VERSION ""

NS_ :

BS_:

BU_: NBICU SBICU NBCMU SBCMU DAPP Vector_XXX

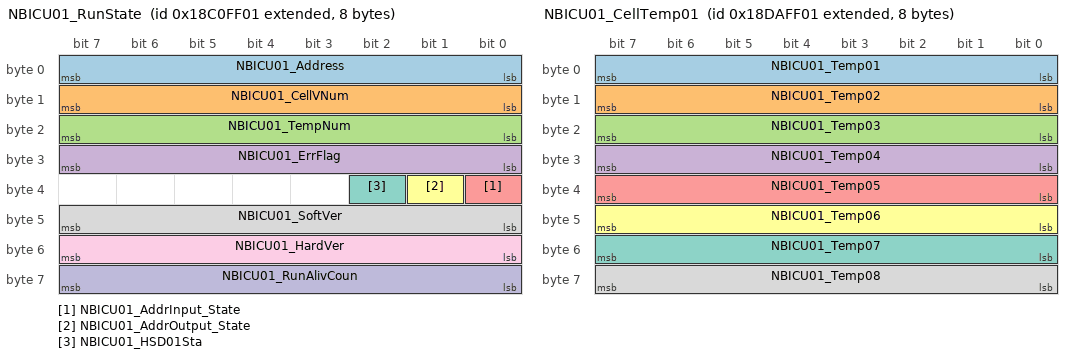
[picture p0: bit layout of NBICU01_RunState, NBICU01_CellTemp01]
BO_ 2562785025 NBICU01_RunState: 8 NBICU
 SG_ NBICU01_Address : 7|8@0+ (1,0) [0|255] ""  NBCMU
 SG_ NBICU01_CellVNum : 15|8@0+ (1,0) [0|255] ""  NBCMU
 SG_ NBICU01_TempNum : 23|8@0+ (1,0) [0|255] ""  NBCMU
 SG_ NBICU01_ErrFlag : 31|8@0+ (1,0) [0|255] ""  NBCMU
 SG_ NBICU01_AddrInput_State : 32|1@0+ (1,0) [0|1] ""  NBCMU
 SG_ NBICU01_AddrOutput_State : 33|1@0+ (1,0) [0|1] ""  NBCMU
 SG_ NBICU01_HSD01Sta : 34|1@0+ (1,0) [0|1] ""  NBCMU
 SG_ NBICU01_SoftVer : 47|8@0+ (1,0) [0|255] ""  NBCMU
 SG_ NBICU01_HardVer : 55|8@0+ (1,0) [0|255] ""  NBCMU
 SG_ NBICU01_RunAlivCoun : 63|8@0+ (1,0) [0|255] ""  NBCMU

BO_ 2562850561 NBICU01_VoltExtremeInfo: 8 NBICU
 SG_ NBICU01_CellVoltMax : 7|16@0+ (1,0) [0|65535] "mV"  NBCMU,SBCMU
 SG_ NBICU01_CellVoltMin : 23|16@0+ (1,0) [0|65535] "mV"  NBCMU,SBCMU
 SG_ NBICU01_CellVoltMaxCode : 39|8@0+ (1,0) [0|255] ""  NBCMU,SBCMU
 SG_ NBICU01_CellVoltMinCode : 47|8@0+ (1,0) [0|255] ""  NBCMU,SBCMU
 SG_ NBICU01_CellSumVolt : 55|16@0+ (0.1,0) [0|6553.5] "V"  NBCMU,SBCMU

BO_ 2562916097 NBICU01_TempExtremeInfo: 8 NBICU
 SG_ NBICU01_CellTempMax : 7|8@0+ (1,-40) [-40|215] "℃"  NBCMU,SBCMU
 SG_ NBICU01_CellTempMin : 15|8@0+ (1,-40) [-40|215] "℃"  NBCMU,SBCMU
 SG_ NBICU01_CellTempAvg : 23|8@0+ (1,-40) [-40|215] "℃"  NBCMU,SBCMU
 SG_ NBICU01_CellTempMaxCode : 31|8@0+ (1,0) [0|255] ""  NBCMU,SBCMU
 SG_ NBICU01_CellTempMinCode : 39|8@0+ (1,0) [0|255] ""  NBCMU,SBCMU
 SG_ NBICU01_SupplyVolt : 40|9@0+ (0.1,0) [0|51.1] "V"  NBCMU,SBCMU
 SG_ NBICU01_PCB_Temp : 63|8@0+ (1,-40) [-40|215] "℃"  NBCMU,SBCMU

BO_ 2562981633 NBICU01_BalState: 8 NBICU
 SG_ NBICU01_Cell0108BalaSta : 7|8@0+ (1,0) [0|255] ""  NBCMU
 SG_ NBICU01_Cell0916BalaSta : 15|8@0+ (1,0) [0|255] ""  NBCMU
 SG_ NBICU01_Cell1724BalaSta : 23|8@0+ (1,0) [0|255] ""  NBCMU
 SG_ NBICU01_Cell2532BalaSta : 31|8@0+ (1,0) [0|255] ""  NBCMU
 SG_ NBICU01_Cell3336BalaSta : 35|4@0+ (1,0) [0|15] ""  NBCMU
 SG_ NBICU01_SysSOH : 47|8@0+ (1,0) [0|100] "%"  NBCMU
 SG_ NBICU01_CycleTime : 55|16@0+ (1,0) [0|65535] ""  NBCMU

BO_ 2563899137 NBICU01_CellVotlage01: 8 NBICU
 SG_ NBICU01_Cell01Volt : 7|16@0+ (1,0) [0|65535] "mV"  NBCMU
 SG_ NBICU01_Cell02Volt : 23|16@0+ (1,0) [0|65535] "mV"  NBCMU
 SG_ NBICU01_Cell03Volt : 39|16@0+ (1,0) [0|65535] "mV"  NBCMU
 SG_ NBICU01_Cell04Volt : 55|16@0+ (1,0) [0|65535] "mV"  NBCMU

BO_ 2563964673 NBICU01_CellVotlage02: 8 NBICU
 SG_ NBICU01_Cell05Volt : 7|16@0+ (1,0) [0|65535] "mV"  NBCMU
 SG_ NBICU01_Cell06Volt : 23|16@0+ (1,0) [0|65535] "mV"  NBCMU
 SG_ NBICU01_Cell07Volt : 39|16@0+ (1,0) [0|65535] "mV"  NBCMU
 SG_ NBICU01_Cell08Volt : 55|16@0+ (1,0) [0|65535] "mV"  NBCMU

BO_ 2564030209 NBICU01_CellVotlage03: 8 NBICU
 SG_ NBICU01_Cell09Volt : 7|16@0+ (1,0) [0|65535] "mV"  NBCMU
 SG_ NBICU01_Cell10Volt : 23|16@0+ (1,0) [0|65535] "mV"  NBCMU
 SG_ NBICU01_Cell11Volt : 39|16@0+ (1,0) [0|65535] "mV"  NBCMU
 SG_ NBICU01_Cell12Volt : 55|16@0+ (1,0) [0|65535] "mV"  NBCMU

BO_ 2564095745 NBICU01_CellVotlage04: 8 NBICU
 SG_ NBICU01_Cell13Volt : 7|16@0+ (1,0) [0|65535] "mV"  NBCMU
 SG_ NBICU01_Cell14Volt : 23|16@0+ (1,0) [0|65535] "mV"  NBCMU
 SG_ NBICU01_Cell15Volt : 39|16@0+ (1,0) [0|65535] "mV"  NBCMU
 SG_ NBICU01_Cell16Volt : 55|16@0+ (1,0) [0|65535] "mV"  NBCMU

BO_ 2564161281 NBICU01_CellVotlage05: 8 NBICU
 SG_ NBICU01_Cell17Volt : 7|16@0+ (1,0) [0|65535] "mV"  NBCMU
 SG_ NBICU01_Cell18Volt : 23|16@0+ (1,0) [0|65535] "mV"  NBCMU
 SG_ NBICU01_Cell19Volt : 39|16@0+ (1,0) [0|65535] "mV"  NBCMU
 SG_ NBICU01_Cell20Volt : 55|16@0+ (1,0) [0|65535] "mV"  NBCMU

BO_ 2564226817 NBICU01_CellVotlage06: 8 NBICU
 SG_ NBICU01_Cell21Volt : 7|16@0+ (1,0) [0|65535] "mV"  NBCMU
 SG_ NBICU01_Cell22Volt : 23|16@0+ (1,0) [0|65535] "mV"  NBCMU
 SG_ NBICU01_Cell23Volt : 39|16@0+ (1,0) [0|65535] "mV"  NBCMU
 SG_ NBICU01_Cell24Volt : 55|16@0+ (1,0) [0|65535] "mV"  NBCMU

BO_ 2564292353 NBICU01_CellVotlage07: 8 NBICU
 SG_ NBICU01_Cell25Volt : 7|16@0+ (1,0) [0|65535] "mV"  NBCMU
 SG_ NBICU01_Cell26Volt : 23|16@0+ (1,0) [0|65535] "mV"  NBCMU
 SG_ NBICU01_Cell27Volt : 39|16@0+ (1,0) [0|65535] "mV"  NBCMU
 SG_ NBICU01_Cell28Volt : 55|16@0+ (1,0) [0|65535] "mV"  NBCMU

BO_ 2564357889 NBICU01_CellVotlage08: 8 NBICU
 SG_ NBICU01_Cell29Volt : 7|16@0+ (1,0) [0|65535] "mV"  NBCMU
 SG_ NBICU01_Cell30Volt : 23|16@0+ (1,0) [0|65535] "mV"  NBCMU
 SG_ NBICU01_Cell31Volt : 39|16@0+ (1,0) [0|65535] "mV"  NBCMU
 SG_ NBICU01_Cell32Volt : 55|16@0+ (1,0) [0|65535] "mV"  NBCMU

BO_ 2564423425 NBICU01_CellVotlage09: 8 NBICU
 SG_ NBICU01_Cell33Volt : 7|16@0+ (1,0) [0|65535] "mV"  NBCMU
 SG_ NBICU01_Cell34Volt : 23|16@0+ (1,0) [0|65535] "mV"  NBCMU
 SG_ NBICU01_Cell35Volt : 39|16@0+ (1,0) [0|65535] "mV"  NBCMU
 SG_ NBICU01_Cell36Volt : 55|16@0+ (1,0) [0|65535] "mV"  NBCMU

BO_ 2564488961 NBICU01_CellTemp01: 8 NBICU
 SG_ NBICU01_Temp01 : 7|8@0+ (1,-40) [-40|215] "℃"  NBCMU
 SG_ NBICU01_Temp02 : 15|8@0+ (1,-40) [-40|215] "℃"  NBCMU
 SG_ NBICU01_Temp03 : 23|8@0+ (1,-40) [-40|215] "℃"  NBCMU
 SG_ NBICU01_Temp04 : 31|8@0+ (1,-40) [-40|215] "℃"  NBCMU
 SG_ NBICU01_Temp05 : 39|8@0+ (1,-40) [-40|215] "℃"  NBCMU
 SG_ NBICU01_Temp06 : 47|8@0+ (1,-40) [-40|215] "℃"  NBCMU
 SG_ NBICU01_Temp07 : 55|8@0+ (1,-40) [-40|215] "℃"  NBCMU
 SG_ NBICU01_Temp08 : 63|8@0+ (1,-40) [-40|215] "℃"  NBCMU

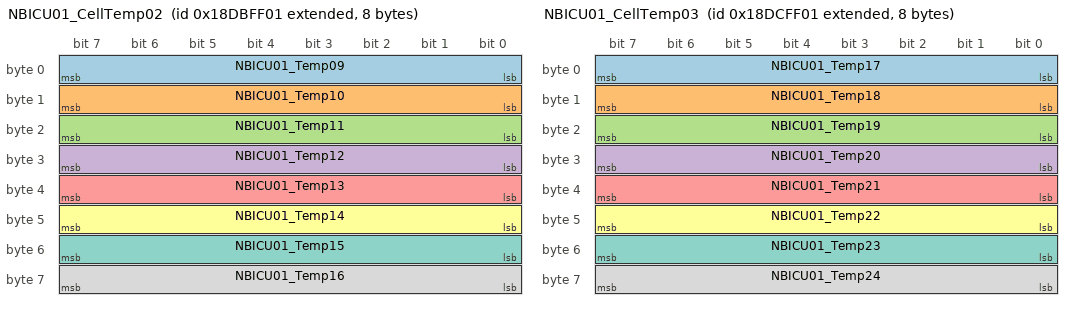
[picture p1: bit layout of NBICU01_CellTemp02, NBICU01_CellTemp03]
BO_ 2564554497 NBICU01_CellTemp02: 8 NBICU
 SG_ NBICU01_Temp09 : 7|8@0+ (1,-40) [-40|215] "℃"  NBCMU
 SG_ NBICU01_Temp10 : 15|8@0+ (1,-40) [-40|215] "℃"  NBCMU
 SG_ NBICU01_Temp11 : 23|8@0+ (1,-40) [-40|215] "℃"  NBCMU
 SG_ NBICU01_Temp12 : 31|8@0+ (1,-40) [-40|215] "℃"  NBCMU
 SG_ NBICU01_Temp13 : 39|8@0+ (1,-40) [-40|215] "℃"  NBCMU
 SG_ NBICU01_Temp14 : 47|8@0+ (1,-40) [-40|215] "℃"  NBCMU
 SG_ NBICU01_Temp15 : 55|8@0+ (1,-40) [-40|215] "℃"  NBCMU
 SG_ NBICU01_Temp16 : 63|8@0+ (1,-40) [-40|215] "℃"  NBCMU

BO_ 2564620033 NBICU01_CellTemp03: 8 NBICU
 SG_ NBICU01_Temp17 : 7|8@0+ (1,-40) [-40|215] "℃"  NBCMU
 SG_ NBICU01_Temp18 : 15|8@0+ (1,-40) [-40|215] "℃"  NBCMU
 SG_ NBICU01_Temp19 : 23|8@0+ (1,-40) [-40|215] "℃"  NBCMU
 SG_ NBICU01_Temp20 : 31|8@0+ (1,-40) [-40|215] "℃"  NBCMU
 SG_ NBICU01_Temp21 : 39|8@0+ (1,-40) [-40|215] "℃"  NBCMU
 SG_ NBICU01_Temp22 : 47|8@0+ (1,-40) [-40|215] "℃"  NBCMU
 SG_ NBICU01_Temp23 : 55|8@0+ (1,-40) [-40|215] "℃"  NBCMU
 SG_ NBICU01_Temp24 : 63|8@0+ (1,-40) [-40|215] "℃"  NBCMU

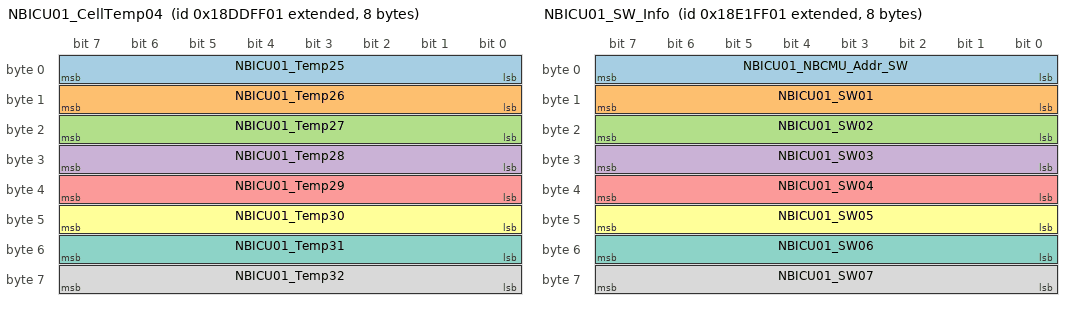
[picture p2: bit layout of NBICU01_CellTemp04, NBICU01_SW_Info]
BO_ 2564685569 NBICU01_CellTemp04: 8 NBICU
 SG_ NBICU01_Temp25 : 7|8@0+ (1,-40) [-40|215] "℃"  NBCMU
 SG_ NBICU01_Temp26 : 15|8@0+ (1,-40) [-40|215] "℃"  NBCMU
 SG_ NBICU01_Temp27 : 23|8@0+ (1,-40) [-40|215] "℃"  NBCMU
 SG_ NBICU01_Temp28 : 31|8@0+ (1,-40) [-40|215] "℃"  NBCMU
 SG_ NBICU01_Temp29 : 39|8@0+ (1,-40) [-40|215] "℃"  NBCMU
 SG_ NBICU01_Temp30 : 47|8@0+ (1,-40) [-40|215] "℃"  NBCMU
 SG_ NBICU01_Temp31 : 55|8@0+ (1,-40) [-40|215] "℃"  NBCMU
 SG_ NBICU01_Temp32 : 63|8@0+ (1,-40) [-40|215] "℃"  NBCMU

BO_ 2564751105 NBICU01_CellTemp05: 8 NBICU
 SG_ NBICU01_Temp33 : 7|8@0+ (1,-40) [-40|215] "℃"  NBCMU
 SG_ NBICU01_Temp34 : 15|8@0+ (1,-40) [-40|215] "℃"  NBCMU
 SG_ NBICU01_Temp35 : 23|8@0+ (1,-40) [-40|215] "℃"  NBCMU
 SG_ NBICU01_Temp36 : 31|8@0+ (1,-40) [-40|215] "℃"  NBCMU

BO_ 2564947713 NBICU01_SW_Info: 8 NBICU
 SG_ NBICU01_NBCMU_Addr_SW : 7|8@0+ (1,0) [0|255] ""  NBCMU
 SG_ NBICU01_SW01 : 15|8@0+ (1,0) [0|255] ""  NBCMU
 SG_ NBICU01_SW02 : 23|8@0+ (1,0) [0|255] ""  NBCMU
 SG_ NBICU01_SW03 : 31|8@0+ (1,0) [0|255] ""  NBCMU
 SG_ NBICU01_SW04 : 39|8@0+ (1,0) [0|255] ""  NBCMU
 SG_ NBICU01_SW05 : 47|8@0+ (1,0) [0|255] ""  NBCMU
 SG_ NBICU01_SW06 : 55|8@0+ (1,0) [0|255] ""  NBCMU
 SG_ NBICU01_SW07 : 63|8@0+ (1,0) [0|255] ""  NBCMU

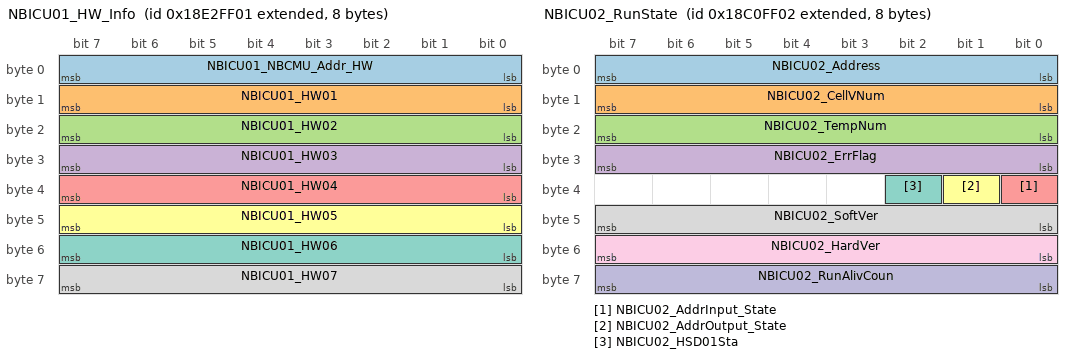
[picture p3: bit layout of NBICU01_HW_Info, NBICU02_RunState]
BO_ 2565013249 NBICU01_HW_Info: 8 NBICU
 SG_ NBICU01_NBCMU_Addr_HW : 7|8@0+ (1,0) [0|255] ""  NBCMU
 SG_ NBICU01_HW01 : 15|8@0+ (1,0) [0|255] ""  NBCMU
 SG_ NBICU01_HW02 : 23|8@0+ (1,0) [0|255] ""  NBCMU
 SG_ NBICU01_HW03 : 31|8@0+ (1,0) [0|255] ""  NBCMU
 SG_ NBICU01_HW04 : 39|8@0+ (1,0) [0|255] ""  NBCMU
 SG_ NBICU01_HW05 : 47|8@0+ (1,0) [0|255] ""  NBCMU
 SG_ NBICU01_HW06 : 55|8@0+ (1,0) [0|255] ""  NBCMU
 SG_ NBICU01_HW07 : 63|8@0+ (1,0) [0|255] ""  NBCMU

BO_ 2564677377 NBICU01_DiaResponse: 8 NBICU
 SG_ NBICU01_RespData : 7|64@0+ (1,0) [0|1.84467440737096E+019] ""  DAPP

BO_ 2562785026 NBICU02_RunState: 8 NBICU
 SG_ NBICU02_Address : 7|8@0+ (1,0) [0|255] ""  NBCMU
 SG_ NBICU02_CellVNum : 15|8@0+ (1,0) [0|255] ""  NBCMU
 SG_ NBICU02_TempNum : 23|8@0+ (1,0) [0|255] ""  NBCMU
 SG_ NBICU02_ErrFlag : 31|8@0+ (1,0) [0|255] ""  NBCMU
 SG_ NBICU02_AddrInput_State : 32|1@0+ (1,0) [0|1] ""  NBCMU
 SG_ NBICU02_AddrOutput_State : 33|1@0+ (1,0) [0|1] ""  NBCMU
 SG_ NBICU02_HSD01Sta : 34|1@0+ (1,0) [0|1] ""  NBCMU
 SG_ NBICU02_SoftVer : 47|8@0+ (1,0) [0|255] ""  NBCMU
 SG_ NBICU02_HardVer : 55|8@0+ (1,0) [0|255] ""  NBCMU
 SG_ NBICU02_RunAlivCoun : 63|8@0+ (1,0) [0|255] ""  NBCMU

BO_ 2562850562 NBICU02_VoltExtremeInfo: 8 NBICU
 SG_ NBICU02_CellVoltMax : 7|16@0+ (1,0) [0|65535] "mV"  NBCMU,SBCMU
 SG_ NBICU02_CellVoltMin : 23|16@0+ (1,0) [0|65535] "mV"  NBCMU,SBCMU
 SG_ NBICU02_CellVoltMaxCode : 39|8@0+ (1,0) [0|255] ""  NBCMU,SBCMU
 SG_ NBICU02_CellVoltMinCode : 47|8@0+ (1,0) [0|255] ""  NBCMU,SBCMU
 SG_ NBICU02_CellSumVolt : 55|16@0+ (0.1,0) [0|6553.5] "V"  NBCMU,SBCMU

BO_ 2562916098 NBICU02_TempExtremeInfo: 8 NBICU
 SG_ NBICU02_CellTempMax : 7|8@0+ (1,-40) [-40|215] "℃"  NBCMU,SBCMU
 SG_ NBICU02_CellTempMin : 15|8@0+ (1,-40) [-40|215] "℃"  NBCMU,SBCMU
 SG_ NBICU02_CellTempAvg : 23|8@0+ (1,-40) [-40|215] "℃"  NBCMU,SBCMU
 SG_ NBICU02_CellTempMaxCode : 31|8@0+ (1,0) [0|255] ""  NBCMU,SBCMU
 SG_ NBICU02_CellTempMinCode : 39|8@0+ (1,0) [0|255] ""  NBCMU,SBCMU
 SG_ NBICU02_SupplyVolt : 40|9@0+ (0.1,0) [0|51.1] "V"  NBCMU,SBCMU
 SG_ NBICU02_PCB_Temp : 63|8@0+ (1,-40) [-40|215] "℃"  NBCMU,SBCMU

BO_ 2562981634 NBICU02_BalState: 8 NBICU
 SG_ NBICU02_Cell0108BalaSta : 7|8@0+ (1,0) [0|255] ""  NBCMU
 SG_ NBICU02_Cell0916BalaSta : 15|8@0+ (1,0) [0|255] ""  NBCMU
 SG_ NBICU02_Cell1724BalaSta : 23|8@0+ (1,0) [0|255] ""  NBCMU
 SG_ NBICU02_Cell2532BalaSta : 31|8@0+ (1,0) [0|255] ""  NBCMU
 SG_ NBICU02_Cell3336BalaSta : 35|4@0+ (1,0) [0|15] ""  NBCMU
 SG_ NBICU02_SysSOH : 47|8@0+ (1,0) [0|100] "%"  NBCMU
 SG_ NBICU02_CycleTime : 55|16@0+ (1,0) [0|65535] ""  NBCMU

BO_ 2563899138 NBICU02_CellVotlage01: 8 NBICU
 SG_ NBICU02_Cell01Volt : 7|16@0+ (1,0) [0|65535] "mV"  NBCMU
 SG_ NBICU02_Cell02Volt : 23|16@0+ (1,0) [0|65535] "mV"  NBCMU
 SG_ NBICU02_Cell03Volt : 39|16@0+ (1,0) [0|65535] "mV"  NBCMU
 SG_ NBICU02_Cell04Volt : 55|16@0+ (1,0) [0|65535] "mV"  NBCMU

BO_ 2563964674 NBICU02_CellVotlage02: 8 NBICU
 SG_ NBICU02_Cell05Volt : 7|16@0+ (1,0) [0|65535] "mV"  NBCMU
 SG_ NBICU02_Cell06Volt : 23|16@0+ (1,0) [0|65535] "mV"  NBCMU
 SG_ NBICU02_Cell07Volt : 39|16@0+ (1,0) [0|65535] "mV"  NBCMU
 SG_ NBICU02_Cell08Volt : 55|16@0+ (1,0) [0|65535] "mV"  NBCMU

BO_ 2564030210 NBICU02_CellVotlage03: 8 NBICU
 SG_ NBICU02_Cell09Volt : 7|16@0+ (1,0) [0|65535] "mV"  NBCMU
 SG_ NBICU02_Cell10Volt : 23|16@0+ (1,0) [0|65535] "mV"  NBCMU
 SG_ NBICU02_Cell11Volt : 39|16@0+ (1,0) [0|65535] "mV"  NBCMU
 SG_ NBICU02_Cell12Volt : 55|16@0+ (1,0) [0|65535] "mV"  NBCMU

BO_ 2564095746 NBICU02_CellVotlage04: 8 NBICU
 SG_ NBICU02_Cell13Volt : 7|16@0+ (1,0) [0|65535] "mV"  NBCMU
 SG_ NBICU02_Cell14Volt : 23|16@0+ (1,0) [0|65535] "mV"  NBCMU
 SG_ NBICU02_Cell15Volt : 39|16@0+ (1,0) [0|65535] "mV"  NBCMU
 SG_ NBICU02_Cell16Volt : 55|16@0+ (1,0) [0|65535] "mV"  NBCMU

BO_ 2564161282 NBICU02_CellVotlage05: 8 NBICU
 SG_ NBICU02_Cell17Volt : 7|16@0+ (1,0) [0|65535] "mV"  NBCMU
 SG_ NBICU02_Cell18Volt : 23|16@0+ (1,0) [0|65535] "mV"  NBCMU
 SG_ NBICU02_Cell19Volt : 39|16@0+ (1,0) [0|65535] "mV"  NBCMU
 SG_ NBICU02_Cell20Volt : 55|16@0+ (1,0) [0|65535] "mV"  NBCMU

BO_ 2564226818 NBICU02_CellVotlage06: 8 NBICU
 SG_ NBICU02_Cell21Volt : 7|16@0+ (1,0) [0|65535] "mV"  NBCMU
 SG_ NBICU02_Cell22Volt : 23|16@0+ (1,0) [0|65535] "mV"  NBCMU
 SG_ NBICU02_Cell23Volt : 39|16@0+ (1,0) [0|65535] "mV"  NBCMU
 SG_ NBICU02_Cell24Volt : 55|16@0+ (1,0) [0|65535] "mV"  NBCMU

BO_ 2564292354 NBICU02_CellVotlage07: 8 NBICU
 SG_ NBICU02_Cell25Volt : 7|16@0+ (1,0) [0|65535] "mV"  NBCMU
 SG_ NBICU02_Cell26Volt : 23|16@0+ (1,0) [0|65535] "mV"  NBCMU
 SG_ NBICU02_Cell27Volt : 39|16@0+ (1,0) [0|65535] "mV"  NBCMU
 SG_ NBICU02_Cell28Volt : 55|16@0+ (1,0) [0|65535] "mV"  NBCMU

BO_ 2564357890 NBICU02_CellVotlage08: 8 NBICU
 SG_ NBICU02_Cell29Volt : 7|16@0+ (1,0) [0|65535] "mV"  NBCMU
 SG_ NBICU02_Cell30Volt : 23|16@0+ (1,0) [0|65535] "mV"  NBCMU
 SG_ NBICU02_Cell31Volt : 39|16@0+ (1,0) [0|65535] "mV"  NBCMU
 SG_ NBICU02_Cell32Volt : 55|16@0+ (1,0) [0|65535] "mV"  NBCMU

BO_ 2564423426 NBICU02_CellVotlage09: 8 NBICU
 SG_ NBICU02_Cell33Volt : 7|16@0+ (1,0) [0|65535] "mV"  NBCMU
 SG_ NBICU02_Cell34Volt : 23|16@0+ (1,0) [0|65535] "mV"  NBCMU
 SG_ NBICU02_Cell35Volt : 39|16@0+ (1,0) [0|65535] "mV"  NBCMU
 SG_ NBICU02_Cell36Volt : 55|16@0+ (1,0) [0|65535] "mV"  NBCMU

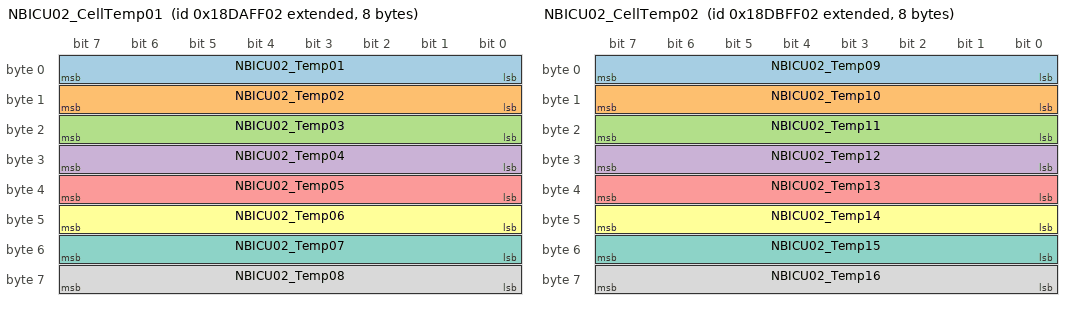
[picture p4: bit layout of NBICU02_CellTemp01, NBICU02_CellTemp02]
BO_ 2564488962 NBICU02_CellTemp01: 8 NBICU
 SG_ NBICU02_Temp01 : 7|8@0+ (1,-40) [-40|215] "℃"  NBCMU
 SG_ NBICU02_Temp02 : 15|8@0+ (1,-40) [-40|215] "℃"  NBCMU
 SG_ NBICU02_Temp03 : 23|8@0+ (1,-40) [-40|215] "℃"  NBCMU
 SG_ NBICU02_Temp04 : 31|8@0+ (1,-40) [-40|215] "℃"  NBCMU
 SG_ NBICU02_Temp05 : 39|8@0+ (1,-40) [-40|215] "℃"  NBCMU
 SG_ NBICU02_Temp06 : 47|8@0+ (1,-40) [-40|215] "℃"  NBCMU
 SG_ NBICU02_Temp07 : 55|8@0+ (1,-40) [-40|215] "℃"  NBCMU
 SG_ NBICU02_Temp08 : 63|8@0+ (1,-40) [-40|215] "℃"  NBCMU

BO_ 2564554498 NBICU02_CellTemp02: 8 NBICU
 SG_ NBICU02_Temp09 : 7|8@0+ (1,-40) [-40|215] "℃"  NBCMU
 SG_ NBICU02_Temp10 : 15|8@0+ (1,-40) [-40|215] "℃"  NBCMU
 SG_ NBICU02_Temp11 : 23|8@0+ (1,-40) [-40|215] "℃"  NBCMU
 SG_ NBICU02_Temp12 : 31|8@0+ (1,-40) [-40|215] "℃"  NBCMU
 SG_ NBICU02_Temp13 : 39|8@0+ (1,-40) [-40|215] "℃"  NBCMU
 SG_ NBICU02_Temp14 : 47|8@0+ (1,-40) [-40|215] "℃"  NBCMU
 SG_ NBICU02_Temp15 : 55|8@0+ (1,-40) [-40|215] "℃"  NBCMU
 SG_ NBICU02_Temp16 : 63|8@0+ (1,-40) [-40|215] "℃"  NBCMU

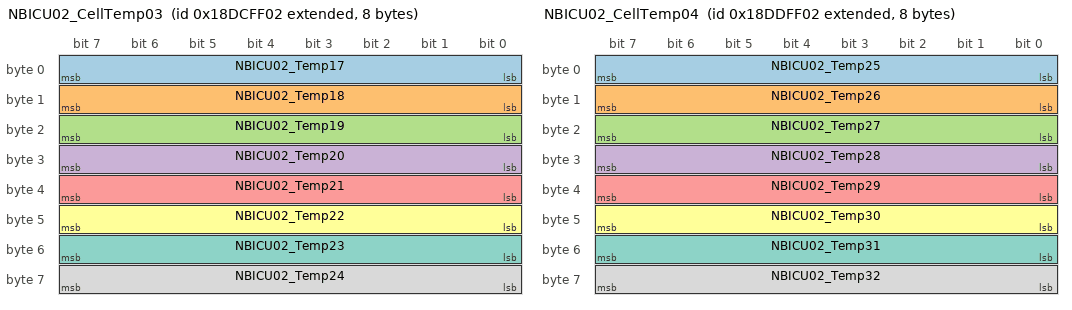
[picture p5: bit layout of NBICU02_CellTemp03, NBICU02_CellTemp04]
BO_ 2564620034 NBICU02_CellTemp03: 8 NBICU
 SG_ NBICU02_Temp17 : 7|8@0+ (1,-40) [-40|215] "℃"  NBCMU
 SG_ NBICU02_Temp18 : 15|8@0+ (1,-40) [-40|215] "℃"  NBCMU
 SG_ NBICU02_Temp19 : 23|8@0+ (1,-40) [-40|215] "℃"  NBCMU
 SG_ NBICU02_Temp20 : 31|8@0+ (1,-40) [-40|215] "℃"  NBCMU
 SG_ NBICU02_Temp21 : 39|8@0+ (1,-40) [-40|215] "℃"  NBCMU
 SG_ NBICU02_Temp22 : 47|8@0+ (1,-40) [-40|215] "℃"  NBCMU
 SG_ NBICU02_Temp23 : 55|8@0+ (1,-40) [-40|215] "℃"  NBCMU
 SG_ NBICU02_Temp24 : 63|8@0+ (1,-40) [-40|215] "℃"  NBCMU

BO_ 2564685570 NBICU02_CellTemp04: 8 NBICU
 SG_ NBICU02_Temp25 : 7|8@0+ (1,-40) [-40|215] "℃"  NBCMU
 SG_ NBICU02_Temp26 : 15|8@0+ (1,-40) [-40|215] "℃"  NBCMU
 SG_ NBICU02_Temp27 : 23|8@0+ (1,-40) [-40|215] "℃"  NBCMU
 SG_ NBICU02_Temp28 : 31|8@0+ (1,-40) [-40|215] "℃"  NBCMU
 SG_ NBICU02_Temp29 : 39|8@0+ (1,-40) [-40|215] "℃"  NBCMU
 SG_ NBICU02_Temp30 : 47|8@0+ (1,-40) [-40|215] "℃"  NBCMU
 SG_ NBICU02_Temp31 : 55|8@0+ (1,-40) [-40|215] "℃"  NBCMU
 SG_ NBICU02_Temp32 : 63|8@0+ (1,-40) [-40|215] "℃"  NBCMU

BO_ 2564751106 NBICU02_CellTemp05: 8 NBICU
 SG_ NBICU02_Temp33 : 7|8@0+ (1,-40) [-40|215] "℃"  NBCMU
 SG_ NBICU02_Temp34 : 15|8@0+ (1,-40) [-40|215] "℃"  NBCMU
 SG_ NBICU02_Temp35 : 23|8@0+ (1,-40) [-40|215] "℃"  NBCMU
 SG_ NBICU02_Temp36 : 31|8@0+ (1,-40) [-40|215] "℃"  NBCMU

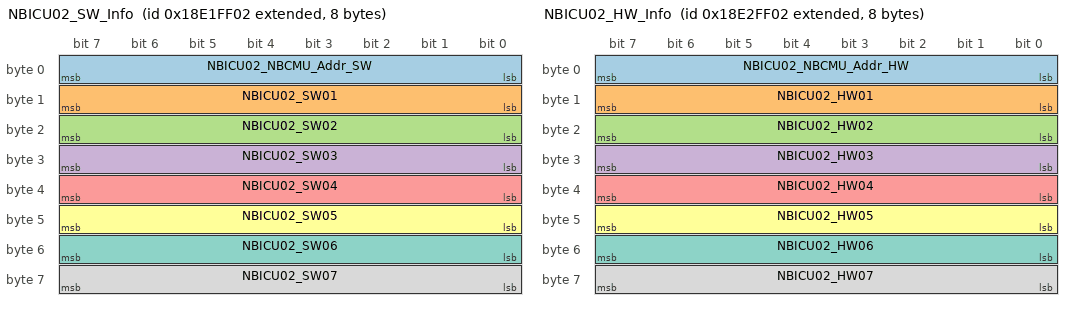
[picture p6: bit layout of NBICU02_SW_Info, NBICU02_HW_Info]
BO_ 2564947714 NBICU02_SW_Info: 8 NBICU
 SG_ NBICU02_NBCMU_Addr_SW : 7|8@0+ (1,0) [0|255] ""  NBCMU
 SG_ NBICU02_SW01 : 15|8@0+ (1,0) [0|255] ""  NBCMU
 SG_ NBICU02_SW02 : 23|8@0+ (1,0) [0|255] ""  NBCMU
 SG_ NBICU02_SW03 : 31|8@0+ (1,0) [0|255] ""  NBCMU
 SG_ NBICU02_SW04 : 39|8@0+ (1,0) [0|255] ""  NBCMU
 SG_ NBICU02_SW05 : 47|8@0+ (1,0) [0|255] ""  NBCMU
 SG_ NBICU02_SW06 : 55|8@0+ (1,0) [0|255] ""  NBCMU
 SG_ NBICU02_SW07 : 63|8@0+ (1,0) [0|255] ""  NBCMU

BO_ 2565013250 NBICU02_HW_Info: 8 NBICU
 SG_ NBICU02_NBCMU_Addr_HW : 7|8@0+ (1,0) [0|255] ""  NBCMU
 SG_ NBICU02_HW01 : 15|8@0+ (1,0) [0|255] ""  NBCMU
 SG_ NBICU02_HW02 : 23|8@0+ (1,0) [0|255] ""  NBCMU
 SG_ NBICU02_HW03 : 31|8@0+ (1,0) [0|255] ""  NBCMU
 SG_ NBICU02_HW04 : 39|8@0+ (1,0) [0|255] ""  NBCMU
 SG_ NBICU02_HW05 : 47|8@0+ (1,0) [0|255] ""  NBCMU
 SG_ NBICU02_HW06 : 55|8@0+ (1,0) [0|255] ""  NBCMU
 SG_ NBICU02_HW07 : 63|8@0+ (1,0) [0|255] ""  NBCMU

BO_ 2564677378 NBICU02_DiaResponse: 8 NBICU
 SG_ NBICU02_RespData : 7|64@0+ (1,0) [0|1.84467440737096E+019] ""  DAPP

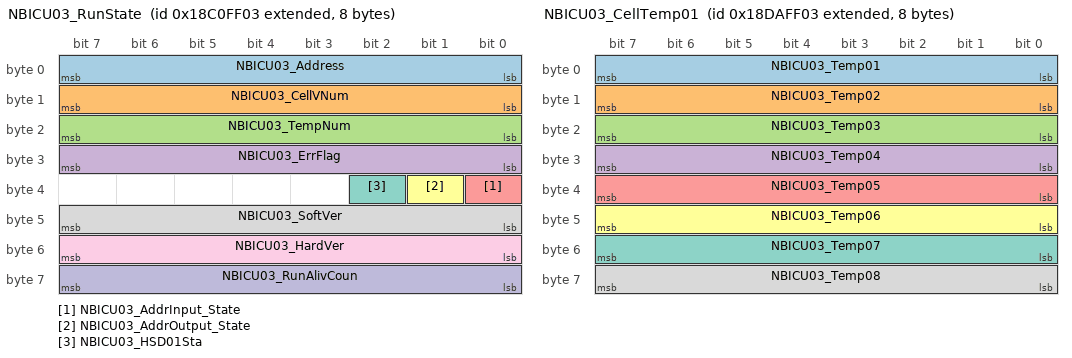
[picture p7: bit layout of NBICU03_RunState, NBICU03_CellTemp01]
BO_ 2562785027 NBICU03_RunState: 8 NBICU
 SG_ NBICU03_Address : 7|8@0+ (1,0) [0|255] ""  NBCMU
 SG_ NBICU03_CellVNum : 15|8@0+ (1,0) [0|255] ""  NBCMU
 SG_ NBICU03_TempNum : 23|8@0+ (1,0) [0|255] ""  NBCMU
 SG_ NBICU03_ErrFlag : 31|8@0+ (1,0) [0|255] ""  NBCMU
 SG_ NBICU03_AddrInput_State : 32|1@0+ (1,0) [0|1] ""  NBCMU
 SG_ NBICU03_AddrOutput_State : 33|1@0+ (1,0) [0|1] ""  NBCMU
 SG_ NBICU03_HSD01Sta : 34|1@0+ (1,0) [0|1] ""  NBCMU
 SG_ NBICU03_SoftVer : 47|8@0+ (1,0) [0|255] ""  NBCMU
 SG_ NBICU03_HardVer : 55|8@0+ (1,0) [0|255] ""  NBCMU
 SG_ NBICU03_RunAlivCoun : 63|8@0+ (1,0) [0|255] ""  NBCMU

BO_ 2562850563 NBICU03_VoltExtremeInfo: 8 NBICU
 SG_ NBICU03_CellVoltMax : 7|16@0+ (1,0) [0|65535] "mV"  NBCMU,SBCMU
 SG_ NBICU03_CellVoltMin : 23|16@0+ (1,0) [0|65535] "mV"  NBCMU,SBCMU
 SG_ NBICU03_CellVoltMaxCode : 39|8@0+ (1,0) [0|255] ""  NBCMU,SBCMU
 SG_ NBICU03_CellVoltMinCode : 47|8@0+ (1,0) [0|255] ""  NBCMU,SBCMU
 SG_ NBICU03_CellSumVolt : 55|16@0+ (0.1,0) [0|6553.5] "V"  NBCMU,SBCMU

BO_ 2562916099 NBICU03_TempExtremeInfo: 8 NBICU
 SG_ NBICU03_CellTempMax : 7|8@0+ (1,-40) [-40|215] "℃"  NBCMU,SBCMU
 SG_ NBICU03_CellTempMin : 15|8@0+ (1,-40) [-40|215] "℃"  NBCMU,SBCMU
 SG_ NBICU03_CellTempAvg : 23|8@0+ (1,-40) [-40|215] "℃"  NBCMU,SBCMU
 SG_ NBICU03_CellTempMaxCode : 31|8@0+ (1,0) [0|255] ""  NBCMU,SBCMU
 SG_ NBICU03_CellTempMinCode : 39|8@0+ (1,0) [0|255] ""  NBCMU,SBCMU
 SG_ NBICU03_SupplyVolt : 40|9@0+ (0.1,0) [0|51.1] "V"  NBCMU,SBCMU
 SG_ NBICU03_PCB_Temp : 63|8@0+ (1,-40) [-40|215] "℃"  NBCMU,SBCMU

BO_ 2562981635 NBICU03_BalState: 8 NBICU
 SG_ NBICU03_Cell0108BalaSta : 7|8@0+ (1,0) [0|255] ""  NBCMU
 SG_ NBICU03_Cell0916BalaSta : 15|8@0+ (1,0) [0|255] ""  NBCMU
 SG_ NBICU03_Cell1724BalaSta : 23|8@0+ (1,0) [0|255] ""  NBCMU
 SG_ NBICU03_Cell2532BalaSta : 31|8@0+ (1,0) [0|255] ""  NBCMU
 SG_ NBICU03_Cell3336BalaSta : 35|4@0+ (1,0) [0|15] ""  NBCMU
 SG_ NBICU03_SysSOH : 47|8@0+ (1,0) [0|100] "%"  NBCMU
 SG_ NBICU03_CycleTime : 55|16@0+ (1,0) [0|65535] ""  NBCMU

BO_ 2563899139 NBICU03_CellVotlage01: 8 NBICU
 SG_ NBICU03_Cell01Volt : 7|16@0+ (1,0) [0|65535] "mV"  NBCMU
 SG_ NBICU03_Cell02Volt : 23|16@0+ (1,0) [0|65535] "mV"  NBCMU
 SG_ NBICU03_Cell03Volt : 39|16@0+ (1,0) [0|65535] "mV"  NBCMU
 SG_ NBICU03_Cell04Volt : 55|16@0+ (1,0) [0|65535] "mV"  NBCMU

BO_ 2563964675 NBICU03_CellVotlage02: 8 NBICU
 SG_ NBICU03_Cell05Volt : 7|16@0+ (1,0) [0|65535] "mV"  NBCMU
 SG_ NBICU03_Cell06Volt : 23|16@0+ (1,0) [0|65535] "mV"  NBCMU
 SG_ NBICU03_Cell07Volt : 39|16@0+ (1,0) [0|65535] "mV"  NBCMU
 SG_ NBICU03_Cell08Volt : 55|16@0+ (1,0) [0|65535] "mV"  NBCMU

BO_ 2564030211 NBICU03_CellVotlage03: 8 NBICU
 SG_ NBICU03_Cell09Volt : 7|16@0+ (1,0) [0|65535] "mV"  NBCMU
 SG_ NBICU03_Cell10Volt : 23|16@0+ (1,0) [0|65535] "mV"  NBCMU
 SG_ NBICU03_Cell11Volt : 39|16@0+ (1,0) [0|65535] "mV"  NBCMU
 SG_ NBICU03_Cell12Volt : 55|16@0+ (1,0) [0|65535] "mV"  NBCMU

BO_ 2564095747 NBICU03_CellVotlage04: 8 NBICU
 SG_ NBICU03_Cell13Volt : 7|16@0+ (1,0) [0|65535] "mV"  NBCMU
 SG_ NBICU03_Cell14Volt : 23|16@0+ (1,0) [0|65535] "mV"  NBCMU
 SG_ NBICU03_Cell15Volt : 39|16@0+ (1,0) [0|65535] "mV"  NBCMU
 SG_ NBICU03_Cell16Volt : 55|16@0+ (1,0) [0|65535] "mV"  NBCMU

BO_ 2564161283 NBICU03_CellVotlage05: 8 NBICU
 SG_ NBICU03_Cell17Volt : 7|16@0+ (1,0) [0|65535] "mV"  NBCMU
 SG_ NBICU03_Cell18Volt : 23|16@0+ (1,0) [0|65535] "mV"  NBCMU
 SG_ NBICU03_Cell19Volt : 39|16@0+ (1,0) [0|65535] "mV"  NBCMU
 SG_ NBICU03_Cell20Volt : 55|16@0+ (1,0) [0|65535] "mV"  NBCMU

BO_ 2564226819 NBICU03_CellVotlage06: 8 NBICU
 SG_ NBICU03_Cell21Volt : 7|16@0+ (1,0) [0|65535] "mV"  NBCMU
 SG_ NBICU03_Cell22Volt : 23|16@0+ (1,0) [0|65535] "mV"  NBCMU
 SG_ NBICU03_Cell23Volt : 39|16@0+ (1,0) [0|65535] "mV"  NBCMU
 SG_ NBICU03_Cell24Volt : 55|16@0+ (1,0) [0|65535] "mV"  NBCMU

BO_ 2564292355 NBICU03_CellVotlage07: 8 NBICU
 SG_ NBICU03_Cell25Volt : 7|16@0+ (1,0) [0|65535] "mV"  NBCMU
 SG_ NBICU03_Cell26Volt : 23|16@0+ (1,0) [0|65535] "mV"  NBCMU
 SG_ NBICU03_Cell27Volt : 39|16@0+ (1,0) [0|65535] "mV"  NBCMU
 SG_ NBICU03_Cell28Volt : 55|16@0+ (1,0) [0|65535] "mV"  NBCMU

BO_ 2564357891 NBICU03_CellVotlage08: 8 NBICU
 SG_ NBICU03_Cell29Volt : 7|16@0+ (1,0) [0|65535] "mV"  NBCMU
 SG_ NBICU03_Cell30Volt : 23|16@0+ (1,0) [0|65535] "mV"  NBCMU
 SG_ NBICU03_Cell31Volt : 39|16@0+ (1,0) [0|65535] "mV"  NBCMU
 SG_ NBICU03_Cell32Volt : 55|16@0+ (1,0) [0|65535] "mV"  NBCMU

BO_ 2564423427 NBICU03_CellVotlage09: 8 NBICU
 SG_ NBICU03_Cell33Volt : 7|16@0+ (1,0) [0|65535] "mV"  NBCMU
 SG_ NBICU03_Cell34Volt : 23|16@0+ (1,0) [0|65535] "mV"  NBCMU
 SG_ NBICU03_Cell35Volt : 39|16@0+ (1,0) [0|65535] "mV"  NBCMU
 SG_ NBICU03_Cell36Volt : 55|16@0+ (1,0) [0|65535] "mV"  NBCMU

BO_ 2564488963 NBICU03_CellTemp01: 8 NBICU
 SG_ NBICU03_Temp01 : 7|8@0+ (1,-40) [-40|215] "℃"  NBCMU
 SG_ NBICU03_Temp02 : 15|8@0+ (1,-40) [-40|215] "℃"  NBCMU
 SG_ NBICU03_Temp03 : 23|8@0+ (1,-40) [-40|215] "℃"  NBCMU
 SG_ NBICU03_Temp04 : 31|8@0+ (1,-40) [-40|215] "℃"  NBCMU
 SG_ NBICU03_Temp05 : 39|8@0+ (1,-40) [-40|215] "℃"  NBCMU
 SG_ NBICU03_Temp06 : 47|8@0+ (1,-40) [-40|215] "℃"  NBCMU
 SG_ NBICU03_Temp07 : 55|8@0+ (1,-40) [-40|215] "℃"  NBCMU
 SG_ NBICU03_Temp08 : 63|8@0+ (1,-40) [-40|215] "℃"  NBCMU

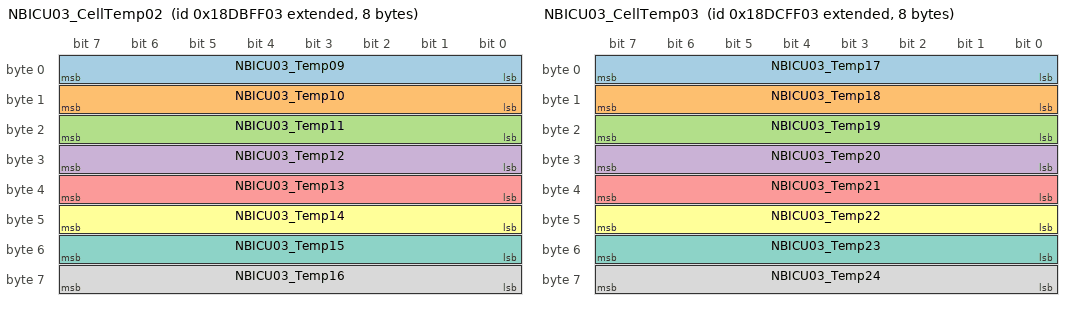
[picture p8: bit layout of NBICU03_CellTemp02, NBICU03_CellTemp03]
BO_ 2564554499 NBICU03_CellTemp02: 8 NBICU
 SG_ NBICU03_Temp09 : 7|8@0+ (1,-40) [-40|215] "℃"  NBCMU
 SG_ NBICU03_Temp10 : 15|8@0+ (1,-40) [-40|215] "℃"  NBCMU
 SG_ NBICU03_Temp11 : 23|8@0+ (1,-40) [-40|215] "℃"  NBCMU
 SG_ NBICU03_Temp12 : 31|8@0+ (1,-40) [-40|215] "℃"  NBCMU
 SG_ NBICU03_Temp13 : 39|8@0+ (1,-40) [-40|215] "℃"  NBCMU
 SG_ NBICU03_Temp14 : 47|8@0+ (1,-40) [-40|215] "℃"  NBCMU
 SG_ NBICU03_Temp15 : 55|8@0+ (1,-40) [-40|215] "℃"  NBCMU
 SG_ NBICU03_Temp16 : 63|8@0+ (1,-40) [-40|215] "℃"  NBCMU

BO_ 2564620035 NBICU03_CellTemp03: 8 NBICU
 SG_ NBICU03_Temp17 : 7|8@0+ (1,-40) [-40|215] "℃"  NBCMU
 SG_ NBICU03_Temp18 : 15|8@0+ (1,-40) [-40|215] "℃"  NBCMU
 SG_ NBICU03_Temp19 : 23|8@0+ (1,-40) [-40|215] "℃"  NBCMU
 SG_ NBICU03_Temp20 : 31|8@0+ (1,-40) [-40|215] "℃"  NBCMU
 SG_ NBICU03_Temp21 : 39|8@0+ (1,-40) [-40|215] "℃"  NBCMU
 SG_ NBICU03_Temp22 : 47|8@0+ (1,-40) [-40|215] "℃"  NBCMU
 SG_ NBICU03_Temp23 : 55|8@0+ (1,-40) [-40|215] "℃"  NBCMU
 SG_ NBICU03_Temp24 : 63|8@0+ (1,-40) [-40|215] "℃"  NBCMU

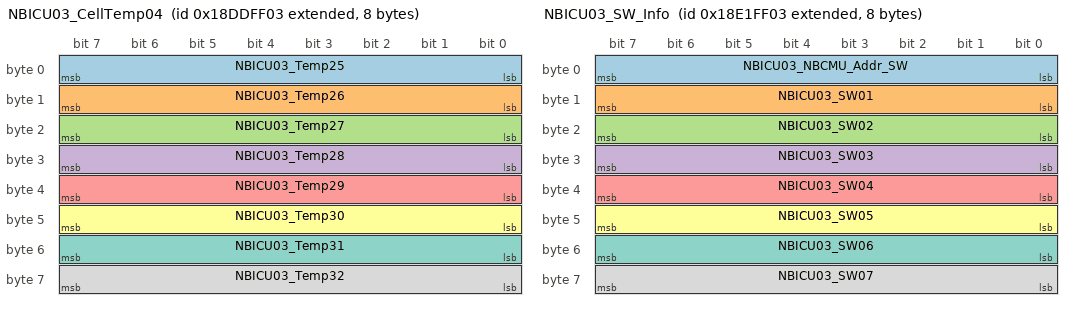
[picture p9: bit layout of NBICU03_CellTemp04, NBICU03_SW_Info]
BO_ 2564685571 NBICU03_CellTemp04: 8 NBICU
 SG_ NBICU03_Temp25 : 7|8@0+ (1,-40) [-40|215] "℃"  NBCMU
 SG_ NBICU03_Temp26 : 15|8@0+ (1,-40) [-40|215] "℃"  NBCMU
 SG_ NBICU03_Temp27 : 23|8@0+ (1,-40) [-40|215] "℃"  NBCMU
 SG_ NBICU03_Temp28 : 31|8@0+ (1,-40) [-40|215] "℃"  NBCMU
 SG_ NBICU03_Temp29 : 39|8@0+ (1,-40) [-40|215] "℃"  NBCMU
 SG_ NBICU03_Temp30 : 47|8@0+ (1,-40) [-40|215] "℃"  NBCMU
 SG_ NBICU03_Temp31 : 55|8@0+ (1,-40) [-40|215] "℃"  NBCMU
 SG_ NBICU03_Temp32 : 63|8@0+ (1,-40) [-40|215] "℃"  NBCMU

BO_ 2564751107 NBICU03_CellTemp05: 8 NBICU
 SG_ NBICU03_Temp33 : 7|8@0+ (1,-40) [-40|215] "℃"  NBCMU
 SG_ NBICU03_Temp34 : 15|8@0+ (1,-40) [-40|215] "℃"  NBCMU
 SG_ NBICU03_Temp35 : 23|8@0+ (1,-40) [-40|215] "℃"  NBCMU
 SG_ NBICU03_Temp36 : 31|8@0+ (1,-40) [-40|215] "℃"  NBCMU

BO_ 2564947715 NBICU03_SW_Info: 8 NBICU
 SG_ NBICU03_NBCMU_Addr_SW : 7|8@0+ (1,0) [0|255] ""  NBCMU
 SG_ NBICU03_SW01 : 15|8@0+ (1,0) [0|255] ""  NBCMU
 SG_ NBICU03_SW02 : 23|8@0+ (1,0) [0|255] ""  NBCMU
 SG_ NBICU03_SW03 : 31|8@0+ (1,0) [0|255] ""  NBCMU
 SG_ NBICU03_SW04 : 39|8@0+ (1,0) [0|255] ""  NBCMU
 SG_ NBICU03_SW05 : 47|8@0+ (1,0) [0|255] ""  NBCMU
 SG_ NBICU03_SW06 : 55|8@0+ (1,0) [0|255] ""  NBCMU
 SG_ NBICU03_SW07 : 63|8@0+ (1,0) [0|255] ""  NBCMU

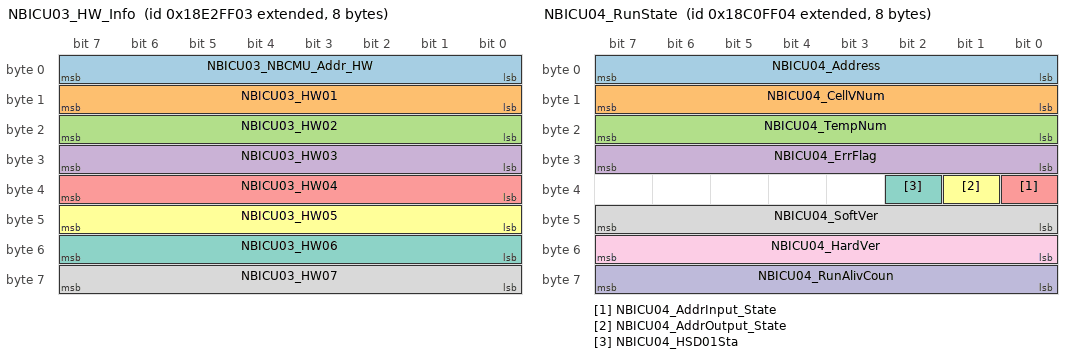
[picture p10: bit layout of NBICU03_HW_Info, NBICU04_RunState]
BO_ 2565013251 NBICU03_HW_Info: 8 NBICU
 SG_ NBICU03_NBCMU_Addr_HW : 7|8@0+ (1,0) [0|255] ""  NBCMU
 SG_ NBICU03_HW01 : 15|8@0+ (1,0) [0|255] ""  NBCMU
 SG_ NBICU03_HW02 : 23|8@0+ (1,0) [0|255] ""  NBCMU
 SG_ NBICU03_HW03 : 31|8@0+ (1,0) [0|255] ""  NBCMU
 SG_ NBICU03_HW04 : 39|8@0+ (1,0) [0|255] ""  NBCMU
 SG_ NBICU03_HW05 : 47|8@0+ (1,0) [0|255] ""  NBCMU
 SG_ NBICU03_HW06 : 55|8@0+ (1,0) [0|255] ""  NBCMU
 SG_ NBICU03_HW07 : 63|8@0+ (1,0) [0|255] ""  NBCMU

BO_ 2564677379 NBICU03_DiaResponse: 8 NBICU
 SG_ NBICU03_RespData : 7|64@0+ (1,0) [0|1.84467440737096E+019] ""  DAPP

BO_ 2562785028 NBICU04_RunState: 8 NBICU
 SG_ NBICU04_Address : 7|8@0+ (1,0) [0|255] ""  NBCMU
 SG_ NBICU04_CellVNum : 15|8@0+ (1,0) [0|255] ""  NBCMU
 SG_ NBICU04_TempNum : 23|8@0+ (1,0) [0|255] ""  NBCMU
 SG_ NBICU04_ErrFlag : 31|8@0+ (1,0) [0|255] ""  NBCMU
 SG_ NBICU04_AddrInput_State : 32|1@0+ (1,0) [0|1] ""  NBCMU
 SG_ NBICU04_AddrOutput_State : 33|1@0+ (1,0) [0|1] ""  NBCMU
 SG_ NBICU04_HSD01Sta : 34|1@0+ (1,0) [0|1] ""  NBCMU
 SG_ NBICU04_SoftVer : 47|8@0+ (1,0) [0|255] ""  NBCMU
 SG_ NBICU04_HardVer : 55|8@0+ (1,0) [0|255] ""  NBCMU
 SG_ NBICU04_RunAlivCoun : 63|8@0+ (1,0) [0|255] ""  NBCMU

BO_ 2562850564 NBICU04_VoltExtremeInfo: 8 NBICU
 SG_ NBICU04_CellVoltMax : 7|16@0+ (1,0) [0|65535] "mV"  NBCMU,SBCMU
 SG_ NBICU04_CellVoltMin : 23|16@0+ (1,0) [0|65535] "mV"  NBCMU,SBCMU
 SG_ NBICU04_CellVoltMaxCode : 39|8@0+ (1,0) [0|255] ""  NBCMU,SBCMU
 SG_ NBICU04_CellVoltMinCode : 47|8@0+ (1,0) [0|255] ""  NBCMU,SBCMU
 SG_ NBICU04_CellSumVolt : 55|16@0+ (0.1,0) [0|6553.5] "V"  NBCMU,SBCMU

BO_ 2562916100 NBICU04_TempExtremeInfo: 8 NBICU
 SG_ NBICU04_CellTempMax : 7|8@0+ (1,-40) [-40|215] "℃"  NBCMU,SBCMU
 SG_ NBICU04_CellTempMin : 15|8@0+ (1,-40) [-40|215] "℃"  NBCMU,SBCMU
 SG_ NBICU04_CellTempAvg : 23|8@0+ (1,-40) [-40|215] "℃"  NBCMU,SBCMU
 SG_ NBICU04_CellTempMaxCode : 31|8@0+ (1,0) [0|255] ""  NBCMU,SBCMU
 SG_ NBICU04_CellTempMinCode : 39|8@0+ (1,0) [0|255] ""  NBCMU,SBCMU
 SG_ NBICU04_SupplyVolt : 40|9@0+ (0.1,0) [0|51.1] "V"  NBCMU,SBCMU
 SG_ NBICU04_PCB_Temp : 63|8@0+ (1,-40) [-40|215] "℃"  NBCMU,SBCMU

BO_ 2562981636 NBICU04_BalState: 8 NBICU
 SG_ NBICU04_Cell0108BalaSta : 7|8@0+ (1,0) [0|255] ""  NBCMU
 SG_ NBICU04_Cell0916BalaSta : 15|8@0+ (1,0) [0|255] ""  NBCMU
 SG_ NBICU04_Cell1724BalaSta : 23|8@0+ (1,0) [0|255] ""  NBCMU
 SG_ NBICU04_Cell2532BalaSta : 31|8@0+ (1,0) [0|255] ""  NBCMU
 SG_ NBICU04_Cell3336BalaSta : 35|4@0+ (1,0) [0|15] ""  NBCMU
 SG_ NBICU04_SysSOH : 47|8@0+ (1,0) [0|100] "%"  NBCMU
 SG_ NBICU04_CycleTime : 55|16@0+ (1,0) [0|65535] ""  NBCMU

BO_ 2563899140 NBICU04_CellVotlage01: 8 NBICU
 SG_ NBICU04_Cell01Volt : 7|16@0+ (1,0) [0|65535] "mV"  NBCMU
 SG_ NBICU04_Cell02Volt : 23|16@0+ (1,0) [0|65535] "mV"  NBCMU
 SG_ NBICU04_Cell03Volt : 39|16@0+ (1,0) [0|65535] "mV"  NBCMU
 SG_ NBICU04_Cell04Volt : 55|16@0+ (1,0) [0|65535] "mV"  NBCMU

BO_ 2563964676 NBICU04_CellVotlage02: 8 NBICU
 SG_ NBICU04_Cell05Volt : 7|16@0+ (1,0) [0|65535] "mV"  NBCMU
 SG_ NBICU04_Cell06Volt : 23|16@0+ (1,0) [0|65535] "mV"  NBCMU
 SG_ NBICU04_Cell07Volt : 39|16@0+ (1,0) [0|65535] "mV"  NBCMU
 SG_ NBICU04_Cell08Volt : 55|16@0+ (1,0) [0|65535] "mV"  NBCMU

BO_ 2564030212 NBICU04_CellVotlage03: 8 NBICU
 SG_ NBICU04_Cell09Volt : 7|16@0+ (1,0) [0|65535] "mV"  NBCMU
 SG_ NBICU04_Cell10Volt : 23|16@0+ (1,0) [0|65535] "mV"  NBCMU
 SG_ NBICU04_Cell11Volt : 39|16@0+ (1,0) [0|65535] "mV"  NBCMU
 SG_ NBICU04_Cell12Volt : 55|16@0+ (1,0) [0|65535] "mV"  NBCMU

BO_ 2564095748 NBICU04_CellVotlage04: 8 NBICU
 SG_ NBICU04_Cell13Volt : 7|16@0+ (1,0) [0|65535] "mV"  NBCMU
 SG_ NBICU04_Cell14Volt : 23|16@0+ (1,0) [0|65535] "mV"  NBCMU
 SG_ NBICU04_Cell15Volt : 39|16@0+ (1,0) [0|65535] "mV"  NBCMU
 SG_ NBICU04_Cell16Volt : 55|16@0+ (1,0) [0|65535] "mV"  NBCMU

BO_ 2564161284 NBICU04_CellVotlage05: 8 NBICU
 SG_ NBICU04_Cell17Volt : 7|16@0+ (1,0) [0|65535] "mV"  NBCMU
 SG_ NBICU04_Cell18Volt : 23|16@0+ (1,0) [0|65535] "mV"  NBCMU
 SG_ NBICU04_Cell19Volt : 39|16@0+ (1,0) [0|65535] "mV"  NBCMU
 SG_ NBICU04_Cell20Volt : 55|16@0+ (1,0) [0|65535] "mV"  NBCMU

BO_ 2564226820 NBICU04_CellVotlage06: 8 NBICU
 SG_ NBICU04_Cell21Volt : 7|16@0+ (1,0) [0|65535] "mV"  NBCMU
 SG_ NBICU04_Cell22Volt : 23|16@0+ (1,0) [0|65535] "mV"  NBCMU
 SG_ NBICU04_Cell23Volt : 39|16@0+ (1,0) [0|65535] "mV"  NBCMU
 SG_ NBICU04_Cell24Volt : 55|16@0+ (1,0) [0|65535] "mV"  NBCMU

BO_ 2564292356 NBICU04_CellVotlage07: 8 NBICU
 SG_ NBICU04_Cell25Volt : 7|16@0+ (1,0) [0|65535] "mV"  NBCMU
 SG_ NBICU04_Cell26Volt : 23|16@0+ (1,0) [0|65535] "mV"  NBCMU
 SG_ NBICU04_Cell27Volt : 39|16@0+ (1,0) [0|65535] "mV"  NBCMU
 SG_ NBICU04_Cell28Volt : 55|16@0+ (1,0) [0|65535] "mV"  NBCMU

BO_ 2564357892 NBICU04_CellVotlage08: 8 NBICU
 SG_ NBICU04_Cell29Volt : 7|16@0+ (1,0) [0|65535] "mV"  NBCMU
 SG_ NBICU04_Cell30Volt : 23|16@0+ (1,0) [0|65535] "mV"  NBCMU
 SG_ NBICU04_Cell31Volt : 39|16@0+ (1,0) [0|65535] "mV"  NBCMU
 SG_ NBICU04_Cell32Volt : 55|16@0+ (1,0) [0|65535] "mV"  NBCMU

BO_ 2564423428 NBICU04_CellVotlage09: 8 NBICU
 SG_ NBICU04_Cell33Volt : 7|16@0+ (1,0) [0|65535] "mV"  NBCMU
 SG_ NBICU04_Cell34Volt : 23|16@0+ (1,0) [0|65535] "mV"  NBCMU
 SG_ NBICU04_Cell35Volt : 39|16@0+ (1,0) [0|65535] "mV"  NBCMU
 SG_ NBICU04_Cell36Volt : 55|16@0+ (1,0) [0|65535] "mV"  NBCMU

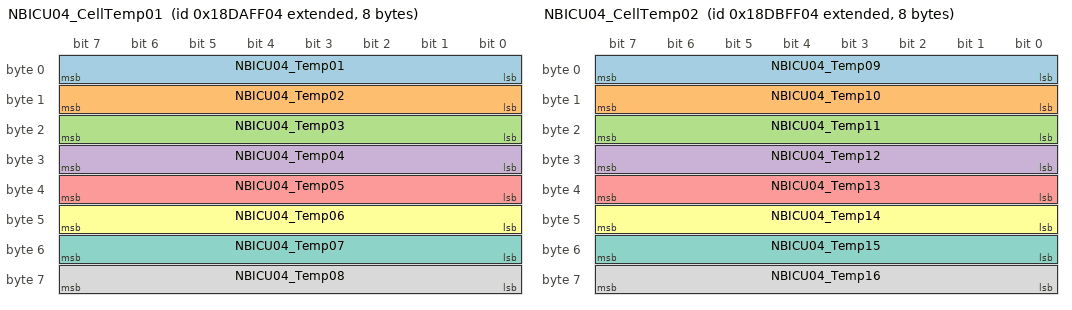
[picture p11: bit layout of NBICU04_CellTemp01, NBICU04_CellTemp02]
BO_ 2564488964 NBICU04_CellTemp01: 8 NBICU
 SG_ NBICU04_Temp01 : 7|8@0+ (1,-40) [-40|215] "℃"  NBCMU
 SG_ NBICU04_Temp02 : 15|8@0+ (1,-40) [-40|215] "℃"  NBCMU
 SG_ NBICU04_Temp03 : 23|8@0+ (1,-40) [-40|215] "℃"  NBCMU
 SG_ NBICU04_Temp04 : 31|8@0+ (1,-40) [-40|215] "℃"  NBCMU
 SG_ NBICU04_Temp05 : 39|8@0+ (1,-40) [-40|215] "℃"  NBCMU
 SG_ NBICU04_Temp06 : 47|8@0+ (1,-40) [-40|215] "℃"  NBCMU
 SG_ NBICU04_Temp07 : 55|8@0+ (1,-40) [-40|215] "℃"  NBCMU
 SG_ NBICU04_Temp08 : 63|8@0+ (1,-40) [-40|215] "℃"  NBCMU

BO_ 2564554500 NBICU04_CellTemp02: 8 NBICU
 SG_ NBICU04_Temp09 : 7|8@0+ (1,-40) [-40|215] "℃"  NBCMU
 SG_ NBICU04_Temp10 : 15|8@0+ (1,-40) [-40|215] "℃"  NBCMU
 SG_ NBICU04_Temp11 : 23|8@0+ (1,-40) [-40|215] "℃"  NBCMU
 SG_ NBICU04_Temp12 : 31|8@0+ (1,-40) [-40|215] "℃"  NBCMU
 SG_ NBICU04_Temp13 : 39|8@0+ (1,-40) [-40|215] "℃"  NBCMU
 SG_ NBICU04_Temp14 : 47|8@0+ (1,-40) [-40|215] "℃"  NBCMU
 SG_ NBICU04_Temp15 : 55|8@0+ (1,-40) [-40|215] "℃"  NBCMU
 SG_ NBICU04_Temp16 : 63|8@0+ (1,-40) [-40|215] "℃"  NBCMU

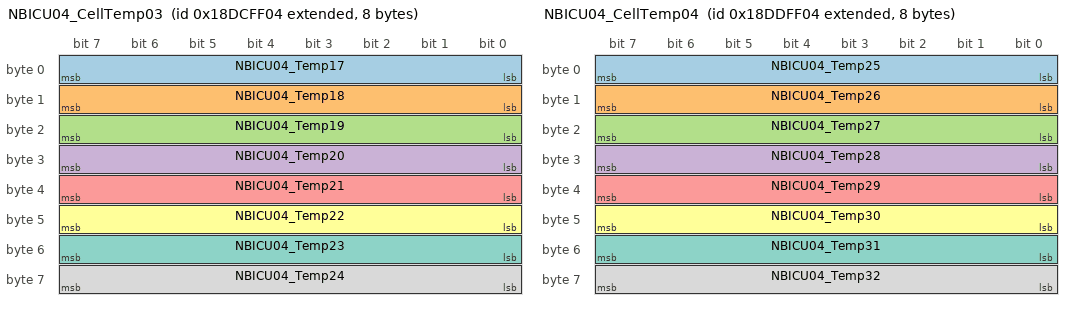
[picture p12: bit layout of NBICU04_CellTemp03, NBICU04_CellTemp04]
BO_ 2564620036 NBICU04_CellTemp03: 8 NBICU
 SG_ NBICU04_Temp17 : 7|8@0+ (1,-40) [-40|215] "℃"  NBCMU
 SG_ NBICU04_Temp18 : 15|8@0+ (1,-40) [-40|215] "℃"  NBCMU
 SG_ NBICU04_Temp19 : 23|8@0+ (1,-40) [-40|215] "℃"  NBCMU
 SG_ NBICU04_Temp20 : 31|8@0+ (1,-40) [-40|215] "℃"  NBCMU
 SG_ NBICU04_Temp21 : 39|8@0+ (1,-40) [-40|215] "℃"  NBCMU
 SG_ NBICU04_Temp22 : 47|8@0+ (1,-40) [-40|215] "℃"  NBCMU
 SG_ NBICU04_Temp23 : 55|8@0+ (1,-40) [-40|215] "℃"  NBCMU
 SG_ NBICU04_Temp24 : 63|8@0+ (1,-40) [-40|215] "℃"  NBCMU

BO_ 2564685572 NBICU04_CellTemp04: 8 NBICU
 SG_ NBICU04_Temp25 : 7|8@0+ (1,-40) [-40|215] "℃"  NBCMU
 SG_ NBICU04_Temp26 : 15|8@0+ (1,-40) [-40|215] "℃"  NBCMU
 SG_ NBICU04_Temp27 : 23|8@0+ (1,-40) [-40|215] "℃"  NBCMU
 SG_ NBICU04_Temp28 : 31|8@0+ (1,-40) [-40|215] "℃"  NBCMU
 SG_ NBICU04_Temp29 : 39|8@0+ (1,-40) [-40|215] "℃"  NBCMU
 SG_ NBICU04_Temp30 : 47|8@0+ (1,-40) [-40|215] "℃"  NBCMU
 SG_ NBICU04_Temp31 : 55|8@0+ (1,-40) [-40|215] "℃"  NBCMU
 SG_ NBICU04_Temp32 : 63|8@0+ (1,-40) [-40|215] "℃"  NBCMU

BO_ 2564751108 NBICU04_CellTemp05: 8 NBICU
 SG_ NBICU04_Temp33 : 7|8@0+ (1,-40) [-40|215] "℃"  NBCMU
 SG_ NBICU04_Temp34 : 15|8@0+ (1,-40) [-40|215] "℃"  NBCMU
 SG_ NBICU04_Temp35 : 23|8@0+ (1,-40) [-40|215] "℃"  NBCMU
 SG_ NBICU04_Temp36 : 31|8@0+ (1,-40) [-40|215] "℃"  NBCMU

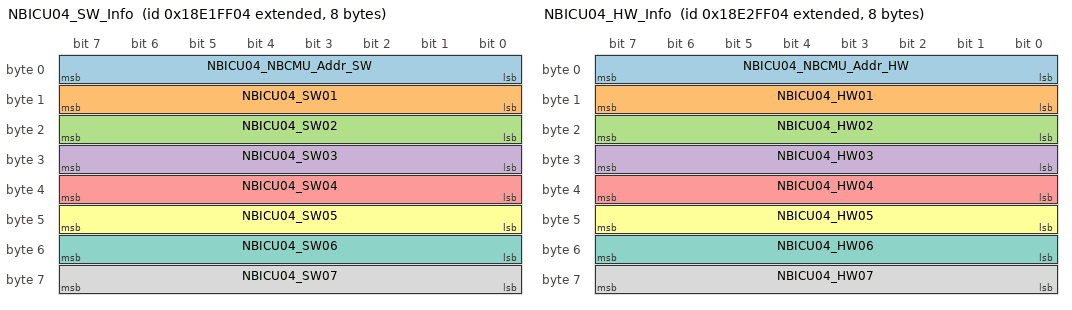
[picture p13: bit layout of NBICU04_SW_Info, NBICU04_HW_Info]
BO_ 2564947716 NBICU04_SW_Info: 8 NBICU
 SG_ NBICU04_NBCMU_Addr_SW : 7|8@0+ (1,0) [0|255] ""  NBCMU
 SG_ NBICU04_SW01 : 15|8@0+ (1,0) [0|255] ""  NBCMU
 SG_ NBICU04_SW02 : 23|8@0+ (1,0) [0|255] ""  NBCMU
 SG_ NBICU04_SW03 : 31|8@0+ (1,0) [0|255] ""  NBCMU
 SG_ NBICU04_SW04 : 39|8@0+ (1,0) [0|255] ""  NBCMU
 SG_ NBICU04_SW05 : 47|8@0+ (1,0) [0|255] ""  NBCMU
 SG_ NBICU04_SW06 : 55|8@0+ (1,0) [0|255] ""  NBCMU
 SG_ NBICU04_SW07 : 63|8@0+ (1,0) [0|255] ""  NBCMU

BO_ 2565013252 NBICU04_HW_Info: 8 NBICU
 SG_ NBICU04_NBCMU_Addr_HW : 7|8@0+ (1,0) [0|255] ""  NBCMU
 SG_ NBICU04_HW01 : 15|8@0+ (1,0) [0|255] ""  NBCMU
 SG_ NBICU04_HW02 : 23|8@0+ (1,0) [0|255] ""  NBCMU
 SG_ NBICU04_HW03 : 31|8@0+ (1,0) [0|255] ""  NBCMU
 SG_ NBICU04_HW04 : 39|8@0+ (1,0) [0|255] ""  NBCMU
 SG_ NBICU04_HW05 : 47|8@0+ (1,0) [0|255] ""  NBCMU
 SG_ NBICU04_HW06 : 55|8@0+ (1,0) [0|255] ""  NBCMU
 SG_ NBICU04_HW07 : 63|8@0+ (1,0) [0|255] ""  NBCMU

BO_ 2564677380 NBICU04_DiaResponse: 8 NBICU
 SG_ NBICU04_RespData : 7|64@0+ (1,0) [0|1.84467440737096E+019] ""  DAPP

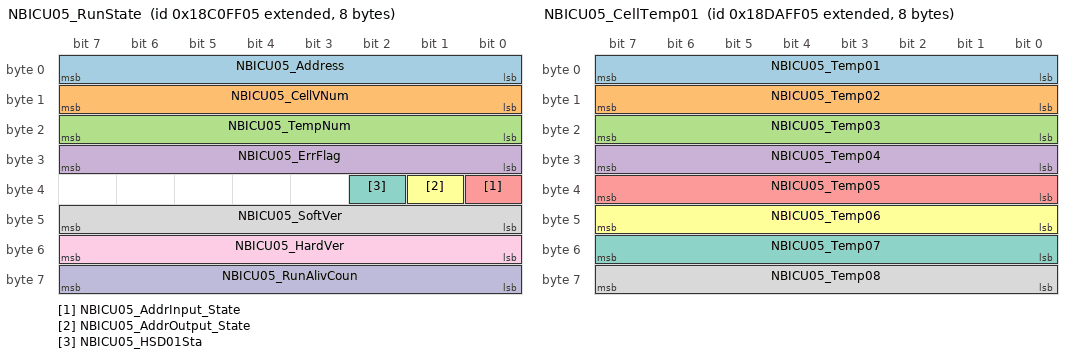
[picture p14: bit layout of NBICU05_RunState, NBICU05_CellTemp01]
BO_ 2562785029 NBICU05_RunState: 8 NBICU
 SG_ NBICU05_Address : 7|8@0+ (1,0) [0|255] ""  NBCMU
 SG_ NBICU05_CellVNum : 15|8@0+ (1,0) [0|255] ""  NBCMU
 SG_ NBICU05_TempNum : 23|8@0+ (1,0) [0|255] ""  NBCMU
 SG_ NBICU05_ErrFlag : 31|8@0+ (1,0) [0|255] ""  NBCMU
 SG_ NBICU05_AddrInput_State : 32|1@0+ (1,0) [0|1] ""  NBCMU
 SG_ NBICU05_AddrOutput_State : 33|1@0+ (1,0) [0|1] ""  NBCMU
 SG_ NBICU05_HSD01Sta : 34|1@0+ (1,0) [0|1] ""  NBCMU
 SG_ NBICU05_SoftVer : 47|8@0+ (1,0) [0|255] ""  NBCMU
 SG_ NBICU05_HardVer : 55|8@0+ (1,0) [0|255] ""  NBCMU
 SG_ NBICU05_RunAlivCoun : 63|8@0+ (1,0) [0|255] ""  NBCMU

BO_ 2562850565 NBICU05_VoltExtremeInfo: 8 NBICU
 SG_ NBICU05_CellVoltMax : 7|16@0+ (1,0) [0|65535] "mV"  NBCMU,SBCMU
 SG_ NBICU05_CellVoltMin : 23|16@0+ (1,0) [0|65535] "mV"  NBCMU,SBCMU
 SG_ NBICU05_CellVoltMaxCode : 39|8@0+ (1,0) [0|255] ""  NBCMU,SBCMU
 SG_ NBICU05_CellVoltMinCode : 47|8@0+ (1,0) [0|255] ""  NBCMU,SBCMU
 SG_ NBICU05_CellSumVolt : 55|16@0+ (0.1,0) [0|6553.5] "V"  NBCMU,SBCMU

BO_ 2562916101 NBICU05_TempExtremeInfo: 8 NBICU
 SG_ NBICU05_CellTempMax : 7|8@0+ (1,-40) [-40|215] "℃"  NBCMU,SBCMU
 SG_ NBICU05_CellTempMin : 15|8@0+ (1,-40) [-40|215] "℃"  NBCMU,SBCMU
 SG_ NBICU05_CellTempAvg : 23|8@0+ (1,-40) [-40|215] "℃"  NBCMU,SBCMU
 SG_ NBICU05_CellTempMaxCode : 31|8@0+ (1,0) [0|255] ""  NBCMU,SBCMU
 SG_ NBICU05_CellTempMinCode : 39|8@0+ (1,0) [0|255] ""  NBCMU,SBCMU
 SG_ NBICU05_SupplyVolt : 40|9@0+ (0.1,0) [0|51.1] "V"  NBCMU,SBCMU
 SG_ NBICU05_PCB_Temp : 63|8@0+ (1,-40) [-40|215] "℃"  NBCMU,SBCMU

BO_ 2562981637 NBICU05_BalState: 8 NBICU
 SG_ NBICU05_Cell0108BalaSta : 7|8@0+ (1,0) [0|255] ""  NBCMU
 SG_ NBICU05_Cell0916BalaSta : 15|8@0+ (1,0) [0|255] ""  NBCMU
 SG_ NBICU05_Cell1724BalaSta : 23|8@0+ (1,0) [0|255] ""  NBCMU
 SG_ NBICU05_Cell2532BalaSta : 31|8@0+ (1,0) [0|255] ""  NBCMU
 SG_ NBICU05_Cell3336BalaSta : 35|4@0+ (1,0) [0|15] ""  NBCMU
 SG_ NBICU05_SysSOH : 47|8@0+ (1,0) [0|100] "%"  NBCMU
 SG_ NBICU05_CycleTime : 55|16@0+ (1,0) [0|65535] ""  NBCMU

BO_ 2563899141 NBICU05_CellVotlage01: 8 NBICU
 SG_ NBICU05_Cell01Volt : 7|16@0+ (1,0) [0|65535] "mV"  NBCMU
 SG_ NBICU05_Cell02Volt : 23|16@0+ (1,0) [0|65535] "mV"  NBCMU
 SG_ NBICU05_Cell03Volt : 39|16@0+ (1,0) [0|65535] "mV"  NBCMU
 SG_ NBICU05_Cell04Volt : 55|16@0+ (1,0) [0|65535] "mV"  NBCMU

BO_ 2563964677 NBICU05_CellVotlage02: 8 NBICU
 SG_ NBICU05_Cell05Volt : 7|16@0+ (1,0) [0|65535] "mV"  NBCMU
 SG_ NBICU05_Cell06Volt : 23|16@0+ (1,0) [0|65535] "mV"  NBCMU
 SG_ NBICU05_Cell07Volt : 39|16@0+ (1,0) [0|65535] "mV"  NBCMU
 SG_ NBICU05_Cell08Volt : 55|16@0+ (1,0) [0|65535] "mV"  NBCMU

BO_ 2564030213 NBICU05_CellVotlage03: 8 NBICU
 SG_ NBICU05_Cell09Volt : 7|16@0+ (1,0) [0|65535] "mV"  NBCMU
 SG_ NBICU05_Cell10Volt : 23|16@0+ (1,0) [0|65535] "mV"  NBCMU
 SG_ NBICU05_Cell11Volt : 39|16@0+ (1,0) [0|65535] "mV"  NBCMU
 SG_ NBICU05_Cell12Volt : 55|16@0+ (1,0) [0|65535] "mV"  NBCMU

BO_ 2564095749 NBICU05_CellVotlage04: 8 NBICU
 SG_ NBICU05_Cell13Volt : 7|16@0+ (1,0) [0|65535] "mV"  NBCMU
 SG_ NBICU05_Cell14Volt : 23|16@0+ (1,0) [0|65535] "mV"  NBCMU
 SG_ NBICU05_Cell15Volt : 39|16@0+ (1,0) [0|65535] "mV"  NBCMU
 SG_ NBICU05_Cell16Volt : 55|16@0+ (1,0) [0|65535] "mV"  NBCMU

BO_ 2564161285 NBICU05_CellVotlage05: 8 NBICU
 SG_ NBICU05_Cell17Volt : 7|16@0+ (1,0) [0|65535] "mV"  NBCMU
 SG_ NBICU05_Cell18Volt : 23|16@0+ (1,0) [0|65535] "mV"  NBCMU
 SG_ NBICU05_Cell19Volt : 39|16@0+ (1,0) [0|65535] "mV"  NBCMU
 SG_ NBICU05_Cell20Volt : 55|16@0+ (1,0) [0|65535] "mV"  NBCMU

BO_ 2564226821 NBICU05_CellVotlage06: 8 NBICU
 SG_ NBICU05_Cell21Volt : 7|16@0+ (1,0) [0|65535] "mV"  NBCMU
 SG_ NBICU05_Cell22Volt : 23|16@0+ (1,0) [0|65535] "mV"  NBCMU
 SG_ NBICU05_Cell23Volt : 39|16@0+ (1,0) [0|65535] "mV"  NBCMU
 SG_ NBICU05_Cell24Volt : 55|16@0+ (1,0) [0|65535] "mV"  NBCMU

BO_ 2564292357 NBICU05_CellVotlage07: 8 NBICU
 SG_ NBICU05_Cell25Volt : 7|16@0+ (1,0) [0|65535] "mV"  NBCMU
 SG_ NBICU05_Cell26Volt : 23|16@0+ (1,0) [0|65535] "mV"  NBCMU
 SG_ NBICU05_Cell27Volt : 39|16@0+ (1,0) [0|65535] "mV"  NBCMU
 SG_ NBICU05_Cell28Volt : 55|16@0+ (1,0) [0|65535] "mV"  NBCMU

BO_ 2564357893 NBICU05_CellVotlage08: 8 NBICU
 SG_ NBICU05_Cell29Volt : 7|16@0+ (1,0) [0|65535] "mV"  NBCMU
 SG_ NBICU05_Cell30Volt : 23|16@0+ (1,0) [0|65535] "mV"  NBCMU
 SG_ NBICU05_Cell31Volt : 39|16@0+ (1,0) [0|65535] "mV"  NBCMU
 SG_ NBICU05_Cell32Volt : 55|16@0+ (1,0) [0|65535] "mV"  NBCMU

BO_ 2564423429 NBICU05_CellVotlage09: 8 NBICU
 SG_ NBICU05_Cell33Volt : 7|16@0+ (1,0) [0|65535] "mV"  NBCMU
 SG_ NBICU05_Cell34Volt : 23|16@0+ (1,0) [0|65535] "mV"  NBCMU
 SG_ NBICU05_Cell35Volt : 39|16@0+ (1,0) [0|65535] "mV"  NBCMU
 SG_ NBICU05_Cell36Volt : 55|16@0+ (1,0) [0|65535] "mV"  NBCMU

BO_ 2564488965 NBICU05_CellTemp01: 8 NBICU
 SG_ NBICU05_Temp01 : 7|8@0+ (1,-40) [-40|215] "℃"  NBCMU
 SG_ NBICU05_Temp02 : 15|8@0+ (1,-40) [-40|215] "℃"  NBCMU
 SG_ NBICU05_Temp03 : 23|8@0+ (1,-40) [-40|215] "℃"  NBCMU
 SG_ NBICU05_Temp04 : 31|8@0+ (1,-40) [-40|215] "℃"  NBCMU
 SG_ NBICU05_Temp05 : 39|8@0+ (1,-40) [-40|215] "℃"  NBCMU
 SG_ NBICU05_Temp06 : 47|8@0+ (1,-40) [-40|215] "℃"  NBCMU
 SG_ NBICU05_Temp07 : 55|8@0+ (1,-40) [-40|215] "℃"  NBCMU
 SG_ NBICU05_Temp08 : 63|8@0+ (1,-40) [-40|215] "℃"  NBCMU

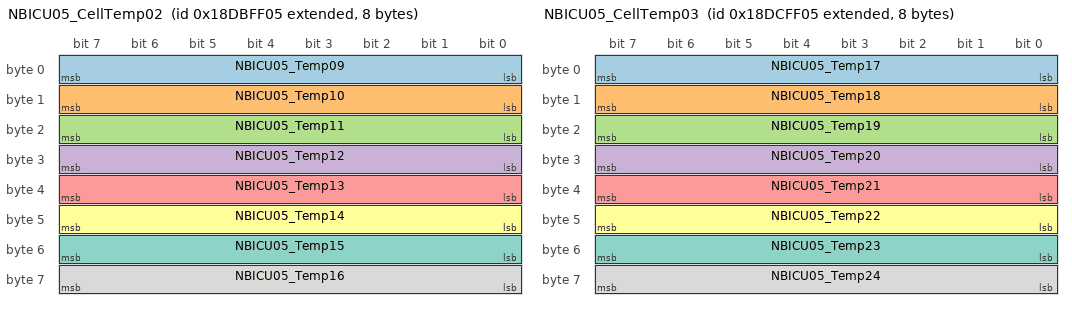
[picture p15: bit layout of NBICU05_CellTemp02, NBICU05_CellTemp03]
BO_ 2564554501 NBICU05_CellTemp02: 8 NBICU
 SG_ NBICU05_Temp09 : 7|8@0+ (1,-40) [-40|215] "℃"  NBCMU
 SG_ NBICU05_Temp10 : 15|8@0+ (1,-40) [-40|215] "℃"  NBCMU
 SG_ NBICU05_Temp11 : 23|8@0+ (1,-40) [-40|215] "℃"  NBCMU
 SG_ NBICU05_Temp12 : 31|8@0+ (1,-40) [-40|215] "℃"  NBCMU
 SG_ NBICU05_Temp13 : 39|8@0+ (1,-40) [-40|215] "℃"  NBCMU
 SG_ NBICU05_Temp14 : 47|8@0+ (1,-40) [-40|215] "℃"  NBCMU
 SG_ NBICU05_Temp15 : 55|8@0+ (1,-40) [-40|215] "℃"  NBCMU
 SG_ NBICU05_Temp16 : 63|8@0+ (1,-40) [-40|215] "℃"  NBCMU

BO_ 2564620037 NBICU05_CellTemp03: 8 NBICU
 SG_ NBICU05_Temp17 : 7|8@0+ (1,-40) [-40|215] "℃"  NBCMU
 SG_ NBICU05_Temp18 : 15|8@0+ (1,-40) [-40|215] "℃"  NBCMU
 SG_ NBICU05_Temp19 : 23|8@0+ (1,-40) [-40|215] "℃"  NBCMU
 SG_ NBICU05_Temp20 : 31|8@0+ (1,-40) [-40|215] "℃"  NBCMU
 SG_ NBICU05_Temp21 : 39|8@0+ (1,-40) [-40|215] "℃"  NBCMU
 SG_ NBICU05_Temp22 : 47|8@0+ (1,-40) [-40|215] "℃"  NBCMU
 SG_ NBICU05_Temp23 : 55|8@0+ (1,-40) [-40|215] "℃"  NBCMU
 SG_ NBICU05_Temp24 : 63|8@0+ (1,-40) [-40|215] "℃"  NBCMU

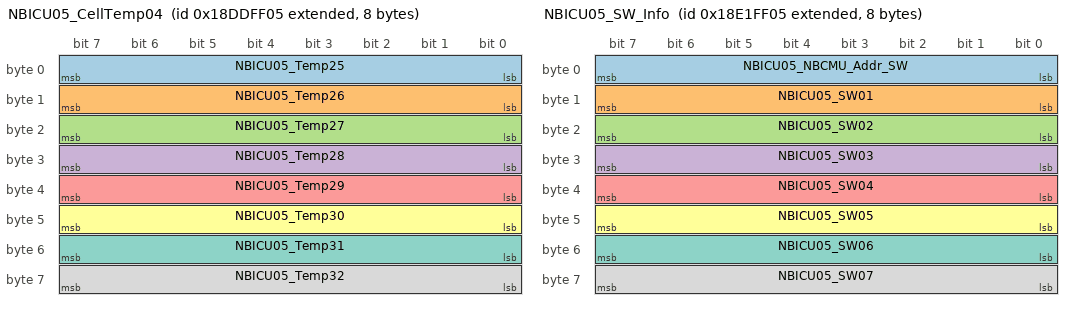
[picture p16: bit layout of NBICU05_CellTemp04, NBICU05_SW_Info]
BO_ 2564685573 NBICU05_CellTemp04: 8 NBICU
 SG_ NBICU05_Temp25 : 7|8@0+ (1,-40) [-40|215] "℃"  NBCMU
 SG_ NBICU05_Temp26 : 15|8@0+ (1,-40) [-40|215] "℃"  NBCMU
 SG_ NBICU05_Temp27 : 23|8@0+ (1,-40) [-40|215] "℃"  NBCMU
 SG_ NBICU05_Temp28 : 31|8@0+ (1,-40) [-40|215] "℃"  NBCMU
 SG_ NBICU05_Temp29 : 39|8@0+ (1,-40) [-40|215] "℃"  NBCMU
 SG_ NBICU05_Temp30 : 47|8@0+ (1,-40) [-40|215] "℃"  NBCMU
 SG_ NBICU05_Temp31 : 55|8@0+ (1,-40) [-40|215] "℃"  NBCMU
 SG_ NBICU05_Temp32 : 63|8@0+ (1,-40) [-40|215] "℃"  NBCMU

BO_ 2564751109 NBICU05_CellTemp05: 8 NBICU
 SG_ NBICU05_Temp33 : 7|8@0+ (1,-40) [-40|215] "℃"  NBCMU
 SG_ NBICU05_Temp34 : 15|8@0+ (1,-40) [-40|215] "℃"  NBCMU
 SG_ NBICU05_Temp35 : 23|8@0+ (1,-40) [-40|215] "℃"  NBCMU
 SG_ NBICU05_Temp36 : 31|8@0+ (1,-40) [-40|215] "℃"  NBCMU

BO_ 2564947717 NBICU05_SW_Info: 8 NBICU
 SG_ NBICU05_NBCMU_Addr_SW : 7|8@0+ (1,0) [0|255] ""  NBCMU
 SG_ NBICU05_SW01 : 15|8@0+ (1,0) [0|255] ""  NBCMU
 SG_ NBICU05_SW02 : 23|8@0+ (1,0) [0|255] ""  NBCMU
 SG_ NBICU05_SW03 : 31|8@0+ (1,0) [0|255] ""  NBCMU
 SG_ NBICU05_SW04 : 39|8@0+ (1,0) [0|255] ""  NBCMU
 SG_ NBICU05_SW05 : 47|8@0+ (1,0) [0|255] ""  NBCMU
 SG_ NBICU05_SW06 : 55|8@0+ (1,0) [0|255] ""  NBCMU
 SG_ NBICU05_SW07 : 63|8@0+ (1,0) [0|255] ""  NBCMU

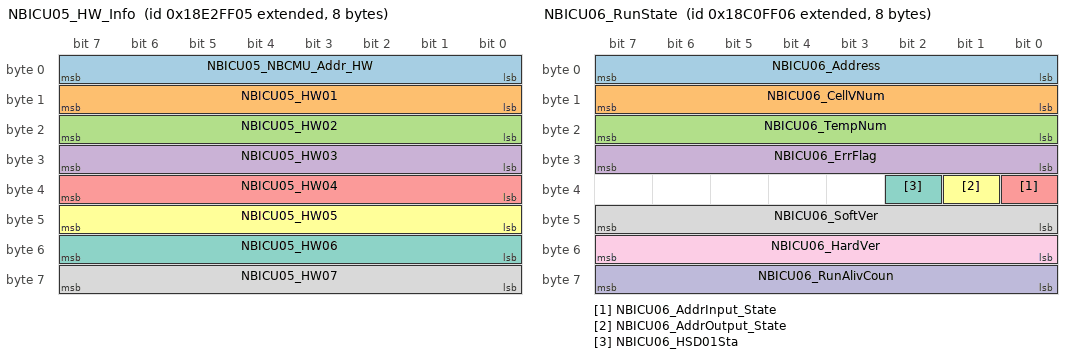
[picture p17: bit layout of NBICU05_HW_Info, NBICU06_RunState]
BO_ 2565013253 NBICU05_HW_Info: 8 NBICU
 SG_ NBICU05_NBCMU_Addr_HW : 7|8@0+ (1,0) [0|255] ""  NBCMU
 SG_ NBICU05_HW01 : 15|8@0+ (1,0) [0|255] ""  NBCMU
 SG_ NBICU05_HW02 : 23|8@0+ (1,0) [0|255] ""  NBCMU
 SG_ NBICU05_HW03 : 31|8@0+ (1,0) [0|255] ""  NBCMU
 SG_ NBICU05_HW04 : 39|8@0+ (1,0) [0|255] ""  NBCMU
 SG_ NBICU05_HW05 : 47|8@0+ (1,0) [0|255] ""  NBCMU
 SG_ NBICU05_HW06 : 55|8@0+ (1,0) [0|255] ""  NBCMU
 SG_ NBICU05_HW07 : 63|8@0+ (1,0) [0|255] ""  NBCMU

BO_ 2564677381 NBICU05_DiaResponse: 8 NBICU
 SG_ NBICU05_RespData : 7|64@0+ (1,0) [0|1.84467440737096E+019] ""  DAPP

BO_ 2562785030 NBICU06_RunState: 8 NBICU
 SG_ NBICU06_Address : 7|8@0+ (1,0) [0|255] ""  NBCMU
 SG_ NBICU06_CellVNum : 15|8@0+ (1,0) [0|255] ""  NBCMU
 SG_ NBICU06_TempNum : 23|8@0+ (1,0) [0|255] ""  NBCMU
 SG_ NBICU06_ErrFlag : 31|8@0+ (1,0) [0|255] ""  NBCMU
 SG_ NBICU06_AddrInput_State : 32|1@0+ (1,0) [0|1] ""  NBCMU
 SG_ NBICU06_AddrOutput_State : 33|1@0+ (1,0) [0|1] ""  NBCMU
 SG_ NBICU06_HSD01Sta : 34|1@0+ (1,0) [0|1] ""  NBCMU
 SG_ NBICU06_SoftVer : 47|8@0+ (1,0) [0|255] ""  NBCMU
 SG_ NBICU06_HardVer : 55|8@0+ (1,0) [0|255] ""  NBCMU
 SG_ NBICU06_RunAlivCoun : 63|8@0+ (1,0) [0|255] ""  NBCMU

BO_ 2562850566 NBICU06_VoltExtremeInfo: 8 NBICU
 SG_ NBICU06_CellVoltMax : 7|16@0+ (1,0) [0|65535] "mV"  NBCMU,SBCMU
 SG_ NBICU06_CellVoltMin : 23|16@0+ (1,0) [0|65535] "mV"  NBCMU,SBCMU
 SG_ NBICU06_CellVoltMaxCode : 39|8@0+ (1,0) [0|255] ""  NBCMU,SBCMU
 SG_ NBICU06_CellVoltMinCode : 47|8@0+ (1,0) [0|255] ""  NBCMU,SBCMU
 SG_ NBICU06_CellSumVolt : 55|16@0+ (0.1,0) [0|6553.5] "V"  NBCMU,SBCMU

BO_ 2562916102 NBICU06_TempExtremeInfo: 8 NBICU
 SG_ NBICU06_CellTempMax : 7|8@0+ (1,-40) [-40|215] "℃"  NBCMU,SBCMU
 SG_ NBICU06_CellTempMin : 15|8@0+ (1,-40) [-40|215] "℃"  NBCMU,SBCMU
 SG_ NBICU06_CellTempAvg : 23|8@0+ (1,-40) [-40|215] "℃"  NBCMU,SBCMU
 SG_ NBICU06_CellTempMaxCode : 31|8@0+ (1,0) [0|255] ""  NBCMU,SBCMU
 SG_ NBICU06_CellTempMinCode : 39|8@0+ (1,0) [0|255] ""  NBCMU,SBCMU
 SG_ NBICU06_SupplyVolt : 40|9@0+ (0.1,0) [0|51.1] "V"  NBCMU,SBCMU
 SG_ NBICU06_PCB_Temp : 63|8@0+ (1,-40) [-40|215] "℃"  NBCMU,SBCMU

BO_ 2562981638 NBICU06_BalState: 8 NBICU
 SG_ NBICU06_Cell0108BalaSta : 7|8@0+ (1,0) [0|255] ""  NBCMU
 SG_ NBICU06_Cell0916BalaSta : 15|8@0+ (1,0) [0|255] ""  NBCMU
 SG_ NBICU06_Cell1724BalaSta : 23|8@0+ (1,0) [0|255] ""  NBCMU
 SG_ NBICU06_Cell2532BalaSta : 31|8@0+ (1,0) [0|255] ""  NBCMU
 SG_ NBICU06_Cell3336BalaSta : 35|4@0+ (1,0) [0|15] ""  NBCMU
 SG_ NBICU06_SysSOH : 47|8@0+ (1,0) [0|100] "%"  NBCMU
 SG_ NBICU06_CycleTime : 55|16@0+ (1,0) [0|65535] ""  NBCMU

BO_ 2563899142 NBICU06_CellVotlage01: 8 NBICU
 SG_ NBICU06_Cell01Volt : 7|16@0+ (1,0) [0|65535] "mV"  NBCMU
 SG_ NBICU06_Cell02Volt : 23|16@0+ (1,0) [0|65535] "mV"  NBCMU
 SG_ NBICU06_Cell03Volt : 39|16@0+ (1,0) [0|65535] "mV"  NBCMU
 SG_ NBICU06_Cell04Volt : 55|16@0+ (1,0) [0|65535] "mV"  NBCMU

BO_ 2563964678 NBICU06_CellVotlage02: 8 NBICU
 SG_ NBICU06_Cell05Volt : 7|16@0+ (1,0) [0|65535] "mV"  NBCMU
 SG_ NBICU06_Cell06Volt : 23|16@0+ (1,0) [0|65535] "mV"  NBCMU
 SG_ NBICU06_Cell07Volt : 39|16@0+ (1,0) [0|65535] "mV"  NBCMU
 SG_ NBICU06_Cell08Volt : 55|16@0+ (1,0) [0|65535] "mV"  NBCMU

BO_ 2564030214 NBICU06_CellVotlage03: 8 NBICU
 SG_ NBICU06_Cell09Volt : 7|16@0+ (1,0) [0|65535] "mV"  NBCMU
 SG_ NBICU06_Cell10Volt : 23|16@0+ (1,0) [0|65535] "mV"  NBCMU
 SG_ NBICU06_Cell11Volt : 39|16@0+ (1,0) [0|65535] "mV"  NBCMU
 SG_ NBICU06_Cell12Volt : 55|16@0+ (1,0) [0|65535] "mV"  NBCMU

BO_ 2564095750 NBICU06_CellVotlage04: 8 NBICU
 SG_ NBICU06_Cell13Volt : 7|16@0+ (1,0) [0|65535] "mV"  NBCMU
 SG_ NBICU06_Cell14Volt : 23|16@0+ (1,0) [0|65535] "mV"  NBCMU
 SG_ NBICU06_Cell15Volt : 39|16@0+ (1,0) [0|65535] "mV"  NBCMU
 SG_ NBICU06_Cell16Volt : 55|16@0+ (1,0) [0|65535] "mV"  NBCMU

BO_ 2564161286 NBICU06_CellVotlage05: 8 NBICU
 SG_ NBICU06_Cell17Volt : 7|16@0+ (1,0) [0|65535] "mV"  NBCMU
 SG_ NBICU06_Cell18Volt : 23|16@0+ (1,0) [0|65535] "mV"  NBCMU
 SG_ NBICU06_Cell19Volt : 39|16@0+ (1,0) [0|65535] "mV"  NBCMU
 SG_ NBICU06_Cell20Volt : 55|16@0+ (1,0) [0|65535] "mV"  NBCMU

BO_ 2564226822 NBICU06_CellVotlage06: 8 NBICU
 SG_ NBICU06_Cell21Volt : 7|16@0+ (1,0) [0|65535] "mV"  NBCMU
 SG_ NBICU06_Cell22Volt : 23|16@0+ (1,0) [0|65535] "mV"  NBCMU
 SG_ NBICU06_Cell23Volt : 39|16@0+ (1,0) [0|65535] "mV"  NBCMU
 SG_ NBICU06_Cell24Volt : 55|16@0+ (1,0) [0|65535] "mV"  NBCMU

BO_ 2564292358 NBICU06_CellVotlage07: 8 NBICU
 SG_ NBICU06_Cell25Volt : 7|16@0+ (1,0) [0|65535] "mV"  NBCMU
 SG_ NBICU06_Cell26Volt : 23|16@0+ (1,0) [0|65535] "mV"  NBCMU
 SG_ NBICU06_Cell27Volt : 39|16@0+ (1,0) [0|65535] "mV"  NBCMU
 SG_ NBICU06_Cell28Volt : 55|16@0+ (1,0) [0|65535] "mV"  NBCMU

BO_ 2564357894 NBICU06_CellVotlage08: 8 NBICU
 SG_ NBICU06_Cell29Volt : 7|16@0+ (1,0) [0|65535] "mV"  NBCMU
 SG_ NBICU06_Cell30Volt : 23|16@0+ (1,0) [0|65535] "mV"  NBCMU
 SG_ NBICU06_Cell31Volt : 39|16@0+ (1,0) [0|65535] "mV"  NBCMU
 SG_ NBICU06_Cell32Volt : 55|16@0+ (1,0) [0|65535] "mV"  NBCMU

BO_ 2564423430 NBICU06_CellVotlage09: 8 NBICU
 SG_ NBICU06_Cell33Volt : 7|16@0+ (1,0) [0|65535] "mV"  NBCMU
 SG_ NBICU06_Cell34Volt : 23|16@0+ (1,0) [0|65535] "mV"  NBCMU
 SG_ NBICU06_Cell35Volt : 39|16@0+ (1,0) [0|65535] "mV"  NBCMU
 SG_ NBICU06_Cell36Volt : 55|16@0+ (1,0) [0|65535] "mV"  NBCMU

BO_ 2564488966 NBICU06_CellTemp01: 8 NBICU
 SG_ NBICU06_Temp01 : 7|8@0+ (1,-40) [-40|215] "℃"  NBCMU
 SG_ NBICU06_Temp02 : 15|8@0+ (1,-40) [-40|215] "℃"  NBCMU
 SG_ NBICU06_Temp03 : 23|8@0+ (1,-40) [-40|215] "℃"  NBCMU
 SG_ NBICU06_Temp04 : 31|8@0+ (1,-40) [-40|215] "℃"  NBCMU
 SG_ NBICU06_Temp05 : 39|8@0+ (1,-40) [-40|215] "℃"  NBCMU
 SG_ NBICU06_Temp06 : 47|8@0+ (1,-40) [-40|215] "℃"  NBCMU
 SG_ NBICU06_Temp07 : 55|8@0+ (1,-40) [-40|215] "℃"  NBCMU
 SG_ NBICU06_Temp08 : 63|8@0+ (1,-40) [-40|215] "℃"  NBCMU

BO_ 2564554502 NBICU06_CellTemp02: 8 NBICU
 SG_ NBICU06_Temp09 : 7|8@0+ (1,-40) [-40|215] "℃"  NBCMU
 SG_ NBICU06_Temp10 : 15|8@0+ (1,-40) [-40|215] "℃"  NBCMU
 SG_ NBICU06_Temp11 : 23|8@0+ (1,-40) [-40|215] "℃"  NBCMU
 SG_ NBICU06_Temp12 : 31|8@0+ (1,-40) [-40|215] "℃"  NBCMU
 SG_ NBICU06_Temp13 : 39|8@0+ (1,-40) [-40|215] "℃"  NBCMU
 SG_ NBICU06_Temp14 : 47|8@0+ (1,-40) [-40|215] "℃"  NBCMU
 SG_ NBICU06_Temp15 : 55|8@0+ (1,-40) [-40|215] "℃"  NBCMU
 SG_ NBICU06_Temp16 : 63|8@0+ (1,-40) [-40|215] "℃"  NBCMU

BO_ 2564620038 NBICU06_CellTemp03: 8 NBICU
 SG_ NBICU06_Temp17 : 7|8@0+ (1,-40) [-40|215] "℃"  NBCMU
 SG_ NBICU06_Temp18 : 15|8@0+ (1,-40) [-40|215] "℃"  NBCMU
 SG_ NBICU06_Temp19 : 23|8@0+ (1,-40) [-40|215] "℃"  NBCMU
 SG_ NBICU06_Temp20 : 31|8@0+ (1,-40) [-40|215] "℃"  NBCMU
 SG_ NBICU06_Temp21 : 39|8@0+ (1,-40) [-40|215] "℃"  NBCMU
 SG_ NBICU06_Temp22 : 47|8@0+ (1,-40) [-40|215] "℃"  NBCMU
 SG_ NBICU06_Temp23 : 55|8@0+ (1,-40) [-40|215] "℃"  NBCMU
 SG_ NBICU06_Temp24 : 63|8@0+ (1,-40) [-40|215] "℃"  NBCMU

BO_ 2564685574 NBICU06_CellTemp04: 8 NBICU
 SG_ NBICU06_Temp25 : 7|8@0+ (1,-40) [-40|215] "℃"  NBCMU
 SG_ NBICU06_Temp26 : 15|8@0+ (1,-40) [-40|215] "℃"  NBCMU
 SG_ NBICU06_Temp27 : 23|8@0+ (1,-40) [-40|215] "℃"  NBCMU
 SG_ NBICU06_Temp28 : 31|8@0+ (1,-40) [-40|215] "℃"  NBCMU
 SG_ NBICU06_Temp29 : 39|8@0+ (1,-40) [-40|215] "℃"  NBCMU
 SG_ NBICU06_Temp30 : 47|8@0+ (1,-40) [-40|215] "℃"  NBCMU
 SG_ NBICU06_Temp31 : 55|8@0+ (1,-40) [-40|215] "℃"  NBCMU
 SG_ NBICU06_Temp32 : 63|8@0+ (1,-40) [-40|215] "℃"  NBCMU

BO_ 2564751110 NBICU06_CellTemp05: 8 NBICU
 SG_ NBICU06_Temp33 : 7|8@0+ (1,-40) [-40|215] "℃"  NBCMU
 SG_ NBICU06_Temp34 : 15|8@0+ (1,-40) [-40|215] "℃"  NBCMU
 SG_ NBICU06_Temp35 : 23|8@0+ (1,-40) [-40|215] "℃"  NBCMU
 SG_ NBICU06_Temp36 : 31|8@0+ (1,-40) [-40|215] "℃"  NBCMU

BO_ 2564947718 NBICU06_SW_Info: 8 NBICU
 SG_ NBICU06_NBCMU_Addr_SW : 7|8@0+ (1,0) [0|255] ""  NBCMU
 SG_ NBICU06_SW01 : 15|8@0+ (1,0) [0|255] ""  NBCMU
 SG_ NBICU06_SW02 : 23|8@0+ (1,0) [0|255] ""  NBCMU
 SG_ NBICU06_SW03 : 31|8@0+ (1,0) [0|255] ""  NBCMU
 SG_ NBICU06_SW04 : 39|8@0+ (1,0) [0|255] ""  NBCMU
 SG_ NBICU06_SW05 : 47|8@0+ (1,0) [0|255] ""  NBCMU
 SG_ NBICU06_SW06 : 55|8@0+ (1,0) [0|255] ""  NBCMU
 SG_ NBICU06_SW07 : 63|8@0+ (1,0) [0|255] ""  NBCMU

BO_ 2565013254 NBICU06_HW_Info: 8 NBICU
 SG_ NBICU06_NBCMU_Addr_HW : 7|8@0+ (1,0) [0|255] ""  NBCMU
 SG_ NBICU06_HW01 : 15|8@0+ (1,0) [0|255] ""  NBCMU
 SG_ NBICU06_HW02 : 23|8@0+ (1,0) [0|255] ""  NBCMU
 SG_ NBICU06_HW03 : 31|8@0+ (1,0) [0|255] ""  NBCMU
 SG_ NBICU06_HW04 : 39|8@0+ (1,0) [0|255] ""  NBCMU
 SG_ NBICU06_HW05 : 47|8@0+ (1,0) [0|255] ""  NBCMU
 SG_ NBICU06_HW06 : 55|8@0+ (1,0) [0|255] ""  NBCMU
 SG_ NBICU06_HW07 : 63|8@0+ (1,0) [0|255] ""  NBCMU

BO_ 2564677382 NBICU06_DiaResponse: 8 NBICU
 SG_ NBICU06_RespData : 7|64@0+ (1,0) [0|1.84467440737096E+019] ""  DAPP

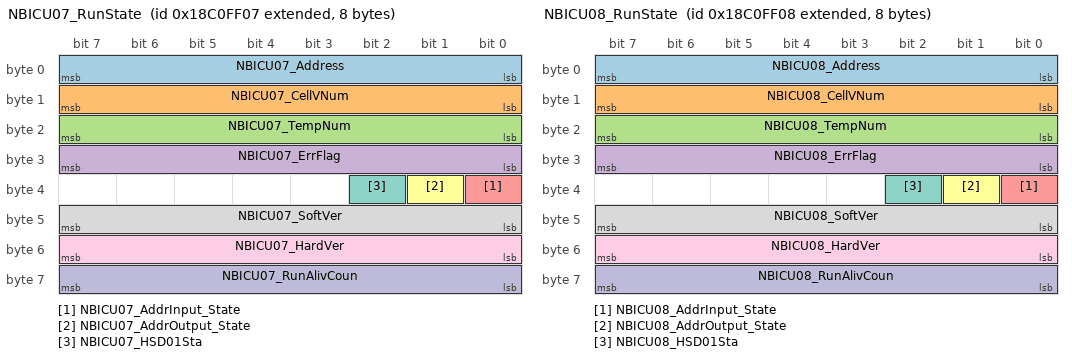
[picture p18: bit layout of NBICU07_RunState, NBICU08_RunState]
BO_ 2562785031 NBICU07_RunState: 8 NBICU
 SG_ NBICU07_Address : 7|8@0+ (1,0) [0|255] ""  NBCMU
 SG_ NBICU07_CellVNum : 15|8@0+ (1,0) [0|255] ""  NBCMU
 SG_ NBICU07_TempNum : 23|8@0+ (1,0) [0|255] ""  NBCMU
 SG_ NBICU07_ErrFlag : 31|8@0+ (1,0) [0|255] ""  NBCMU
 SG_ NBICU07_AddrInput_State : 32|1@0+ (1,0) [0|1] ""  NBCMU
 SG_ NBICU07_AddrOutput_State : 33|1@0+ (1,0) [0|1] ""  NBCMU
 SG_ NBICU07_HSD01Sta : 34|1@0+ (1,0) [0|1] ""  NBCMU
 SG_ NBICU07_SoftVer : 47|8@0+ (1,0) [0|255] ""  NBCMU
 SG_ NBICU07_HardVer : 55|8@0+ (1,0) [0|255] ""  NBCMU
 SG_ NBICU07_RunAlivCoun : 63|8@0+ (1,0) [0|255] ""  NBCMU

BO_ 2562850567 NBICU07_VoltExtremeInfo: 8 NBICU
 SG_ NBICU07_CellVoltMax : 7|16@0+ (1,0) [0|65535] "mV"  NBCMU,SBCMU
 SG_ NBICU07_CellVoltMin : 23|16@0+ (1,0) [0|65535] "mV"  NBCMU,SBCMU
 SG_ NBICU07_CellVoltMaxCode : 39|8@0+ (1,0) [0|255] ""  NBCMU,SBCMU
 SG_ NBICU07_CellVoltMinCode : 47|8@0+ (1,0) [0|255] ""  NBCMU,SBCMU
 SG_ NBICU07_CellSumVolt : 55|16@0+ (0.1,0) [0|6553.5] "V"  NBCMU,SBCMU

BO_ 2562916103 NBICU07_TempExtremeInfo: 8 NBICU
 SG_ NBICU07_CellTempMax : 7|8@0+ (1,-40) [-40|215] "℃"  NBCMU,SBCMU
 SG_ NBICU07_CellTempMin : 15|8@0+ (1,-40) [-40|215] "℃"  NBCMU,SBCMU
 SG_ NBICU07_CellTempAvg : 23|8@0+ (1,-40) [-40|215] "℃"  NBCMU,SBCMU
 SG_ NBICU07_CellTempMaxCode : 31|8@0+ (1,0) [0|255] ""  NBCMU,SBCMU
 SG_ NBICU07_CellTempMinCode : 39|8@0+ (1,0) [0|255] ""  NBCMU,SBCMU
 SG_ NBICU07_SupplyVolt : 40|9@0+ (0.1,0) [0|51.1] "V"  NBCMU,SBCMU
 SG_ NBICU07_PCB_Temp : 63|8@0+ (1,-40) [-40|215] "℃"  NBCMU,SBCMU

BO_ 2562981639 NBICU07_BalState: 8 NBICU
 SG_ NBICU07_Cell0108BalaSta : 7|8@0+ (1,0) [0|255] ""  NBCMU
 SG_ NBICU07_Cell0916BalaSta : 15|8@0+ (1,0) [0|255] ""  NBCMU
 SG_ NBICU07_Cell1724BalaSta : 23|8@0+ (1,0) [0|255] ""  NBCMU
 SG_ NBICU07_Cell2532BalaSta : 31|8@0+ (1,0) [0|255] ""  NBCMU
 SG_ NBICU07_Cell3336BalaSta : 35|4@0+ (1,0) [0|15] ""  NBCMU
 SG_ NBICU07_SysSOH : 47|8@0+ (1,0) [0|100] "%"  NBCMU
 SG_ NBICU07_CycleTime : 55|16@0+ (1,0) [0|65535] ""  NBCMU

BO_ 2563899143 NBICU07_CellVotlage01: 8 NBICU
 SG_ NBICU07_Cell01Volt : 7|16@0+ (1,0) [0|65535] "mV"  NBCMU
 SG_ NBICU07_Cell02Volt : 23|16@0+ (1,0) [0|65535] "mV"  NBCMU
 SG_ NBICU07_Cell03Volt : 39|16@0+ (1,0) [0|65535] "mV"  NBCMU
 SG_ NBICU07_Cell04Volt : 55|16@0+ (1,0) [0|65535] "mV"  NBCMU

BO_ 2563964679 NBICU07_CellVotlage02: 8 NBICU
 SG_ NBICU07_Cell05Volt : 7|16@0+ (1,0) [0|65535] "mV"  NBCMU
 SG_ NBICU07_Cell06Volt : 23|16@0+ (1,0) [0|65535] "mV"  NBCMU
 SG_ NBICU07_Cell07Volt : 39|16@0+ (1,0) [0|65535] "mV"  NBCMU
 SG_ NBICU07_Cell08Volt : 55|16@0+ (1,0) [0|65535] "mV"  NBCMU

BO_ 2564030215 NBICU07_CellVotlage03: 8 NBICU
 SG_ NBICU07_Cell09Volt : 7|16@0+ (1,0) [0|65535] "mV"  NBCMU
 SG_ NBICU07_Cell10Volt : 23|16@0+ (1,0) [0|65535] "mV"  NBCMU
 SG_ NBICU07_Cell11Volt : 39|16@0+ (1,0) [0|65535] "mV"  NBCMU
 SG_ NBICU07_Cell12Volt : 55|16@0+ (1,0) [0|65535] "mV"  NBCMU

BO_ 2564095751 NBICU07_CellVotlage04: 8 NBICU
 SG_ NBICU07_Cell13Volt : 7|16@0+ (1,0) [0|65535] "mV"  NBCMU
 SG_ NBICU07_Cell14Volt : 23|16@0+ (1,0) [0|65535] "mV"  NBCMU
 SG_ NBICU07_Cell15Volt : 39|16@0+ (1,0) [0|65535] "mV"  NBCMU
 SG_ NBICU07_Cell16Volt : 55|16@0+ (1,0) [0|65535] "mV"  NBCMU

BO_ 2564161287 NBICU07_CellVotlage05: 8 NBICU
 SG_ NBICU07_Cell17Volt : 7|16@0+ (1,0) [0|65535] "mV"  NBCMU
 SG_ NBICU07_Cell18Volt : 23|16@0+ (1,0) [0|65535] "mV"  NBCMU
 SG_ NBICU07_Cell19Volt : 39|16@0+ (1,0) [0|65535] "mV"  NBCMU
 SG_ NBICU07_Cell20Volt : 55|16@0+ (1,0) [0|65535] "mV"  NBCMU

BO_ 2564226823 NBICU07_CellVotlage06: 8 NBICU
 SG_ NBICU07_Cell21Volt : 7|16@0+ (1,0) [0|65535] "mV"  NBCMU
 SG_ NBICU07_Cell22Volt : 23|16@0+ (1,0) [0|65535] "mV"  NBCMU
 SG_ NBICU07_Cell23Volt : 39|16@0+ (1,0) [0|65535] "mV"  NBCMU
 SG_ NBICU07_Cell24Volt : 55|16@0+ (1,0) [0|65535] "mV"  NBCMU

BO_ 2564292359 NBICU07_CellVotlage07: 8 NBICU
 SG_ NBICU07_Cell25Volt : 7|16@0+ (1,0) [0|65535] "mV"  NBCMU
 SG_ NBICU07_Cell26Volt : 23|16@0+ (1,0) [0|65535] "mV"  NBCMU
 SG_ NBICU07_Cell27Volt : 39|16@0+ (1,0) [0|65535] "mV"  NBCMU
 SG_ NBICU07_Cell28Volt : 55|16@0+ (1,0) [0|65535] "mV"  NBCMU

BO_ 2564357895 NBICU07_CellVotlage08: 8 NBICU
 SG_ NBICU07_Cell29Volt : 7|16@0+ (1,0) [0|65535] "mV"  NBCMU
 SG_ NBICU07_Cell30Volt : 23|16@0+ (1,0) [0|65535] "mV"  NBCMU
 SG_ NBICU07_Cell31Volt : 39|16@0+ (1,0) [0|65535] "mV"  NBCMU
 SG_ NBICU07_Cell32Volt : 55|16@0+ (1,0) [0|65535] "mV"  NBCMU

BO_ 2564423431 NBICU07_CellVotlage09: 8 NBICU
 SG_ NBICU07_Cell33Volt : 7|16@0+ (1,0) [0|65535] "mV"  NBCMU
 SG_ NBICU07_Cell34Volt : 23|16@0+ (1,0) [0|65535] "mV"  NBCMU
 SG_ NBICU07_Cell35Volt : 39|16@0+ (1,0) [0|65535] "mV"  NBCMU
 SG_ NBICU07_Cell36Volt : 55|16@0+ (1,0) [0|65535] "mV"  NBCMU

BO_ 2564488967 NBICU07_CellTemp01: 8 NBICU
 SG_ NBICU07_Temp01 : 7|8@0+ (1,-40) [-40|215] "℃"  NBCMU
 SG_ NBICU07_Temp02 : 15|8@0+ (1,-40) [-40|215] "℃"  NBCMU
 SG_ NBICU07_Temp03 : 23|8@0+ (1,-40) [-40|215] "℃"  NBCMU
 SG_ NBICU07_Temp04 : 31|8@0+ (1,-40) [-40|215] "℃"  NBCMU
 SG_ NBICU07_Temp05 : 39|8@0+ (1,-40) [-40|215] "℃"  NBCMU
 SG_ NBICU07_Temp06 : 47|8@0+ (1,-40) [-40|215] "℃"  NBCMU
 SG_ NBICU07_Temp07 : 55|8@0+ (1,-40) [-40|215] "℃"  NBCMU
 SG_ NBICU07_Temp08 : 63|8@0+ (1,-40) [-40|215] "℃"  NBCMU

BO_ 2564554503 NBICU07_CellTemp02: 8 NBICU
 SG_ NBICU07_Temp09 : 7|8@0+ (1,-40) [-40|215] "℃"  NBCMU
 SG_ NBICU07_Temp10 : 15|8@0+ (1,-40) [-40|215] "℃"  NBCMU
 SG_ NBICU07_Temp11 : 23|8@0+ (1,-40) [-40|215] "℃"  NBCMU
 SG_ NBICU07_Temp12 : 31|8@0+ (1,-40) [-40|215] "℃"  NBCMU
 SG_ NBICU07_Temp13 : 39|8@0+ (1,-40) [-40|215] "℃"  NBCMU
 SG_ NBICU07_Temp14 : 47|8@0+ (1,-40) [-40|215] "℃"  NBCMU
 SG_ NBICU07_Temp15 : 55|8@0+ (1,-40) [-40|215] "℃"  NBCMU
 SG_ NBICU07_Temp16 : 63|8@0+ (1,-40) [-40|215] "℃"  NBCMU

BO_ 2564620039 NBICU07_CellTemp03: 8 NBICU
 SG_ NBICU07_Temp17 : 7|8@0+ (1,-40) [-40|215] "℃"  NBCMU
 SG_ NBICU07_Temp18 : 15|8@0+ (1,-40) [-40|215] "℃"  NBCMU
 SG_ NBICU07_Temp19 : 23|8@0+ (1,-40) [-40|215] "℃"  NBCMU
 SG_ NBICU07_Temp20 : 31|8@0+ (1,-40) [-40|215] "℃"  NBCMU
 SG_ NBICU07_Temp21 : 39|8@0+ (1,-40) [-40|215] "℃"  NBCMU
 SG_ NBICU07_Temp22 : 47|8@0+ (1,-40) [-40|215] "℃"  NBCMU
 SG_ NBICU07_Temp23 : 55|8@0+ (1,-40) [-40|215] "℃"  NBCMU
 SG_ NBICU07_Temp24 : 63|8@0+ (1,-40) [-40|215] "℃"  NBCMU

BO_ 2564685575 NBICU07_CellTemp04: 8 NBICU
 SG_ NBICU07_Temp25 : 7|8@0+ (1,-40) [-40|215] "℃"  NBCMU
 SG_ NBICU07_Temp26 : 15|8@0+ (1,-40) [-40|215] "℃"  NBCMU
 SG_ NBICU07_Temp27 : 23|8@0+ (1,-40) [-40|215] "℃"  NBCMU
 SG_ NBICU07_Temp28 : 31|8@0+ (1,-40) [-40|215] "℃"  NBCMU
 SG_ NBICU07_Temp29 : 39|8@0+ (1,-40) [-40|215] "℃"  NBCMU
 SG_ NBICU07_Temp30 : 47|8@0+ (1,-40) [-40|215] "℃"  NBCMU
 SG_ NBICU07_Temp31 : 55|8@0+ (1,-40) [-40|215] "℃"  NBCMU
 SG_ NBICU07_Temp32 : 63|8@0+ (1,-40) [-40|215] "℃"  NBCMU

BO_ 2564751111 NBICU07_CellTemp05: 8 NBICU
 SG_ NBICU07_Temp33 : 7|8@0+ (1,-40) [-40|215] "℃"  NBCMU
 SG_ NBICU07_Temp34 : 15|8@0+ (1,-40) [-40|215] "℃"  NBCMU
 SG_ NBICU07_Temp35 : 23|8@0+ (1,-40) [-40|215] "℃"  NBCMU
 SG_ NBICU07_Temp36 : 31|8@0+ (1,-40) [-40|215] "℃"  NBCMU

BO_ 2564947719 NBICU07_SW_Info: 8 NBICU
 SG_ NBICU07_NBCMU_Addr_SW : 7|8@0+ (1,0) [0|255] ""  NBCMU
 SG_ NBICU07_SW01 : 15|8@0+ (1,0) [0|255] ""  NBCMU
 SG_ NBICU07_SW02 : 23|8@0+ (1,0) [0|255] ""  NBCMU
 SG_ NBICU07_SW03 : 31|8@0+ (1,0) [0|255] ""  NBCMU
 SG_ NBICU07_SW04 : 39|8@0+ (1,0) [0|255] ""  NBCMU
 SG_ NBICU07_SW05 : 47|8@0+ (1,0) [0|255] ""  NBCMU
 SG_ NBICU07_SW06 : 55|8@0+ (1,0) [0|255] ""  NBCMU
 SG_ NBICU07_SW07 : 63|8@0+ (1,0) [0|255] ""  NBCMU

BO_ 2565013255 NBICU07_HW_Info: 8 NBICU
 SG_ NBICU07_NBCMU_Addr_HW : 7|8@0+ (1,0) [0|255] ""  NBCMU
 SG_ NBICU07_HW01 : 15|8@0+ (1,0) [0|255] ""  NBCMU
 SG_ NBICU07_HW02 : 23|8@0+ (1,0) [0|255] ""  NBCMU
 SG_ NBICU07_HW03 : 31|8@0+ (1,0) [0|255] ""  NBCMU
 SG_ NBICU07_HW04 : 39|8@0+ (1,0) [0|255] ""  NBCMU
 SG_ NBICU07_HW05 : 47|8@0+ (1,0) [0|255] ""  NBCMU
 SG_ NBICU07_HW06 : 55|8@0+ (1,0) [0|255] ""  NBCMU
 SG_ NBICU07_HW07 : 63|8@0+ (1,0) [0|255] ""  NBCMU

BO_ 2564677383 NBICU07_DiaResponse: 8 NBICU
 SG_ NBICU07_RespData : 7|64@0+ (1,0) [0|1.84467440737096E+019] ""  DAPP

BO_ 2562785032 NBICU08_RunState: 8 NBICU
 SG_ NBICU08_Address : 7|8@0+ (1,0) [0|255] ""  NBCMU
 SG_ NBICU08_CellVNum : 15|8@0+ (1,0) [0|255] ""  NBCMU
 SG_ NBICU08_TempNum : 23|8@0+ (1,0) [0|255] ""  NBCMU
 SG_ NBICU08_ErrFlag : 31|8@0+ (1,0) [0|255] ""  NBCMU
 SG_ NBICU08_AddrInput_State : 32|1@0+ (1,0) [0|1] ""  NBCMU
 SG_ NBICU08_AddrOutput_State : 33|1@0+ (1,0) [0|1] ""  NBCMU
 SG_ NBICU08_HSD01Sta : 34|1@0+ (1,0) [0|1] ""  NBCMU
 SG_ NBICU08_SoftVer : 47|8@0+ (1,0) [0|255] ""  NBCMU
 SG_ NBICU08_HardVer : 55|8@0+ (1,0) [0|255] ""  NBCMU
 SG_ NBICU08_RunAlivCoun : 63|8@0+ (1,0) [0|255] ""  NBCMU

BO_ 2562850568 NBICU08_VoltExtremeInfo: 8 NBICU
 SG_ NBICU08_CellVoltMax : 7|16@0+ (1,0) [0|65535] "mV"  NBCMU,SBCMU
 SG_ NBICU08_CellVoltMin : 23|16@0+ (1,0) [0|65535] "mV"  NBCMU,SBCMU
 SG_ NBICU08_CellVoltMaxCode : 39|8@0+ (1,0) [0|255] ""  NBCMU,SBCMU
 SG_ NBICU08_CellVoltMinCode : 47|8@0+ (1,0) [0|255] ""  NBCMU,SBCMU
 SG_ NBICU08_CellSumVolt : 55|16@0+ (0.1,0) [0|6553.5] "V"  NBCMU,SBCMU

BO_ 2562916104 NBICU08_TempExtremeInfo: 8 NBICU
 SG_ NBICU08_CellTempMax : 7|8@0+ (1,-40) [-40|215] "℃"  NBCMU,SBCMU
 SG_ NBICU08_CellTempMin : 15|8@0+ (1,-40) [-40|215] "℃"  NBCMU,SBCMU
 SG_ NBICU08_CellTempAvg : 23|8@0+ (1,-40) [-40|215] "℃"  NBCMU,SBCMU
 SG_ NBICU08_CellTempMaxCode : 31|8@0+ (1,0) [0|255] ""  NBCMU,SBCMU
 SG_ NBICU08_CellTempMinCode : 39|8@0+ (1,0) [0|255] ""  NBCMU,SBCMU
 SG_ NBICU08_SupplyVolt : 40|9@0+ (0.1,0) [0|51.1] "V"  NBCMU,SBCMU
 SG_ NBICU08_PCB_Temp : 63|8@0+ (1,-40) [-40|215] "℃"  NBCMU,SBCMU

BO_ 2562981640 NBICU08_BalState: 8 NBICU
 SG_ NBICU08_Cell0108BalaSta : 7|8@0+ (1,0) [0|255] ""  NBCMU
 SG_ NBICU08_Cell0916BalaSta : 15|8@0+ (1,0) [0|255] ""  NBCMU
 SG_ NBICU08_Cell1724BalaSta : 23|8@0+ (1,0) [0|255] ""  NBCMU
 SG_ NBICU08_Cell2532BalaSta : 31|8@0+ (1,0) [0|255] ""  NBCMU
 SG_ NBICU08_Cell3336BalaSta : 35|4@0+ (1,0) [0|15] ""  NBCMU
 SG_ NBICU08_SysSOH : 47|8@0+ (1,0) [0|100] "%"  NBCMU
 SG_ NBICU08_CycleTime : 55|16@0+ (1,0) [0|65535] ""  NBCMU

BO_ 2563899144 NBICU08_CellVotlage01: 8 NBICU
 SG_ NBICU08_Cell01Volt : 7|16@0+ (1,0) [0|65535] "mV"  NBCMU
 SG_ NBICU08_Cell02Volt : 23|16@0+ (1,0) [0|65535] "mV"  NBCMU
 SG_ NBICU08_Cell03Volt : 39|16@0+ (1,0) [0|65535] "mV"  NBCMU
 SG_ NBICU08_Cell04Volt : 55|16@0+ (1,0) [0|65535] "mV"  NBCMU

BO_ 2563964680 NBICU08_CellVotlage02: 8 NBICU
 SG_ NBICU08_Cell05Volt : 7|16@0+ (1,0) [0|65535] "mV"  NBCMU
 SG_ NBICU08_Cell06Volt : 23|16@0+ (1,0) [0|65535] "mV"  NBCMU
 SG_ NBICU08_Cell07Volt : 39|16@0+ (1,0) [0|65535] "mV"  NBCMU
 SG_ NBICU08_Cell08Volt : 55|16@0+ (1,0) [0|65535] "mV"  NBCMU

BO_ 2564030216 NBICU08_CellVotlage03: 8 NBICU
 SG_ NBICU08_Cell09Volt : 7|16@0+ (1,0) [0|65535] "mV"  NBCMU
 SG_ NBICU08_Cell10Volt : 23|16@0+ (1,0) [0|65535] "mV"  NBCMU
 SG_ NBICU08_Cell11Volt : 39|16@0+ (1,0) [0|65535] "mV"  NBCMU
 SG_ NBICU08_Cell12Volt : 55|16@0+ (1,0) [0|65535] "mV"  NBCMU

BO_ 2564095752 NBICU08_CellVotlage04: 8 NBICU
 SG_ NBICU08_Cell13Volt : 7|16@0+ (1,0) [0|65535] "mV"  NBCMU
 SG_ NBICU08_Cell14Volt : 23|16@0+ (1,0) [0|65535] "mV"  NBCMU
 SG_ NBICU08_Cell15Volt : 39|16@0+ (1,0) [0|65535] "mV"  NBCMU
 SG_ NBICU08_Cell16Volt : 55|16@0+ (1,0) [0|65535] "mV"  NBCMU

BO_ 2564161288 NBICU08_CellVotlage05: 8 NBICU
 SG_ NBICU08_Cell17Volt : 7|16@0+ (1,0) [0|65535] "mV"  NBCMU
 SG_ NBICU08_Cell18Volt : 23|16@0+ (1,0) [0|65535] "mV"  NBCMU
 SG_ NBICU08_Cell19Volt : 39|16@0+ (1,0) [0|65535] "mV"  NBCMU
 SG_ NBICU08_Cell20Volt : 55|16@0+ (1,0) [0|65535] "mV"  NBCMU

BO_ 2564226824 NBICU08_CellVotlage06: 8 NBICU
 SG_ NBICU08_Cell21Volt : 7|16@0+ (1,0) [0|65535] "mV"  NBCMU
 SG_ NBICU08_Cell22Volt : 23|16@0+ (1,0) [0|65535] "mV"  NBCMU
 SG_ NBICU08_Cell23Volt : 39|16@0+ (1,0) [0|65535] "mV"  NBCMU
 SG_ NBICU08_Cell24Volt : 55|16@0+ (1,0) [0|65535] "mV"  NBCMU

BO_ 2564292360 NBICU08_CellVotlage07: 8 NBICU
 SG_ NBICU08_Cell25Volt : 7|16@0+ (1,0) [0|65535] "mV"  NBCMU
 SG_ NBICU08_Cell26Volt : 23|16@0+ (1,0) [0|65535] "mV"  NBCMU
 SG_ NBICU08_Cell27Volt : 39|16@0+ (1,0) [0|65535] "mV"  NBCMU
 SG_ NBICU08_Cell28Volt : 55|16@0+ (1,0) [0|65535] "mV"  NBCMU

BO_ 2564357896 NBICU08_CellVotlage08: 8 NBICU
 SG_ NBICU08_Cell29Volt : 7|16@0+ (1,0) [0|65535] "mV"  NBCMU
 SG_ NBICU08_Cell30Volt : 23|16@0+ (1,0) [0|65535] "mV"  NBCMU
 SG_ NBICU08_Cell31Volt : 39|16@0+ (1,0) [0|65535] "mV"  NBCMU
 SG_ NBICU08_Cell32Volt : 55|16@0+ (1,0) [0|65535] "mV"  NBCMU

BO_ 2564423432 NBICU08_CellVotlage09: 8 NBICU
 SG_ NBICU08_Cell33Volt : 7|16@0+ (1,0) [0|65535] "mV"  NBCMU
 SG_ NBICU08_Cell34Volt : 23|16@0+ (1,0) [0|65535] "mV"  NBCMU
 SG_ NBICU08_Cell35Volt : 39|16@0+ (1,0) [0|65535] "mV"  NBCMU
 SG_ NBICU08_Cell36Volt : 55|16@0+ (1,0) [0|65535] "mV"  NBCMU

BO_ 2564488968 NBICU08_CellTemp01: 8 NBICU
 SG_ NBICU08_Temp01 : 7|8@0+ (1,-40) [-40|215] "℃"  NBCMU
 SG_ NBICU08_Temp02 : 15|8@0+ (1,-40) [-40|215] "℃"  NBCMU
 SG_ NBICU08_Temp03 : 23|8@0+ (1,-40) [-40|215] "℃"  NBCMU
 SG_ NBICU08_Temp04 : 31|8@0+ (1,-40) [-40|215] "℃"  NBCMU
 SG_ NBICU08_Temp05 : 39|8@0+ (1,-40) [-40|215] "℃"  NBCMU
 SG_ NBICU08_Temp06 : 47|8@0+ (1,-40) [-40|215] "℃"  NBCMU
 SG_ NBICU08_Temp07 : 55|8@0+ (1,-40) [-40|215] "℃"  NBCMU
 SG_ NBICU08_Temp08 : 63|8@0+ (1,-40) [-40|215] "℃"  NBCMU

BO_ 2564554504 NBICU08_CellTemp02: 8 NBICU
 SG_ NBICU08_Temp09 : 7|8@0+ (1,-40) [-40|215] "℃"  NBCMU
 SG_ NBICU08_Temp10 : 15|8@0+ (1,-40) [-40|215] "℃"  NBCMU
 SG_ NBICU08_Temp11 : 23|8@0+ (1,-40) [-40|215] "℃"  NBCMU
 SG_ NBICU08_Temp12 : 31|8@0+ (1,-40) [-40|215] "℃"  NBCMU
 SG_ NBICU08_Temp13 : 39|8@0+ (1,-40) [-40|215] "℃"  NBCMU
 SG_ NBICU08_Temp14 : 47|8@0+ (1,-40) [-40|215] "℃"  NBCMU
 SG_ NBICU08_Temp15 : 55|8@0+ (1,-40) [-40|215] "℃"  NBCMU
 SG_ NBICU08_Temp16 : 63|8@0+ (1,-40) [-40|215] "℃"  NBCMU

BO_ 2564620040 NBICU08_CellTemp03: 8 NBICU
 SG_ NBICU08_Temp17 : 7|8@0+ (1,-40) [-40|215] "℃"  NBCMU
 SG_ NBICU08_Temp18 : 15|8@0+ (1,-40) [-40|215] "℃"  NBCMU
 SG_ NBICU08_Temp19 : 23|8@0+ (1,-40) [-40|215] "℃"  NBCMU
 SG_ NBICU08_Temp20 : 31|8@0+ (1,-40) [-40|215] "℃"  NBCMU
 SG_ NBICU08_Temp21 : 39|8@0+ (1,-40) [-40|215] "℃"  NBCMU
 SG_ NBICU08_Temp22 : 47|8@0+ (1,-40) [-40|215] "℃"  NBCMU
 SG_ NBICU08_Temp23 : 55|8@0+ (1,-40) [-40|215] "℃"  NBCMU
 SG_ NBICU08_Temp24 : 63|8@0+ (1,-40) [-40|215] "℃"  NBCMU

BO_ 2564685576 NBICU08_CellTemp04: 8 NBICU
 SG_ NBICU08_Temp25 : 7|8@0+ (1,-40) [-40|215] "℃"  NBCMU
 SG_ NBICU08_Temp26 : 15|8@0+ (1,-40) [-40|215] "℃"  NBCMU
 SG_ NBICU08_Temp27 : 23|8@0+ (1,-40) [-40|215] "℃"  NBCMU
 SG_ NBICU08_Temp28 : 31|8@0+ (1,-40) [-40|215] "℃"  NBCMU
 SG_ NBICU08_Temp29 : 39|8@0+ (1,-40) [-40|215] "℃"  NBCMU
 SG_ NBICU08_Temp30 : 47|8@0+ (1,-40) [-40|215] "℃"  NBCMU
 SG_ NBICU08_Temp31 : 55|8@0+ (1,-40) [-40|215] "℃"  NBCMU
 SG_ NBICU08_Temp32 : 63|8@0+ (1,-40) [-40|215] "℃"  NBCMU

BO_ 2564751112 NBICU08_CellTemp05: 8 NBICU
 SG_ NBICU08_Temp33 : 7|8@0+ (1,-40) [-40|215] "℃"  NBCMU
 SG_ NBICU08_Temp34 : 15|8@0+ (1,-40) [-40|215] "℃"  NBCMU
 SG_ NBICU08_Temp35 : 23|8@0+ (1,-40) [-40|215] "℃"  NBCMU
 SG_ NBICU08_Temp36 : 31|8@0+ (1,-40) [-40|215] "℃"  NBCMU

BO_ 2564947720 NBICU08_SW_Info: 8 NBICU
 SG_ NBICU08_NBCMU_Addr_SW : 7|8@0+ (1,0) [0|255] ""  NBCMU
 SG_ NBICU08_SW01 : 15|8@0+ (1,0) [0|255] ""  NBCMU
 SG_ NBICU08_SW02 : 23|8@0+ (1,0) [0|255] ""  NBCMU
 SG_ NBICU08_SW03 : 31|8@0+ (1,0) [0|255] ""  NBCMU
 SG_ NBICU08_SW04 : 39|8@0+ (1,0) [0|255] ""  NBCMU
 SG_ NBICU08_SW05 : 47|8@0+ (1,0) [0|255] ""  NBCMU
 SG_ NBICU08_SW06 : 55|8@0+ (1,0) [0|255] ""  NBCMU
 SG_ NBICU08_SW07 : 63|8@0+ (1,0) [0|255] ""  NBCMU

BO_ 2565013256 NBICU08_HW_Info: 8 NBICU
 SG_ NBICU08_NBCMU_Addr_HW : 7|8@0+ (1,0) [0|255] ""  NBCMU
 SG_ NBICU08_HW01 : 15|8@0+ (1,0) [0|255] ""  NBCMU
 SG_ NBICU08_HW02 : 23|8@0+ (1,0) [0|255] ""  NBCMU
 SG_ NBICU08_HW03 : 31|8@0+ (1,0) [0|255] ""  NBCMU
 SG_ NBICU08_HW04 : 39|8@0+ (1,0) [0|255] ""  NBCMU
 SG_ NBICU08_HW05 : 47|8@0+ (1,0) [0|255] ""  NBCMU
 SG_ NBICU08_HW06 : 55|8@0+ (1,0) [0|255] ""  NBCMU
 SG_ NBICU08_HW07 : 63|8@0+ (1,0) [0|255] ""  NBCMU

BO_ 2564677384 NBICU08_DiaResponse: 8 NBICU
 SG_ NBICU08_RespData : 7|64@0+ (1,0) [0|1.84467440737096E+019] ""  DAPP

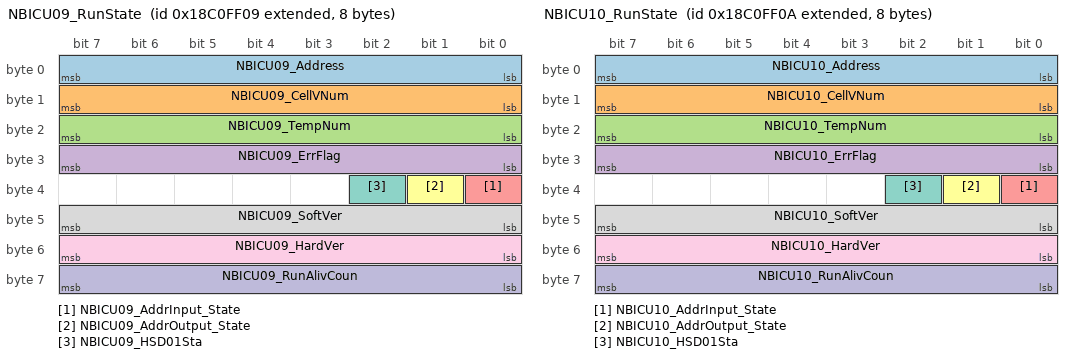
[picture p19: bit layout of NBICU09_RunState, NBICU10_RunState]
BO_ 2562785033 NBICU09_RunState: 8 NBICU
 SG_ NBICU09_Address : 7|8@0+ (1,0) [0|255] ""  NBCMU
 SG_ NBICU09_CellVNum : 15|8@0+ (1,0) [0|255] ""  NBCMU
 SG_ NBICU09_TempNum : 23|8@0+ (1,0) [0|255] ""  NBCMU
 SG_ NBICU09_ErrFlag : 31|8@0+ (1,0) [0|255] ""  NBCMU
 SG_ NBICU09_AddrInput_State : 32|1@0+ (1,0) [0|1] ""  NBCMU
 SG_ NBICU09_AddrOutput_State : 33|1@0+ (1,0) [0|1] ""  NBCMU
 SG_ NBICU09_HSD01Sta : 34|1@0+ (1,0) [0|1] ""  NBCMU
 SG_ NBICU09_SoftVer : 47|8@0+ (1,0) [0|255] ""  NBCMU
 SG_ NBICU09_HardVer : 55|8@0+ (1,0) [0|255] ""  NBCMU
 SG_ NBICU09_RunAlivCoun : 63|8@0+ (1,0) [0|255] ""  NBCMU

BO_ 2562850569 NBICU09_VoltExtremeInfo: 8 NBICU
 SG_ NBICU09_CellVoltMax : 7|16@0+ (1,0) [0|65535] "mV"  NBCMU,SBCMU
 SG_ NBICU09_CellVoltMin : 23|16@0+ (1,0) [0|65535] "mV"  NBCMU,SBCMU
 SG_ NBICU09_CellVoltMaxCode : 39|8@0+ (1,0) [0|255] ""  NBCMU,SBCMU
 SG_ NBICU09_CellVoltMinCode : 47|8@0+ (1,0) [0|255] ""  NBCMU,SBCMU
 SG_ NBICU09_CellSumVolt : 55|16@0+ (0.1,0) [0|6553.5] "V"  NBCMU,SBCMU

BO_ 2562916105 NBICU09_TempExtremeInfo: 8 NBICU
 SG_ NBICU09_CellTempMax : 7|8@0+ (1,-40) [-40|215] "℃"  NBCMU,SBCMU
 SG_ NBICU09_CellTempMin : 15|8@0+ (1,-40) [-40|215] "℃"  NBCMU,SBCMU
 SG_ NBICU09_CellTempAvg : 23|8@0+ (1,-40) [-40|215] "℃"  NBCMU,SBCMU
 SG_ NBICU09_CellTempMaxCode : 31|8@0+ (1,0) [0|255] ""  NBCMU,SBCMU
 SG_ NBICU09_CellTempMinCode : 39|8@0+ (1,0) [0|255] ""  NBCMU,SBCMU
 SG_ NBICU09_SupplyVolt : 40|9@0+ (0.1,0) [0|51.1] "V"  NBCMU,SBCMU
 SG_ NBICU09_PCB_Temp : 63|8@0+ (1,-40) [-40|215] "℃"  NBCMU,SBCMU

BO_ 2562981641 NBICU09_BalState: 8 NBICU
 SG_ NBICU09_Cell0108BalaSta : 7|8@0+ (1,0) [0|255] ""  NBCMU
 SG_ NBICU09_Cell0916BalaSta : 15|8@0+ (1,0) [0|255] ""  NBCMU
 SG_ NBICU09_Cell1724BalaSta : 23|8@0+ (1,0) [0|255] ""  NBCMU
 SG_ NBICU09_Cell2532BalaSta : 31|8@0+ (1,0) [0|255] ""  NBCMU
 SG_ NBICU09_Cell3336BalaSta : 35|4@0+ (1,0) [0|15] ""  NBCMU
 SG_ NBICU09_SysSOH : 47|8@0+ (1,0) [0|100] "%"  NBCMU
 SG_ NBICU09_CycleTime : 55|16@0+ (1,0) [0|65535] ""  NBCMU

BO_ 2563899145 NBICU09_CellVotlage01: 8 NBICU
 SG_ NBICU09_Cell01Volt : 7|16@0+ (1,0) [0|65535] "mV"  NBCMU
 SG_ NBICU09_Cell02Volt : 23|16@0+ (1,0) [0|65535] "mV"  NBCMU
 SG_ NBICU09_Cell03Volt : 39|16@0+ (1,0) [0|65535] "mV"  NBCMU
 SG_ NBICU09_Cell04Volt : 55|16@0+ (1,0) [0|65535] "mV"  NBCMU

BO_ 2563964681 NBICU09_CellVotlage02: 8 NBICU
 SG_ NBICU09_Cell05Volt : 7|16@0+ (1,0) [0|65535] "mV"  NBCMU
 SG_ NBICU09_Cell06Volt : 23|16@0+ (1,0) [0|65535] "mV"  NBCMU
 SG_ NBICU09_Cell07Volt : 39|16@0+ (1,0) [0|65535] "mV"  NBCMU
 SG_ NBICU09_Cell08Volt : 55|16@0+ (1,0) [0|65535] "mV"  NBCMU

BO_ 2564030217 NBICU09_CellVotlage03: 8 NBICU
 SG_ NBICU09_Cell09Volt : 7|16@0+ (1,0) [0|65535] "mV"  NBCMU
 SG_ NBICU09_Cell10Volt : 23|16@0+ (1,0) [0|65535] "mV"  NBCMU
 SG_ NBICU09_Cell11Volt : 39|16@0+ (1,0) [0|65535] "mV"  NBCMU
 SG_ NBICU09_Cell12Volt : 55|16@0+ (1,0) [0|65535] "mV"  NBCMU

BO_ 2564095753 NBICU09_CellVotlage04: 8 NBICU
 SG_ NBICU09_Cell13Volt : 7|16@0+ (1,0) [0|65535] "mV"  NBCMU
 SG_ NBICU09_Cell14Volt : 23|16@0+ (1,0) [0|65535] "mV"  NBCMU
 SG_ NBICU09_Cell15Volt : 39|16@0+ (1,0) [0|65535] "mV"  NBCMU
 SG_ NBICU09_Cell16Volt : 55|16@0+ (1,0) [0|65535] "mV"  NBCMU

BO_ 2564161289 NBICU09_CellVotlage05: 8 NBICU
 SG_ NBICU09_Cell17Volt : 7|16@0+ (1,0) [0|65535] "mV"  NBCMU
 SG_ NBICU09_Cell18Volt : 23|16@0+ (1,0) [0|65535] "mV"  NBCMU
 SG_ NBICU09_Cell19Volt : 39|16@0+ (1,0) [0|65535] "mV"  NBCMU
 SG_ NBICU09_Cell20Volt : 55|16@0+ (1,0) [0|65535] "mV"  NBCMU

BO_ 2564226825 NBICU09_CellVotlage06: 8 NBICU
 SG_ NBICU09_Cell21Volt : 7|16@0+ (1,0) [0|65535] "mV"  NBCMU
 SG_ NBICU09_Cell22Volt : 23|16@0+ (1,0) [0|65535] "mV"  NBCMU
 SG_ NBICU09_Cell23Volt : 39|16@0+ (1,0) [0|65535] "mV"  NBCMU
 SG_ NBICU09_Cell24Volt : 55|16@0+ (1,0) [0|65535] "mV"  NBCMU

BO_ 2564292361 NBICU09_CellVotlage07: 8 NBICU
 SG_ NBICU09_Cell25Volt : 7|16@0+ (1,0) [0|65535] "mV"  NBCMU
 SG_ NBICU09_Cell26Volt : 23|16@0+ (1,0) [0|65535] "mV"  NBCMU
 SG_ NBICU09_Cell27Volt : 39|16@0+ (1,0) [0|65535] "mV"  NBCMU
 SG_ NBICU09_Cell28Volt : 55|16@0+ (1,0) [0|65535] "mV"  NBCMU

BO_ 2564357897 NBICU09_CellVotlage08: 8 NBICU
 SG_ NBICU09_Cell29Volt : 7|16@0+ (1,0) [0|65535] "mV"  NBCMU
 SG_ NBICU09_Cell30Volt : 23|16@0+ (1,0) [0|65535] "mV"  NBCMU
 SG_ NBICU09_Cell31Volt : 39|16@0+ (1,0) [0|65535] "mV"  NBCMU
 SG_ NBICU09_Cell32Volt : 55|16@0+ (1,0) [0|65535] "mV"  NBCMU

BO_ 2564423433 NBICU09_CellVotlage09: 8 NBICU
 SG_ NBICU09_Cell33Volt : 7|16@0+ (1,0) [0|65535] "mV"  NBCMU
 SG_ NBICU09_Cell34Volt : 23|16@0+ (1,0) [0|65535] "mV"  NBCMU
 SG_ NBICU09_Cell35Volt : 39|16@0+ (1,0) [0|65535] "mV"  NBCMU
 SG_ NBICU09_Cell36Volt : 55|16@0+ (1,0) [0|65535] "mV"  NBCMU

BO_ 2564488969 NBICU09_CellTemp01: 8 NBICU
 SG_ NBICU09_Temp01 : 7|8@0+ (1,-40) [-40|215] "℃"  NBCMU
 SG_ NBICU09_Temp02 : 15|8@0+ (1,-40) [-40|215] "℃"  NBCMU
 SG_ NBICU09_Temp03 : 23|8@0+ (1,-40) [-40|215] "℃"  NBCMU
 SG_ NBICU09_Temp04 : 31|8@0+ (1,-40) [-40|215] "℃"  NBCMU
 SG_ NBICU09_Temp05 : 39|8@0+ (1,-40) [-40|215] "℃"  NBCMU
 SG_ NBICU09_Temp06 : 47|8@0+ (1,-40) [-40|215] "℃"  NBCMU
 SG_ NBICU09_Temp07 : 55|8@0+ (1,-40) [-40|215] "℃"  NBCMU
 SG_ NBICU09_Temp08 : 63|8@0+ (1,-40) [-40|215] "℃"  NBCMU

BO_ 2564554505 NBICU09_CellTemp02: 8 NBICU
 SG_ NBICU09_Temp09 : 7|8@0+ (1,-40) [-40|215] "℃"  NBCMU
 SG_ NBICU09_Temp10 : 15|8@0+ (1,-40) [-40|215] "℃"  NBCMU
 SG_ NBICU09_Temp11 : 23|8@0+ (1,-40) [-40|215] "℃"  NBCMU
 SG_ NBICU09_Temp12 : 31|8@0+ (1,-40) [-40|215] "℃"  NBCMU
 SG_ NBICU09_Temp13 : 39|8@0+ (1,-40) [-40|215] "℃"  NBCMU
 SG_ NBICU09_Temp14 : 47|8@0+ (1,-40) [-40|215] "℃"  NBCMU
 SG_ NBICU09_Temp15 : 55|8@0+ (1,-40) [-40|215] "℃"  NBCMU
 SG_ NBICU09_Temp16 : 63|8@0+ (1,-40) [-40|215] "℃"  NBCMU

BO_ 2564620041 NBICU09_CellTemp03: 8 NBICU
 SG_ NBICU09_Temp17 : 7|8@0+ (1,-40) [-40|215] "℃"  NBCMU
 SG_ NBICU09_Temp18 : 15|8@0+ (1,-40) [-40|215] "℃"  NBCMU
 SG_ NBICU09_Temp19 : 23|8@0+ (1,-40) [-40|215] "℃"  NBCMU
 SG_ NBICU09_Temp20 : 31|8@0+ (1,-40) [-40|215] "℃"  NBCMU
 SG_ NBICU09_Temp21 : 39|8@0+ (1,-40) [-40|215] "℃"  NBCMU
 SG_ NBICU09_Temp22 : 47|8@0+ (1,-40) [-40|215] "℃"  NBCMU
 SG_ NBICU09_Temp23 : 55|8@0+ (1,-40) [-40|215] "℃"  NBCMU
 SG_ NBICU09_Temp24 : 63|8@0+ (1,-40) [-40|215] "℃"  NBCMU

BO_ 2564685577 NBICU09_CellTemp04: 8 NBICU
 SG_ NBICU09_Temp25 : 7|8@0+ (1,-40) [-40|215] "℃"  NBCMU
 SG_ NBICU09_Temp26 : 15|8@0+ (1,-40) [-40|215] "℃"  NBCMU
 SG_ NBICU09_Temp27 : 23|8@0+ (1,-40) [-40|215] "℃"  NBCMU
 SG_ NBICU09_Temp28 : 31|8@0+ (1,-40) [-40|215] "℃"  NBCMU
 SG_ NBICU09_Temp29 : 39|8@0+ (1,-40) [-40|215] "℃"  NBCMU
 SG_ NBICU09_Temp30 : 47|8@0+ (1,-40) [-40|215] "℃"  NBCMU
 SG_ NBICU09_Temp31 : 55|8@0+ (1,-40) [-40|215] "℃"  NBCMU
 SG_ NBICU09_Temp32 : 63|8@0+ (1,-40) [-40|215] "℃"  NBCMU

BO_ 2564751113 NBICU09_CellTemp05: 8 NBICU
 SG_ NBICU09_Temp33 : 7|8@0+ (1,-40) [-40|215] "℃"  NBCMU
 SG_ NBICU09_Temp34 : 15|8@0+ (1,-40) [-40|215] "℃"  NBCMU
 SG_ NBICU09_Temp35 : 23|8@0+ (1,-40) [-40|215] "℃"  NBCMU
 SG_ NBICU09_Temp36 : 31|8@0+ (1,-40) [-40|215] "℃"  NBCMU

BO_ 2564947721 NBICU09_SW_Info: 8 NBICU
 SG_ NBICU09_NBCMU_Addr_SW : 7|8@0+ (1,0) [0|255] ""  NBCMU
 SG_ NBICU09_SW01 : 15|8@0+ (1,0) [0|255] ""  NBCMU
 SG_ NBICU09_SW02 : 23|8@0+ (1,0) [0|255] ""  NBCMU
 SG_ NBICU09_SW03 : 31|8@0+ (1,0) [0|255] ""  NBCMU
 SG_ NBICU09_SW04 : 39|8@0+ (1,0) [0|255] ""  NBCMU
 SG_ NBICU09_SW05 : 47|8@0+ (1,0) [0|255] ""  NBCMU
 SG_ NBICU09_SW06 : 55|8@0+ (1,0) [0|255] ""  NBCMU
 SG_ NBICU09_SW07 : 63|8@0+ (1,0) [0|255] ""  NBCMU

BO_ 2565013257 NBICU09_HW_Info: 8 NBICU
 SG_ NBICU09_NBCMU_Addr_HW : 7|8@0+ (1,0) [0|255] ""  NBCMU
 SG_ NBICU09_HW01 : 15|8@0+ (1,0) [0|255] ""  NBCMU
 SG_ NBICU09_HW02 : 23|8@0+ (1,0) [0|255] ""  NBCMU
 SG_ NBICU09_HW03 : 31|8@0+ (1,0) [0|255] ""  NBCMU
 SG_ NBICU09_HW04 : 39|8@0+ (1,0) [0|255] ""  NBCMU
 SG_ NBICU09_HW05 : 47|8@0+ (1,0) [0|255] ""  NBCMU
 SG_ NBICU09_HW06 : 55|8@0+ (1,0) [0|255] ""  NBCMU
 SG_ NBICU09_HW07 : 63|8@0+ (1,0) [0|255] ""  NBCMU

BO_ 2564677385 NBICU09_DiaResponse: 8 NBICU
 SG_ NBICU09_RespData : 7|64@0+ (1,0) [0|1.84467440737096E+019] ""  DAPP

BO_ 2562785034 NBICU10_RunState: 8 NBICU
 SG_ NBICU10_Address : 7|8@0+ (1,0) [0|255] ""  NBCMU
 SG_ NBICU10_CellVNum : 15|8@0+ (1,0) [0|255] ""  NBCMU
 SG_ NBICU10_TempNum : 23|8@0+ (1,0) [0|255] ""  NBCMU
 SG_ NBICU10_ErrFlag : 31|8@0+ (1,0) [0|255] ""  NBCMU
 SG_ NBICU10_AddrInput_State : 32|1@0+ (1,0) [0|1] ""  NBCMU
 SG_ NBICU10_AddrOutput_State : 33|1@0+ (1,0) [0|1] ""  NBCMU
 SG_ NBICU10_HSD01Sta : 34|1@0+ (1,0) [0|1] ""  NBCMU
 SG_ NBICU10_SoftVer : 47|8@0+ (1,0) [0|255] ""  NBCMU
 SG_ NBICU10_HardVer : 55|8@0+ (1,0) [0|255] ""  NBCMU
 SG_ NBICU10_RunAlivCoun : 63|8@0+ (1,0) [0|255] ""  NBCMU

BO_ 2562850570 NBICU10_VoltExtremeInfo: 8 NBICU
 SG_ NBICU10_CellVoltMax : 7|16@0+ (1,0) [0|65535] "mV"  NBCMU
 SG_ NBICU10_CellVoltMin : 23|16@0+ (1,0) [0|65535] "mV"  NBCMU
 SG_ NBICU10_CellVoltMaxCode : 39|8@0+ (1,0) [0|255] ""  NBCMU
 SG_ NBICU10_CellVoltMinCode : 47|8@0+ (1,0) [0|255] ""  NBCMU
 SG_ NBICU10_CellSumVolt : 55|16@0+ (0.1,0) [0|6553.5] "V"  NBCMU

BO_ 2562916106 NBICU10_TempExtremeInfo: 8 NBICU
 SG_ NBICU10_CellTempMax : 7|8@0+ (1,-40) [-40|215] "℃"  NBCMU
 SG_ NBICU10_CellTempMin : 15|8@0+ (1,-40) [-40|215] "℃"  NBCMU
 SG_ NBICU10_CellTempAvg : 23|8@0+ (1,-40) [-40|215] "℃"  NBCMU
 SG_ NBICU10_CellTempMaxCode : 31|8@0+ (1,0) [0|255] ""  NBCMU
 SG_ NBICU10_CellTempMinCode : 39|8@0+ (1,0) [0|255] ""  NBCMU
 SG_ NBICU10_SupplyVolt : 40|9@0+ (0.1,0) [0|51.1] "V"  NBCMU
 SG_ NBICU10_PCB_Temp : 63|8@0+ (1,-40) [-40|215] "℃"  NBCMU

BO_ 2562981642 NBICU10_BalState: 8 NBICU
 SG_ NBICU10_Cell0108BalaSta : 7|8@0+ (1,0) [0|255] ""  NBCMU
 SG_ NBICU10_Cell0916BalaSta : 15|8@0+ (1,0) [0|255] ""  NBCMU
 SG_ NBICU10_Cell1724BalaSta : 23|8@0+ (1,0) [0|255] ""  NBCMU
 SG_ NBICU10_Cell2532BalaSta : 31|8@0+ (1,0) [0|255] ""  NBCMU
 SG_ NBICU10_Cell3336BalaSta : 35|4@0+ (1,0) [0|15] ""  NBCMU
 SG_ NBICU10_SysSOH : 47|8@0+ (1,0) [0|100] "%"  NBCMU
 SG_ NBICU10_CycleTime : 55|16@0+ (1,0) [0|65535] ""  NBCMU

BO_ 2563899146 NBICU10_CellVotlage01: 8 NBICU
 SG_ NBICU10_Cell01Volt : 7|16@0+ (1,0) [0|65535] "mV"  NBCMU
 SG_ NBICU10_Cell02Volt : 23|16@0+ (1,0) [0|65535] "mV"  NBCMU
 SG_ NBICU10_Cell03Volt : 39|16@0+ (1,0) [0|65535] "mV"  NBCMU
 SG_ NBICU10_Cell04Volt : 55|16@0+ (1,0) [0|65535] "mV"  NBCMU

BO_ 2563964682 NBICU10_CellVotlage02: 8 NBICU
 SG_ NBICU10_Cell05Volt : 7|16@0+ (1,0) [0|65535] "mV"  NBCMU
 SG_ NBICU10_Cell06Volt : 23|16@0+ (1,0) [0|65535] "mV"  NBCMU
 SG_ NBICU10_Cell07Volt : 39|16@0+ (1,0) [0|65535] "mV"  NBCMU
 SG_ NBICU10_Cell08Volt : 55|16@0+ (1,0) [0|65535] "mV"  NBCMU

BO_ 2564030218 NBICU10_CellVotlage03: 8 NBICU
 SG_ NBICU10_Cell09Volt : 7|16@0+ (1,0) [0|65535] "mV"  NBCMU
 SG_ NBICU10_Cell10Volt : 23|16@0+ (1,0) [0|65535] "mV"  NBCMU
 SG_ NBICU10_Cell11Volt : 39|16@0+ (1,0) [0|65535] "mV"  NBCMU
 SG_ NBICU10_Cell12Volt : 55|16@0+ (1,0) [0|65535] "mV"  NBCMU

BO_ 2564095754 NBICU10_CellVotlage04: 8 NBICU
 SG_ NBICU10_Cell13Volt : 7|16@0+ (1,0) [0|65535] "mV"  NBCMU
 SG_ NBICU10_Cell14Volt : 23|16@0+ (1,0) [0|65535] "mV"  NBCMU
 SG_ NBICU10_Cell15Volt : 39|16@0+ (1,0) [0|65535] "mV"  NBCMU
 SG_ NBICU10_Cell16Volt : 55|16@0+ (1,0) [0|65535] "mV"  NBCMU

BO_ 2564161290 NBICU10_CellVotlage05: 8 NBICU
 SG_ NBICU10_Cell17Volt : 7|16@0+ (1,0) [0|65535] "mV"  NBCMU
 SG_ NBICU10_Cell18Volt : 23|16@0+ (1,0) [0|65535] "mV"  NBCMU
 SG_ NBICU10_Cell19Volt : 39|16@0+ (1,0) [0|65535] "mV"  NBCMU
 SG_ NBICU10_Cell20Volt : 55|16@0+ (1,0) [0|65535] "mV"  NBCMU

BO_ 2564226826 NBICU10_CellVotlage06: 8 NBICU
 SG_ NBICU10_Cell21Volt : 7|16@0+ (1,0) [0|65535] "mV"  NBCMU
 SG_ NBICU10_Cell22Volt : 23|16@0+ (1,0) [0|65535] "mV"  NBCMU
 SG_ NBICU10_Cell23Volt : 39|16@0+ (1,0) [0|65535] "mV"  NBCMU
 SG_ NBICU10_Cell24Volt : 55|16@0+ (1,0) [0|65535] "mV"  NBCMU

BO_ 2564292362 NBICU10_CellVotlage07: 8 NBICU
 SG_ NBICU10_Cell25Volt : 7|16@0+ (1,0) [0|65535] "mV"  NBCMU
 SG_ NBICU10_Cell26Volt : 23|16@0+ (1,0) [0|65535] "mV"  NBCMU
 SG_ NBICU10_Cell27Volt : 39|16@0+ (1,0) [0|65535] "mV"  NBCMU
 SG_ NBICU10_Cell28Volt : 55|16@0+ (1,0) [0|65535] "mV"  NBCMU

CM_ BO_ 2562785025 "NBICU01 Tx and Run State";
CM_ SG_ 2562785025 NBICU01_Address "Address
从机地址";
CM_ SG_ 2562785025 NBICU01_CellVNum "CellVNum
配置电压采集串数";
CM_ SG_ 2562785025 NBICU01_TempNum "TempNum
配置温度采集个数";
CM_ SG_ 2562785025 NBICU01_ErrFlag "ErrFlag
故障标志(预留)";
CM_ SG_ 2562785025 NBICU01_AddrInput_State "Addr Input_State
检测地址状态";
CM_ SG_ 2562785025 NBICU01_AddrOutput_State "Addr Output_State
输出地址状态";
CM_ SG_ 2562785025 NBICU01_HSD01Sta "HSD01
高边1控制状态(预留)";
CM_ SG_ 2562785025 NBICU01_SoftVer "SoftVer
软件版本";
CM_ SG_ 2562785025 NBICU01_HardVer "HardVer
硬件版本";
CM_ SG_ 2562785025 NBICU01_RunAlivCoun "AliveCounter
心跳指数";
CM_ BO_ 2562850561 "NBICU01 Tx and VoltExtremeInfo";
CM_ SG_ 2562850561 NBICU01_CellVoltMax "最高单体电压";
CM_ SG_ 2562850561 NBICU01_CellVoltMin "最低单体电压";
CM_ SG_ 2562850561 NBICU01_CellVoltMaxCode "最高单体电压序号";
CM_ SG_ 2562850561 NBICU01_CellVoltMinCode "最低单体电压序号";
CM_ SG_ 2562850561 NBICU01_CellSumVolt "电池包累计总压";
CM_ BO_ 2562916097 "NBICU01 Tx and TempExtremeInfo";
CM_ SG_ 2562916097 NBICU01_CellTempMax "最高温度";
CM_ SG_ 2562916097 NBICU01_CellTempMin "最低温度";
CM_ SG_ 2562916097 NBICU01_CellTempAvg "平均温度";
CM_ SG_ 2562916097 NBICU01_CellTempMaxCode "最高温度序号";
CM_ SG_ 2562916097 NBICU01_CellTempMinCode "最低温度序号";
CM_ SG_ 2562916097 NBICU01_SupplyVolt "供电电压";
CM_ SG_ 2562916097 NBICU01_PCB_Temp "板载温度";
CM_ BO_ 2562981633 "NBICU01 Tx and Balance State";
CM_ SG_ 2562981633 NBICU01_Cell0108BalaSta "Cell0108BalaSta
单体1至8通道均衡状态";
CM_ SG_ 2562981633 NBICU01_Cell0916BalaSta "Cell0916BalaSta
单体9至16通道均衡标志";
CM_ SG_ 2562981633 NBICU01_Cell1724BalaSta "Cell1724BalaSta
单体17至24通道均衡状态";
CM_ SG_ 2562981633 NBICU01_Cell2532BalaSta "Cell2532BalaSta
单体25至32通道均衡状态";
CM_ SG_ 2562981633 NBICU01_Cell3336BalaSta "Cell3336BalaSta
单体33至36通道均衡状态";
CM_ SG_ 2562981633 NBICU01_SysSOH "Sys SOH
电池包SOH";
CM_ SG_ 2562981633 NBICU01_CycleTime "CycleTime
循环次数";
CM_ BO_ 2563899137 "NBICU01 Tx and Cell Voltage01";
CM_ SG_ 2563899137 NBICU01_Cell01Volt "Cell01Volt单体01电压值";
CM_ SG_ 2563899137 NBICU01_Cell02Volt "Cell02Volt单体02电压值";
CM_ SG_ 2563899137 NBICU01_Cell03Volt "Cell03Volt单体03电压值";
CM_ SG_ 2563899137 NBICU01_Cell04Volt "Cell04Volt单体04电压值";
CM_ BO_ 2563964673 "NBICU01 Tx and Cell Voltage02";
CM_ SG_ 2563964673 NBICU01_Cell05Volt "Cell05Volt单体05电压值";
CM_ SG_ 2563964673 NBICU01_Cell06Volt "Cell06Volt单体06电压值";
CM_ SG_ 2563964673 NBICU01_Cell07Volt "Cell07Volt单体07电压值";
CM_ SG_ 2563964673 NBICU01_Cell08Volt "Cell08Volt单体08电压值";
CM_ BO_ 2564030209 "NBICU01 Tx and Cell Voltage03";
CM_ SG_ 2564030209 NBICU01_Cell09Volt "Cell09Volt单体09电压值";
CM_ SG_ 2564030209 NBICU01_Cell10Volt "Cell10Volt单体10电压值";
CM_ SG_ 2564030209 NBICU01_Cell11Volt "Cell11Volt单体11电压值";
CM_ SG_ 2564030209 NBICU01_Cell12Volt "Cell12Volt单体12电压值";
CM_ BO_ 2564095745 "NBICU01 Tx and Cell Voltage04";
CM_ SG_ 2564095745 NBICU01_Cell13Volt "Cell13Volt单体13电压值";
CM_ SG_ 2564095745 NBICU01_Cell14Volt "Cell14Volt单体14电压值";
CM_ SG_ 2564095745 NBICU01_Cell15Volt "Cell15Volt单体15电压值";
CM_ SG_ 2564095745 NBICU01_Cell16Volt "Cell16Volt单体16电压值";
CM_ BO_ 2564161281 "NBICU01 Tx and Cell Voltage05";
CM_ SG_ 2564161281 NBICU01_Cell17Volt "Cell17Volt单体17电压值";
CM_ SG_ 2564161281 NBICU01_Cell18Volt "Cell18Volt单体18电压值";
CM_ SG_ 2564161281 NBICU01_Cell19Volt "Cell19Volt单体19电压值";
CM_ SG_ 2564161281 NBICU01_Cell20Volt "Cell20Volt单体20电压值";
CM_ BO_ 2564226817 "NBICU01 Tx and Cell Voltage06";
CM_ SG_ 2564226817 NBICU01_Cell21Volt "Cell21Volt单体21电压值";
CM_ SG_ 2564226817 NBICU01_Cell22Volt "Cell22Volt单体22电压值";
CM_ SG_ 2564226817 NBICU01_Cell23Volt "Cell23Volt单体23电压值";
CM_ SG_ 2564226817 NBICU01_Cell24Volt "Cell24Volt单体24电压值";
CM_ BO_ 2564292353 "NBICU01 Tx and Cell Voltage07";
CM_ SG_ 2564292353 NBICU01_Cell25Volt "Cell25Volt单体25电压值";
CM_ SG_ 2564292353 NBICU01_Cell26Volt "Cell26Volt单体26电压值";
CM_ SG_ 2564292353 NBICU01_Cell27Volt "Cell27Volt单体27电压值";
CM_ SG_ 2564292353 NBICU01_Cell28Volt "Cell28Volt单体28电压值";
CM_ BO_ 2564357889 "NBICU01 Tx and Cell Voltage08";
CM_ SG_ 2564357889 NBICU01_Cell29Volt "Cell29Volt单体29电压值";
CM_ SG_ 2564357889 NBICU01_Cell30Volt "Cell30Volt单体30电压值";
CM_ SG_ 2564357889 NBICU01_Cell31Volt "Cell31Volt单体31电压值";
CM_ SG_ 2564357889 NBICU01_Cell32Volt "Cell32Volt单体32电压值";
CM_ BO_ 2564423425 "NBICU01 Tx and Cell Voltage09";
CM_ SG_ 2564423425 NBICU01_Cell33Volt "Cell33Volt单体33电压值";
CM_ SG_ 2564423425 NBICU01_Cell34Volt "Cell34Volt单体34电压值";
CM_ SG_ 2564423425 NBICU01_Cell35Volt "Cell35Volt单体35电压值";
CM_ SG_ 2564423425 NBICU01_Cell36Volt "Cell36Volt单体36电压值";
CM_ BO_ 2564488961 "NBICU01 Tx and Cell Temp01";
CM_ SG_ 2564488961 NBICU01_Temp01 "NTC01-温度值";
CM_ SG_ 2564488961 NBICU01_Temp02 "NTC02-温度值";
CM_ SG_ 2564488961 NBICU01_Temp03 "NTC03-温度值";
CM_ SG_ 2564488961 NBICU01_Temp04 "NTC04-温度值";
CM_ SG_ 2564488961 NBICU01_Temp05 "NTC05-温度值";
CM_ SG_ 2564488961 NBICU01_Temp06 "NTC06-温度值";
CM_ SG_ 2564488961 NBICU01_Temp07 "NTC07-温度值";
CM_ SG_ 2564488961 NBICU01_Temp08 "NTC08-温度值";
CM_ BO_ 2564554497 "NBICU01 Tx and Cell Temp02";
CM_ SG_ 2564554497 NBICU01_Temp09 "NTC09-温度值";
CM_ SG_ 2564554497 NBICU01_Temp10 "NTC10-温度值";
CM_ SG_ 2564554497 NBICU01_Temp11 "NTC11-温度值";
CM_ SG_ 2564554497 NBICU01_Temp12 "NTC12-温度值";
CM_ SG_ 2564554497 NBICU01_Temp13 "NTC13-温度值";
CM_ SG_ 2564554497 NBICU01_Temp14 "NTC14-温度值";
CM_ SG_ 2564554497 NBICU01_Temp15 "NTC15-温度值";
CM_ SG_ 2564554497 NBICU01_Temp16 "NTC16-温度值";
CM_ BO_ 2564620033 "NBICU01 Tx and Cell Temp03";
CM_ SG_ 2564620033 NBICU01_Temp17 "NTC17-温度值";
CM_ SG_ 2564620033 NBICU01_Temp18 "NTC18-温度值";
CM_ SG_ 2564620033 NBICU01_Temp19 "NTC19-温度值";
CM_ SG_ 2564620033 NBICU01_Temp20 "NTC20-温度值";
CM_ SG_ 2564620033 NBICU01_Temp21 "NTC21-温度值";
CM_ SG_ 2564620033 NBICU01_Temp22 "NTC22-温度值";
CM_ SG_ 2564620033 NBICU01_Temp23 "NTC23-温度值";
CM_ SG_ 2564620033 NBICU01_Temp24 "NTC24-温度值";
CM_ BO_ 2564685569 "NBICU01 Tx and Cell Temp04";
CM_ SG_ 2564685569 NBICU01_Temp25 "NTC25-温度值";
CM_ SG_ 2564685569 NBICU01_Temp26 "NTC26-温度值";
CM_ SG_ 2564685569 NBICU01_Temp27 "NTC27-温度值";
CM_ SG_ 2564685569 NBICU01_Temp28 "NTC28-温度值";
CM_ SG_ 2564685569 NBICU01_Temp29 "NTC29-温度值";
CM_ SG_ 2564685569 NBICU01_Temp30 "NTC30-温度值";
CM_ SG_ 2564685569 NBICU01_Temp31 "NTC31-温度值";
CM_ SG_ 2564685569 NBICU01_Temp32 "NTC32-温度值";
CM_ BO_ 2564751105 "NBICU01 Tx and Cell Temp05";
CM_ SG_ 2564751105 NBICU01_Temp33 "NTC33-温度值";
CM_ SG_ 2564751105 NBICU01_Temp34 "NTC34-温度值";
CM_ SG_ 2564751105 NBICU01_Temp35 "NTC35-温度值";
CM_ SG_ 2564751105 NBICU01_Temp36 "NTC36-温度值";
CM_ BO_ 2564947713 "NBICU01 Tx and Software";
CM_ SG_ 2564947713 NBICU01_NBCMU_Addr_SW "NBICU01 NBCMU Address
NBICU01接收NBCMU地址";
CM_ SG_ 2564947713 NBICU01_SW01 "NBICU01 Software Byte 01
NBICU01软件版本第01字节";
CM_ SG_ 2564947713 NBICU01_SW02 "NBICU01 Software Byte 02
NBICU01软件版本第02字节";
CM_ SG_ 2564947713 NBICU01_SW03 "NBICU01 Software Byte 03
NBICU01软件版本第03字节";
CM_ SG_ 2564947713 NBICU01_SW04 "NBICU01 Software Byte 04
NBICU01软件版本第04字节";
CM_ SG_ 2564947713 NBICU01_SW05 "NBICU01 Software Byte 05
NBICU01软件版本第05字节";
CM_ SG_ 2564947713 NBICU01_SW06 "NBICU01 Software Byte 06
NBICU01软件版本第06字节";
CM_ SG_ 2564947713 NBICU01_SW07 "NBICU01 Software Byte 07
NBICU01软件版本第07字节";
CM_ BO_ 2565013249 "NBICU01 Tx and Hardware";
CM_ SG_ 2565013249 NBICU01_NBCMU_Addr_HW "NBICU01 NBCMU Address
NBICU01接收NBCMU地址";
CM_ SG_ 2565013249 NBICU01_HW01 "NBICU01 Hardware Byte 01
NBICU01硬件版本第01字节";
CM_ SG_ 2565013249 NBICU01_HW02 "NBICU01 Hardware Byte 02
NBICU01硬件版本第02字节";
CM_ SG_ 2565013249 NBICU01_HW03 "NBICU01 Hardware Byte 03
NBICU01硬件版本第03字节";
CM_ SG_ 2565013249 NBICU01_HW04 "NBICU01 Hardware Byte 04
NBICU01硬件版本第04字节";
CM_ SG_ 2565013249 NBICU01_HW05 "NBICU01 Hardware Byte 05
NBICU01硬件版本第05字节";
CM_ SG_ 2565013249 NBICU01_HW06 "NBICU01 Hardware Byte 06
NBICU01硬件版本第06字节";
CM_ SG_ 2565013249 NBICU01_HW07 "NBICU01 Hardware Byte 07
NBICU01硬件版本第07字节";
CM_ BO_ 2564677377 "NBICU01 Tx and DiaResponse";
CM_ BO_ 2562785026 "NBICU02 Tx and Run State";
CM_ SG_ 2562785026 NBICU02_Address "Address
从机地址";
CM_ SG_ 2562785026 NBICU02_CellVNum "CellVNum
配置电压采集串数";
CM_ SG_ 2562785026 NBICU02_TempNum "TempNum
配置温度采集个数";
CM_ SG_ 2562785026 NBICU02_ErrFlag "ErrFlag
故障标志(预留)";
CM_ SG_ 2562785026 NBICU02_AddrInput_State "Addr Input_State
检测地址状态";
CM_ SG_ 2562785026 NBICU02_AddrOutput_State "Addr Output_State
输出地址状态";
CM_ SG_ 2562785026 NBICU02_HSD01Sta "HSD01
高边1控制状态(预留)";
CM_ SG_ 2562785026 NBICU02_SoftVer "SoftVer
软件版本";
CM_ SG_ 2562785026 NBICU02_HardVer "HardVer
硬件版本";
CM_ SG_ 2562785026 NBICU02_RunAlivCoun "AliveCounter
心跳指数";
CM_ BO_ 2562850562 "NBICU02 Tx and VoltExtremeInfo";
CM_ SG_ 2562850562 NBICU02_CellVoltMax "最高单体电压";
CM_ SG_ 2562850562 NBICU02_CellVoltMin "最低单体电压";
CM_ SG_ 2562850562 NBICU02_CellVoltMaxCode "最高单体电压序号";
CM_ SG_ 2562850562 NBICU02_CellVoltMinCode "最低单体电压序号";
CM_ SG_ 2562850562 NBICU02_CellSumVolt "电池包累计总压";
CM_ BO_ 2562916098 "NBICU02 Tx and TempExtremeInfo";
CM_ SG_ 2562916098 NBICU02_CellTempMax "最高温度";
CM_ SG_ 2562916098 NBICU02_CellTempMin "最低温度";
CM_ SG_ 2562916098 NBICU02_CellTempAvg "平均温度";
CM_ SG_ 2562916098 NBICU02_CellTempMaxCode "最高温度序号";
CM_ SG_ 2562916098 NBICU02_CellTempMinCode "最低温度序号";
CM_ SG_ 2562916098 NBICU02_SupplyVolt "供电电压";
CM_ SG_ 2562916098 NBICU02_PCB_Temp "板载温度";
CM_ BO_ 2562981634 "NBICU02 Tx and Balance State";
CM_ SG_ 2562981634 NBICU02_Cell0108BalaSta "Cell0108BalaSta
单体1至8通道均衡状态";
CM_ SG_ 2562981634 NBICU02_Cell0916BalaSta "Cell0916BalaSta
单体9至16通道均衡标志";
CM_ SG_ 2562981634 NBICU02_Cell1724BalaSta "Cell1724BalaSta
单体17至24通道均衡状态";
CM_ SG_ 2562981634 NBICU02_Cell2532BalaSta "Cell2532BalaSta
单体25至32通道均衡状态";
CM_ SG_ 2562981634 NBICU02_Cell3336BalaSta "Cell3336BalaSta
单体33至36通道均衡状态";
CM_ SG_ 2562981634 NBICU02_SysSOH "Sys SOH
电池包SOH";
CM_ SG_ 2562981634 NBICU02_CycleTime "CycleTime
循环次数";
CM_ BO_ 2563899138 "NBICU02 Tx and Cell Voltage01";
CM_ SG_ 2563899138 NBICU02_Cell01Volt "Cell01Volt单体01电压值";
CM_ SG_ 2563899138 NBICU02_Cell02Volt "Cell02Volt单体02电压值";
CM_ SG_ 2563899138 NBICU02_Cell03Volt "Cell03Volt单体03电压值";
CM_ SG_ 2563899138 NBICU02_Cell04Volt "Cell04Volt单体04电压值";
CM_ BO_ 2563964674 "NBICU02 Tx and Cell Voltage02";
CM_ SG_ 2563964674 NBICU02_Cell05Volt "Cell05Volt单体05电压值";
CM_ SG_ 2563964674 NBICU02_Cell06Volt "Cell06Volt单体06电压值";
CM_ SG_ 2563964674 NBICU02_Cell07Volt "Cell07Volt单体07电压值";
CM_ SG_ 2563964674 NBICU02_Cell08Volt "Cell08Volt单体08电压值";
CM_ BO_ 2564030210 "NBICU02 Tx and Cell Voltage03";
CM_ SG_ 2564030210 NBICU02_Cell09Volt "Cell09Volt单体09电压值";
CM_ SG_ 2564030210 NBICU02_Cell10Volt "Cell10Volt单体10电压值";
CM_ SG_ 2564030210 NBICU02_Cell11Volt "Cell11Volt单体11电压值";
CM_ SG_ 2564030210 NBICU02_Cell12Volt "Cell12Volt单体12电压值";
CM_ BO_ 2564095746 "NBICU02 Tx and Cell Voltage04";
CM_ SG_ 2564095746 NBICU02_Cell13Volt "Cell13Volt单体13电压值";
CM_ SG_ 2564095746 NBICU02_Cell14Volt "Cell14Volt单体14电压值";
CM_ SG_ 2564095746 NBICU02_Cell15Volt "Cell15Volt单体15电压值";
CM_ SG_ 2564095746 NBICU02_Cell16Volt "Cell16Volt单体16电压值";
CM_ BO_ 2564161282 "NBICU02 Tx and Cell Voltage05";
CM_ SG_ 2564161282 NBICU02_Cell17Volt "Cell17Volt单体17电压值";
CM_ SG_ 2564161282 NBICU02_Cell18Volt "Cell18Volt单体18电压值";
CM_ SG_ 2564161282 NBICU02_Cell19Volt "Cell19Volt单体19电压值";
CM_ SG_ 2564161282 NBICU02_Cell20Volt "Cell20Volt单体20电压值";
CM_ BO_ 2564226818 "NBICU02 Tx and Cell Voltage06";
CM_ SG_ 2564226818 NBICU02_Cell21Volt "Cell21Volt单体21电压值";
CM_ SG_ 2564226818 NBICU02_Cell22Volt "Cell22Volt单体22电压值";
CM_ SG_ 2564226818 NBICU02_Cell23Volt "Cell23Volt单体23电压值";
CM_ SG_ 2564226818 NBICU02_Cell24Volt "Cell24Volt单体24电压值";
CM_ BO_ 2564292354 "NBICU02 Tx and Cell Voltage07";
CM_ SG_ 2564292354 NBICU02_Cell25Volt "Cell25Volt单体25电压值";
CM_ SG_ 2564292354 NBICU02_Cell26Volt "Cell26Volt单体26电压值";
CM_ SG_ 2564292354 NBICU02_Cell27Volt "Cell27Volt单体27电压值";
CM_ SG_ 2564292354 NBICU02_Cell28Volt "Cell28Volt单体28电压值";
CM_ BO_ 2564357890 "NBICU02 Tx and Cell Voltage08";
CM_ SG_ 2564357890 NBICU02_Cell29Volt "Cell29Volt单体29电压值";
CM_ SG_ 2564357890 NBICU02_Cell30Volt "Cell30Volt单体30电压值";
CM_ SG_ 2564357890 NBICU02_Cell31Volt "Cell31Volt单体31电压值";
CM_ SG_ 2564357890 NBICU02_Cell32Volt "Cell32Volt单体32电压值";
CM_ BO_ 2564423426 "NBICU02 Tx and Cell Voltage09";
CM_ SG_ 2564423426 NBICU02_Cell33Volt "Cell33Volt单体33电压值";
CM_ SG_ 2564423426 NBICU02_Cell34Volt "Cell34Volt单体34电压值";
CM_ SG_ 2564423426 NBICU02_Cell35Volt "Cell35Volt单体35电压值";
CM_ SG_ 2564423426 NBICU02_Cell36Volt "Cell36Volt单体36电压值";
CM_ BO_ 2564488962 "NBICU02 Tx and Cell Temp01";
CM_ SG_ 2564488962 NBICU02_Temp01 "NTC01-温度值";
CM_ SG_ 2564488962 NBICU02_Temp02 "NTC02-温度值";
CM_ SG_ 2564488962 NBICU02_Temp03 "NTC03-温度值";
CM_ SG_ 2564488962 NBICU02_Temp04 "NTC04-温度值";
CM_ SG_ 2564488962 NBICU02_Temp05 "NTC05-温度值";
CM_ SG_ 2564488962 NBICU02_Temp06 "NTC06-温度值";
CM_ SG_ 2564488962 NBICU02_Temp07 "NTC07-温度值";
CM_ SG_ 2564488962 NBICU02_Temp08 "NTC08-温度值";
CM_ BO_ 2564554498 "NBICU02 Tx and Cell Temp02";
CM_ SG_ 2564554498 NBICU02_Temp09 "NTC09-温度值";
CM_ SG_ 2564554498 NBICU02_Temp10 "NTC10-温度值";
CM_ SG_ 2564554498 NBICU02_Temp11 "NTC11-温度值";
CM_ SG_ 2564554498 NBICU02_Temp12 "NTC12-温度值";
CM_ SG_ 2564554498 NBICU02_Temp13 "NTC13-温度值";
CM_ SG_ 2564554498 NBICU02_Temp14 "NTC14-温度值";
CM_ SG_ 2564554498 NBICU02_Temp15 "NTC15-温度值";
CM_ SG_ 2564554498 NBICU02_Temp16 "NTC16-温度值";
CM_ BO_ 2564620034 "NBICU02 Tx and Cell Temp03";
CM_ SG_ 2564620034 NBICU02_Temp17 "NTC17-温度值";
CM_ SG_ 2564620034 NBICU02_Temp18 "NTC18-温度值";
CM_ SG_ 2564620034 NBICU02_Temp19 "NTC19-温度值";
CM_ SG_ 2564620034 NBICU02_Temp20 "NTC20-温度值";
CM_ SG_ 2564620034 NBICU02_Temp21 "NTC21-温度值";
CM_ SG_ 2564620034 NBICU02_Temp22 "NTC22-温度值";
CM_ SG_ 2564620034 NBICU02_Temp23 "NTC23-温度值";
CM_ SG_ 2564620034 NBICU02_Temp24 "NTC24-温度值";
CM_ BO_ 2564685570 "NBICU02 Tx and Cell Temp04";
CM_ SG_ 2564685570 NBICU02_Temp25 "NTC25-温度值";
CM_ SG_ 2564685570 NBICU02_Temp26 "NTC26-温度值";
CM_ SG_ 2564685570 NBICU02_Temp27 "NTC27-温度值";
CM_ SG_ 2564685570 NBICU02_Temp28 "NTC28-温度值";
CM_ SG_ 2564685570 NBICU02_Temp29 "NTC29-温度值";
CM_ SG_ 2564685570 NBICU02_Temp30 "NTC30-温度值";
CM_ SG_ 2564685570 NBICU02_Temp31 "NTC31-温度值";
CM_ SG_ 2564685570 NBICU02_Temp32 "NTC32-温度值";
CM_ BO_ 2564751106 "NBICU02 Tx and Cell Temp05";
CM_ SG_ 2564751106 NBICU02_Temp33 "NTC33-温度值";
CM_ SG_ 2564751106 NBICU02_Temp34 "NTC34-温度值";
CM_ SG_ 2564751106 NBICU02_Temp35 "NTC35-温度值";
CM_ SG_ 2564751106 NBICU02_Temp36 "NTC36-温度值";
CM_ BO_ 2564947714 "NBICU02 Tx and Software";
CM_ SG_ 2564947714 NBICU02_NBCMU_Addr_SW "NBICU02 NBCMU Address
NBICU02接收NBCMU地址";
CM_ SG_ 2564947714 NBICU02_SW01 "NBICU02 Software Byte 01
NBICU02软件版本第01字节";
CM_ SG_ 2564947714 NBICU02_SW02 "NBICU02 Software Byte 02
NBICU02软件版本第02字节";
CM_ SG_ 2564947714 NBICU02_SW03 "NBICU02 Software Byte 03
NBICU02软件版本第03字节";
CM_ SG_ 2564947714 NBICU02_SW04 "NBICU02 Software Byte 04
NBICU02软件版本第04字节";
CM_ SG_ 2564947714 NBICU02_SW05 "NBICU02 Software Byte 05
NBICU02软件版本第05字节";
CM_ SG_ 2564947714 NBICU02_SW06 "NBICU02 Software Byte 06
NBICU02软件版本第06字节";
CM_ SG_ 2564947714 NBICU02_SW07 "NBICU02 Software Byte 07
NBICU02软件版本第07字节";
CM_ BO_ 2565013250 "NBICU02 Tx and Hardware";
CM_ SG_ 2565013250 NBICU02_NBCMU_Addr_HW "NBICU02 NBCMU Address
NBICU02接收NBCMU地址";
CM_ SG_ 2565013250 NBICU02_HW01 "NBICU02 Hardware Byte 01
NBICU02硬件版本第01字节";
CM_ SG_ 2565013250 NBICU02_HW02 "NBICU02 Hardware Byte 02
NBICU02硬件版本第02字节";
CM_ SG_ 2565013250 NBICU02_HW03 "NBICU02 Hardware Byte 03
NBICU02硬件版本第03字节";
CM_ SG_ 2565013250 NBICU02_HW04 "NBICU02 Hardware Byte 04
NBICU02硬件版本第04字节";
CM_ SG_ 2565013250 NBICU02_HW05 "NBICU02 Hardware Byte 05
NBICU02硬件版本第05字节";
CM_ SG_ 2565013250 NBICU02_HW06 "NBICU02 Hardware Byte 06
NBICU02硬件版本第06字节";
CM_ SG_ 2565013250 NBICU02_HW07 "NBICU02 Hardware Byte 07
NBICU02硬件版本第07字节";
CM_ BO_ 2564677378 "NBICU02 Tx and DiaResponse";
CM_ BO_ 2562785027 "NBICU03 Tx and Run State";
CM_ SG_ 2562785027 NBICU03_Address "Address
从机地址";
CM_ SG_ 2562785027 NBICU03_CellVNum "CellVNum
配置电压采集串数";
CM_ SG_ 2562785027 NBICU03_TempNum "TempNum
配置温度采集个数";
CM_ SG_ 2562785027 NBICU03_ErrFlag "ErrFlag
故障标志(预留)";
CM_ SG_ 2562785027 NBICU03_AddrInput_State "Addr Input_State
检测地址状态";
CM_ SG_ 2562785027 NBICU03_AddrOutput_State "Addr Output_State
输出地址状态";
CM_ SG_ 2562785027 NBICU03_HSD01Sta "HSD01
高边1控制状态(预留)";
CM_ SG_ 2562785027 NBICU03_SoftVer "SoftVer
软件版本";
CM_ SG_ 2562785027 NBICU03_HardVer "HardVer
硬件版本";
CM_ SG_ 2562785027 NBICU03_RunAlivCoun "AliveCounter
心跳指数";
CM_ BO_ 2562850563 "NBICU03 Tx and VoltExtremeInfo";
CM_ SG_ 2562850563 NBICU03_CellVoltMax "最高单体电压";
CM_ SG_ 2562850563 NBICU03_CellVoltMin "最低单体电压";
CM_ SG_ 2562850563 NBICU03_CellVoltMaxCode "最高单体电压序号";
CM_ SG_ 2562850563 NBICU03_CellVoltMinCode "最低单体电压序号";
CM_ SG_ 2562850563 NBICU03_CellSumVolt "电池包累计总压";
CM_ BO_ 2562916099 "NBICU03 Tx and TempExtremeInfo";
CM_ SG_ 2562916099 NBICU03_CellTempMax "最高温度";
CM_ SG_ 2562916099 NBICU03_CellTempMin "最低温度";
CM_ SG_ 2562916099 NBICU03_CellTempAvg "平均温度";
CM_ SG_ 2562916099 NBICU03_CellTempMaxCode "最高温度序号";
CM_ SG_ 2562916099 NBICU03_CellTempMinCode "最低温度序号";
CM_ SG_ 2562916099 NBICU03_SupplyVolt "供电电压";
CM_ SG_ 2562916099 NBICU03_PCB_Temp "板载温度";
CM_ BO_ 2562981635 "NBICU03 Tx and Balance State";
CM_ SG_ 2562981635 NBICU03_Cell0108BalaSta "Cell0108BalaSta
单体1至8通道均衡状态";
CM_ SG_ 2562981635 NBICU03_Cell0916BalaSta "Cell0916BalaSta
单体9至16通道均衡标志";
CM_ SG_ 2562981635 NBICU03_Cell1724BalaSta "Cell1724BalaSta
单体17至24通道均衡状态";
CM_ SG_ 2562981635 NBICU03_Cell2532BalaSta "Cell2532BalaSta
单体25至32通道均衡状态";
CM_ SG_ 2562981635 NBICU03_Cell3336BalaSta "Cell3336BalaSta
单体33至36通道均衡状态";
CM_ SG_ 2562981635 NBICU03_SysSOH "Sys SOH
电池包SOH";
CM_ SG_ 2562981635 NBICU03_CycleTime "CycleTime
循环次数";
CM_ BO_ 2563899139 "NBICU03 Tx and Cell Voltage01";
CM_ SG_ 2563899139 NBICU03_Cell01Volt "Cell01Volt单体01电压值";
CM_ SG_ 2563899139 NBICU03_Cell02Volt "Cell02Volt单体02电压值";
CM_ SG_ 2563899139 NBICU03_Cell03Volt "Cell03Volt单体03电压值";
CM_ SG_ 2563899139 NBICU03_Cell04Volt "Cell04Volt单体04电压值";
CM_ BO_ 2563964675 "NBICU03 Tx and Cell Voltage02";
CM_ SG_ 2563964675 NBICU03_Cell05Volt "Cell05Volt单体05电压值";
CM_ SG_ 2563964675 NBICU03_Cell06Volt "Cell06Volt单体06电压值";
CM_ SG_ 2563964675 NBICU03_Cell07Volt "Cell07Volt单体07电压值";
CM_ SG_ 2563964675 NBICU03_Cell08Volt "Cell08Volt单体08电压值";
CM_ BO_ 2564030211 "NBICU03 Tx and Cell Voltage03";
CM_ SG_ 2564030211 NBICU03_Cell09Volt "Cell09Volt单体09电压值";
CM_ SG_ 2564030211 NBICU03_Cell10Volt "Cell10Volt单体10电压值";
CM_ SG_ 2564030211 NBICU03_Cell11Volt "Cell11Volt单体11电压值";
CM_ SG_ 2564030211 NBICU03_Cell12Volt "Cell12Volt单体12电压值";
CM_ BO_ 2564095747 "NBICU03 Tx and Cell Voltage04";
CM_ SG_ 2564095747 NBICU03_Cell13Volt "Cell13Volt单体13电压值";
CM_ SG_ 2564095747 NBICU03_Cell14Volt "Cell14Volt单体14电压值";
CM_ SG_ 2564095747 NBICU03_Cell15Volt "Cell15Volt单体15电压值";
CM_ SG_ 2564095747 NBICU03_Cell16Volt "Cell16Volt单体16电压值";
CM_ BO_ 2564161283 "NBICU03 Tx and Cell Voltage05";
CM_ SG_ 2564161283 NBICU03_Cell17Volt "Cell17Volt单体17电压值";
CM_ SG_ 2564161283 NBICU03_Cell18Volt "Cell18Volt单体18电压值";
CM_ SG_ 2564161283 NBICU03_Cell19Volt "Cell19Volt单体19电压值";
CM_ SG_ 2564161283 NBICU03_Cell20Volt "Cell20Volt单体20电压值";
CM_ BO_ 2564226819 "NBICU03 Tx and Cell Voltage06";
CM_ SG_ 2564226819 NBICU03_Cell21Volt "Cell21Volt单体21电压值";
CM_ SG_ 2564226819 NBICU03_Cell22Volt "Cell22Volt单体22电压值";
CM_ SG_ 2564226819 NBICU03_Cell23Volt "Cell23Volt单体23电压值";
CM_ SG_ 2564226819 NBICU03_Cell24Volt "Cell24Volt单体24电压值";
CM_ BO_ 2564292355 "NBICU03 Tx and Cell Voltage07";
CM_ SG_ 2564292355 NBICU03_Cell25Volt "Cell25Volt单体25电压值";
CM_ SG_ 2564292355 NBICU03_Cell26Volt "Cell26Volt单体26电压值";
CM_ SG_ 2564292355 NBICU03_Cell27Volt "Cell27Volt单体27电压值";
CM_ SG_ 2564292355 NBICU03_Cell28Volt "Cell28Volt单体28电压值";
CM_ BO_ 2564357891 "NBICU03 Tx and Cell Voltage08";
CM_ SG_ 2564357891 NBICU03_Cell29Volt "Cell29Volt单体29电压值";
CM_ SG_ 2564357891 NBICU03_Cell30Volt "Cell30Volt单体30电压值";
CM_ SG_ 2564357891 NBICU03_Cell31Volt "Cell31Volt单体31电压值";
CM_ SG_ 2564357891 NBICU03_Cell32Volt "Cell32Volt单体32电压值";
CM_ BO_ 2564423427 "NBICU03 Tx and Cell Voltage09";
CM_ SG_ 2564423427 NBICU03_Cell33Volt "Cell33Volt单体33电压值";
CM_ SG_ 2564423427 NBICU03_Cell34Volt "Cell34Volt单体34电压值";
CM_ SG_ 2564423427 NBICU03_Cell35Volt "Cell35Volt单体35电压值";
CM_ SG_ 2564423427 NBICU03_Cell36Volt "Cell36Volt单体36电压值";
CM_ BO_ 2564488963 "NBICU03 Tx and Cell Temp01";
CM_ SG_ 2564488963 NBICU03_Temp01 "NTC01-温度值";
CM_ SG_ 2564488963 NBICU03_Temp02 "NTC02-温度值";
CM_ SG_ 2564488963 NBICU03_Temp03 "NTC03-温度值";
CM_ SG_ 2564488963 NBICU03_Temp04 "NTC04-温度值";
CM_ SG_ 2564488963 NBICU03_Temp05 "NTC05-温度值";
CM_ SG_ 2564488963 NBICU03_Temp06 "NTC06-温度值";
CM_ SG_ 2564488963 NBICU03_Temp07 "NTC07-温度值";
CM_ SG_ 2564488963 NBICU03_Temp08 "NTC08-温度值";
CM_ BO_ 2564554499 "NBICU03 Tx and Cell Temp02";
CM_ SG_ 2564554499 NBICU03_Temp09 "NTC09-温度值";
CM_ SG_ 2564554499 NBICU03_Temp10 "NTC10-温度值";
CM_ SG_ 2564554499 NBICU03_Temp11 "NTC11-温度值";
CM_ SG_ 2564554499 NBICU03_Temp12 "NTC12-温度值";
CM_ SG_ 2564554499 NBICU03_Temp13 "NTC13-温度值";
CM_ SG_ 2564554499 NBICU03_Temp14 "NTC14-温度值";
CM_ SG_ 2564554499 NBICU03_Temp15 "NTC15-温度值";
CM_ SG_ 2564554499 NBICU03_Temp16 "NTC16-温度值";
CM_ BO_ 2564620035 "NBICU03 Tx and Cell Temp03";
CM_ SG_ 2564620035 NBICU03_Temp17 "NTC17-温度值";
CM_ SG_ 2564620035 NBICU03_Temp18 "NTC18-温度值";
CM_ SG_ 2564620035 NBICU03_Temp19 "NTC19-温度值";
CM_ SG_ 2564620035 NBICU03_Temp20 "NTC20-温度值";
CM_ SG_ 2564620035 NBICU03_Temp21 "NTC21-温度值";
CM_ SG_ 2564620035 NBICU03_Temp22 "NTC22-温度值";
CM_ SG_ 2564620035 NBICU03_Temp23 "NTC23-温度值";
CM_ SG_ 2564620035 NBICU03_Temp24 "NTC24-温度值";
CM_ BO_ 2564685571 "NBICU03 Tx and Cell Temp04";
CM_ SG_ 2564685571 NBICU03_Temp25 "NTC25-温度值";
CM_ SG_ 2564685571 NBICU03_Temp26 "NTC26-温度值";
CM_ SG_ 2564685571 NBICU03_Temp27 "NTC27-温度值";
CM_ SG_ 2564685571 NBICU03_Temp28 "NTC28-温度值";
CM_ SG_ 2564685571 NBICU03_Temp29 "NTC29-温度值";
CM_ SG_ 2564685571 NBICU03_Temp30 "NTC30-温度值";
CM_ SG_ 2564685571 NBICU03_Temp31 "NTC31-温度值";
CM_ SG_ 2564685571 NBICU03_Temp32 "NTC32-温度值";
CM_ BO_ 2564751107 "NBICU03 Tx and Cell Temp05";
CM_ SG_ 2564751107 NBICU03_Temp33 "NTC33-温度值";
CM_ SG_ 2564751107 NBICU03_Temp34 "NTC34-温度值";
CM_ SG_ 2564751107 NBICU03_Temp35 "NTC35-温度值";
CM_ SG_ 2564751107 NBICU03_Temp36 "NTC36-温度值";
CM_ BO_ 2564947715 "NBICU03 Tx and Software";
CM_ SG_ 2564947715 NBICU03_NBCMU_Addr_SW "NBICU03 NBCMU Address
NBICU03接收NBCMU地址";
CM_ SG_ 2564947715 NBICU03_SW01 "NBICU03 Software Byte 01
NBICU03软件版本第01字节";
CM_ SG_ 2564947715 NBICU03_SW02 "NBICU03 Software Byte 02
NBICU03软件版本第02字节";
CM_ SG_ 2564947715 NBICU03_SW03 "NBICU03 Software Byte 03
NBICU03软件版本第03字节";
CM_ SG_ 2564947715 NBICU03_SW04 "NBICU03 Software Byte 04
NBICU03软件版本第04字节";
CM_ SG_ 2564947715 NBICU03_SW05 "NBICU03 Software Byte 05
NBICU03软件版本第05字节";
CM_ SG_ 2564947715 NBICU03_SW06 "NBICU03 Software Byte 06
NBICU03软件版本第06字节";
CM_ SG_ 2564947715 NBICU03_SW07 "NBICU03 Software Byte 07
NBICU03软件版本第07字节";
CM_ BO_ 2565013251 "NBICU03 Tx and Hardware";
CM_ SG_ 2565013251 NBICU03_NBCMU_Addr_HW "NBICU03 NBCMU Address
NBICU03接收NBCMU地址";
CM_ SG_ 2565013251 NBICU03_HW01 "NBICU03 Hardware Byte 01
NBICU03硬件版本第01字节";
CM_ SG_ 2565013251 NBICU03_HW02 "NBICU03 Hardware Byte 02
NBICU03硬件版本第02字节";
CM_ SG_ 2565013251 NBICU03_HW03 "NBICU03 Hardware Byte 03
NBICU03硬件版本第03字节";
CM_ SG_ 2565013251 NBICU03_HW04 "NBICU03 Hardware Byte 04
NBICU03硬件版本第04字节";
CM_ SG_ 2565013251 NBICU03_HW05 "NBICU03 Hardware Byte 05
NBICU03硬件版本第05字节";
CM_ SG_ 2565013251 NBICU03_HW06 "NBICU03 Hardware Byte 06
NBICU03硬件版本第06字节";
CM_ SG_ 2565013251 NBICU03_HW07 "NBICU03 Hardware Byte 07
NBICU03硬件版本第07字节";
CM_ BO_ 2564677379 "NBICU03 Tx and DiaResponse";
CM_ BO_ 2562785028 "NBICU04 Tx and Run State";
CM_ SG_ 2562785028 NBICU04_Address "Address
从机地址";
CM_ SG_ 2562785028 NBICU04_CellVNum "CellVNum
配置电压采集串数";
CM_ SG_ 2562785028 NBICU04_TempNum "TempNum
配置温度采集个数";
CM_ SG_ 2562785028 NBICU04_ErrFlag "ErrFlag
故障标志(预留)";
CM_ SG_ 2562785028 NBICU04_AddrInput_State "Addr Input_State
检测地址状态";
CM_ SG_ 2562785028 NBICU04_AddrOutput_State "Addr Output_State
输出地址状态";
CM_ SG_ 2562785028 NBICU04_HSD01Sta "HSD01
高边1控制状态(预留)";
CM_ SG_ 2562785028 NBICU04_SoftVer "SoftVer
软件版本";
CM_ SG_ 2562785028 NBICU04_HardVer "HardVer
硬件版本";
CM_ SG_ 2562785028 NBICU04_RunAlivCoun "AliveCounter
心跳指数";
CM_ BO_ 2562850564 "NBICU04 Tx and VoltExtremeInfo";
CM_ SG_ 2562850564 NBICU04_CellVoltMax "最高单体电压";
CM_ SG_ 2562850564 NBICU04_CellVoltMin "最低单体电压";
CM_ SG_ 2562850564 NBICU04_CellVoltMaxCode "最高单体电压序号";
CM_ SG_ 2562850564 NBICU04_CellVoltMinCode "最低单体电压序号";
CM_ SG_ 2562850564 NBICU04_CellSumVolt "电池包累计总压";
CM_ BO_ 2562916100 "NBICU04 Tx and TempExtremeInfo";
CM_ SG_ 2562916100 NBICU04_CellTempMax "最高温度";
CM_ SG_ 2562916100 NBICU04_CellTempMin "最低温度";
CM_ SG_ 2562916100 NBICU04_CellTempAvg "平均温度";
CM_ SG_ 2562916100 NBICU04_CellTempMaxCode "最高温度序号";
CM_ SG_ 2562916100 NBICU04_CellTempMinCode "最低温度序号";
CM_ SG_ 2562916100 NBICU04_SupplyVolt "供电电压";
CM_ SG_ 2562916100 NBICU04_PCB_Temp "板载温度";
CM_ BO_ 2562981636 "NBICU04 Tx and Balance State";
CM_ SG_ 2562981636 NBICU04_Cell0108BalaSta "Cell0108BalaSta
单体1至8通道均衡状态";
CM_ SG_ 2562981636 NBICU04_Cell0916BalaSta "Cell0916BalaSta
单体9至16通道均衡标志";
CM_ SG_ 2562981636 NBICU04_Cell1724BalaSta "Cell1724BalaSta
单体17至24通道均衡状态";
CM_ SG_ 2562981636 NBICU04_Cell2532BalaSta "Cell2532BalaSta
单体25至32通道均衡状态";
CM_ SG_ 2562981636 NBICU04_Cell3336BalaSta "Cell3336BalaSta
单体33至36通道均衡状态";
CM_ SG_ 2562981636 NBICU04_SysSOH "Sys SOH
电池包SOH";
CM_ SG_ 2562981636 NBICU04_CycleTime "CycleTime
循环次数";
CM_ BO_ 2563899140 "NBICU04 Tx and Cell Voltage01";
CM_ SG_ 2563899140 NBICU04_Cell01Volt "Cell01Volt单体01电压值";
CM_ SG_ 2563899140 NBICU04_Cell02Volt "Cell02Volt单体02电压值";
CM_ SG_ 2563899140 NBICU04_Cell03Volt "Cell03Volt单体03电压值";
CM_ SG_ 2563899140 NBICU04_Cell04Volt "Cell04Volt单体04电压值";
CM_ BO_ 2563964676 "NBICU04 Tx and Cell Voltage02";
CM_ SG_ 2563964676 NBICU04_Cell05Volt "Cell05Volt单体05电压值";
CM_ SG_ 2563964676 NBICU04_Cell06Volt "Cell06Volt单体06电压值";
CM_ SG_ 2563964676 NBICU04_Cell07Volt "Cell07Volt单体07电压值";
CM_ SG_ 2563964676 NBICU04_Cell08Volt "Cell08Volt单体08电压值";
CM_ BO_ 2564030212 "NBICU04 Tx and Cell Voltage03";
CM_ SG_ 2564030212 NBICU04_Cell09Volt "Cell09Volt单体09电压值";
CM_ SG_ 2564030212 NBICU04_Cell10Volt "Cell10Volt单体10电压值";
CM_ SG_ 2564030212 NBICU04_Cell11Volt "Cell11Volt单体11电压值";
CM_ SG_ 2564030212 NBICU04_Cell12Volt "Cell12Volt单体12电压值";
CM_ BO_ 2564095748 "NBICU04 Tx and Cell Voltage04";
CM_ SG_ 2564095748 NBICU04_Cell13Volt "Cell13Volt单体13电压值";
CM_ SG_ 2564095748 NBICU04_Cell14Volt "Cell14Volt单体14电压值";
CM_ SG_ 2564095748 NBICU04_Cell15Volt "Cell15Volt单体15电压值";
CM_ SG_ 2564095748 NBICU04_Cell16Volt "Cell16Volt单体16电压值";
CM_ BO_ 2564161284 "NBICU04 Tx and Cell Voltage05";
CM_ SG_ 2564161284 NBICU04_Cell17Volt "Cell17Volt单体17电压值";
CM_ SG_ 2564161284 NBICU04_Cell18Volt "Cell18Volt单体18电压值";
CM_ SG_ 2564161284 NBICU04_Cell19Volt "Cell19Volt单体19电压值";
CM_ SG_ 2564161284 NBICU04_Cell20Volt "Cell20Volt单体20电压值";
CM_ BO_ 2564226820 "NBICU04 Tx and Cell Voltage06";
CM_ SG_ 2564226820 NBICU04_Cell21Volt "Cell21Volt单体21电压值";
CM_ SG_ 2564226820 NBICU04_Cell22Volt "Cell22Volt单体22电压值";
CM_ SG_ 2564226820 NBICU04_Cell23Volt "Cell23Volt单体23电压值";
CM_ SG_ 2564226820 NBICU04_Cell24Volt "Cell24Volt单体24电压值";
CM_ BO_ 2564292356 "NBICU04 Tx and Cell Voltage07";
CM_ SG_ 2564292356 NBICU04_Cell25Volt "Cell25Volt单体25电压值";
CM_ SG_ 2564292356 NBICU04_Cell26Volt "Cell26Volt单体26电压值";
CM_ SG_ 2564292356 NBICU04_Cell27Volt "Cell27Volt单体27电压值";
CM_ SG_ 2564292356 NBICU04_Cell28Volt "Cell28Volt单体28电压值";
CM_ BO_ 2564357892 "NBICU04 Tx and Cell Voltage08";
CM_ SG_ 2564357892 NBICU04_Cell29Volt "Cell29Volt单体29电压值";
CM_ SG_ 2564357892 NBICU04_Cell30Volt "Cell30Volt单体30电压值";
CM_ SG_ 2564357892 NBICU04_Cell31Volt "Cell31Volt单体31电压值";
CM_ SG_ 2564357892 NBICU04_Cell32Volt "Cell32Volt单体32电压值";
CM_ BO_ 2564423428 "NBICU04 Tx and Cell Voltage09";
CM_ SG_ 2564423428 NBICU04_Cell33Volt "Cell33Volt单体33电压值";
CM_ SG_ 2564423428 NBICU04_Cell34Volt "Cell34Volt单体34电压值";
CM_ SG_ 2564423428 NBICU04_Cell35Volt "Cell35Volt单体35电压值";
CM_ SG_ 2564423428 NBICU04_Cell36Volt "Cell36Volt单体36电压值";
CM_ BO_ 2564488964 "NBICU04 Tx and Cell Temp01";
CM_ SG_ 2564488964 NBICU04_Temp01 "NTC01-温度值";
CM_ SG_ 2564488964 NBICU04_Temp02 "NTC02-温度值";
CM_ SG_ 2564488964 NBICU04_Temp03 "NTC03-温度值";
CM_ SG_ 2564488964 NBICU04_Temp04 "NTC04-温度值";
CM_ SG_ 2564488964 NBICU04_Temp05 "NTC05-温度值";
CM_ SG_ 2564488964 NBICU04_Temp06 "NTC06-温度值";
CM_ SG_ 2564488964 NBICU04_Temp07 "NTC07-温度值";
CM_ SG_ 2564488964 NBICU04_Temp08 "NTC08-温度值";
CM_ BO_ 2564554500 "NBICU04 Tx and Cell Temp02";
CM_ SG_ 2564554500 NBICU04_Temp09 "NTC09-温度值";
CM_ SG_ 2564554500 NBICU04_Temp10 "NTC10-温度值";
CM_ SG_ 2564554500 NBICU04_Temp11 "NTC11-温度值";
CM_ SG_ 2564554500 NBICU04_Temp12 "NTC12-温度值";
CM_ SG_ 2564554500 NBICU04_Temp13 "NTC13-温度值";
CM_ SG_ 2564554500 NBICU04_Temp14 "NTC14-温度值";
CM_ SG_ 2564554500 NBICU04_Temp15 "NTC15-温度值";
CM_ SG_ 2564554500 NBICU04_Temp16 "NTC16-温度值";
CM_ BO_ 2564620036 "NBICU04 Tx and Cell Temp03";
CM_ SG_ 2564620036 NBICU04_Temp17 "NTC17-温度值";
CM_ SG_ 2564620036 NBICU04_Temp18 "NTC18-温度值";
CM_ SG_ 2564620036 NBICU04_Temp19 "NTC19-温度值";
CM_ SG_ 2564620036 NBICU04_Temp20 "NTC20-温度值";
CM_ SG_ 2564620036 NBICU04_Temp21 "NTC21-温度值";
CM_ SG_ 2564620036 NBICU04_Temp22 "NTC22-温度值";
CM_ SG_ 2564620036 NBICU04_Temp23 "NTC23-温度值";
CM_ SG_ 2564620036 NBICU04_Temp24 "NTC24-温度值";
CM_ BO_ 2564685572 "NBICU04 Tx and Cell Temp04";
CM_ SG_ 2564685572 NBICU04_Temp25 "NTC25-温度值";
CM_ SG_ 2564685572 NBICU04_Temp26 "NTC26-温度值";
CM_ SG_ 2564685572 NBICU04_Temp27 "NTC27-温度值";
CM_ SG_ 2564685572 NBICU04_Temp28 "NTC28-温度值";
CM_ SG_ 2564685572 NBICU04_Temp29 "NTC29-温度值";
CM_ SG_ 2564685572 NBICU04_Temp30 "NTC30-温度值";
CM_ SG_ 2564685572 NBICU04_Temp31 "NTC31-温度值";
CM_ SG_ 2564685572 NBICU04_Temp32 "NTC32-温度值";
CM_ BO_ 2564751108 "NBICU04 Tx and Cell Temp05";
CM_ SG_ 2564751108 NBICU04_Temp33 "NTC33-温度值";
CM_ SG_ 2564751108 NBICU04_Temp34 "NTC34-温度值";
CM_ SG_ 2564751108 NBICU04_Temp35 "NTC35-温度值";
CM_ SG_ 2564751108 NBICU04_Temp36 "NTC36-温度值";
CM_ BO_ 2564947716 "NBICU04 Tx and Software";
CM_ SG_ 2564947716 NBICU04_NBCMU_Addr_SW "NBICU04 NBCMU Address
NBICU04接收NBCMU地址";
CM_ SG_ 2564947716 NBICU04_SW01 "NBICU04 Software Byte 01
NBICU04软件版本第01字节";
CM_ SG_ 2564947716 NBICU04_SW02 "NBICU04 Software Byte 02
NBICU04软件版本第02字节";
CM_ SG_ 2564947716 NBICU04_SW03 "NBICU04 Software Byte 03
NBICU04软件版本第03字节";
CM_ SG_ 2564947716 NBICU04_SW04 "NBICU04 Software Byte 04
NBICU04软件版本第04字节";
CM_ SG_ 2564947716 NBICU04_SW05 "NBICU04 Software Byte 05
NBICU04软件版本第05字节";
CM_ SG_ 2564947716 NBICU04_SW06 "NBICU04 Software Byte 06
NBICU04软件版本第06字节";
CM_ SG_ 2564947716 NBICU04_SW07 "NBICU04 Software Byte 07
NBICU04软件版本第07字节";
CM_ BO_ 2565013252 "NBICU04 Tx and Hardware";
CM_ SG_ 2565013252 NBICU04_NBCMU_Addr_HW "NBICU04 NBCMU Address
NBICU04接收NBCMU地址";
CM_ SG_ 2565013252 NBICU04_HW01 "NBICU04 Hardware Byte 01
NBICU04硬件版本第01字节";
CM_ SG_ 2565013252 NBICU04_HW02 "NBICU04 Hardware Byte 02
NBICU04硬件版本第02字节";
CM_ SG_ 2565013252 NBICU04_HW03 "NBICU04 Hardware Byte 03
NBICU04硬件版本第03字节";
CM_ SG_ 2565013252 NBICU04_HW04 "NBICU04 Hardware Byte 04
NBICU04硬件版本第04字节";
CM_ SG_ 2565013252 NBICU04_HW05 "NBICU04 Hardware Byte 05
NBICU04硬件版本第05字节";
CM_ SG_ 2565013252 NBICU04_HW06 "NBICU04 Hardware Byte 06
NBICU04硬件版本第06字节";
CM_ SG_ 2565013252 NBICU04_HW07 "NBICU04 Hardware Byte 07
NBICU04硬件版本第07字节";
CM_ BO_ 2564677380 "NBICU04 Tx and DiaResponse";
CM_ BO_ 2562785029 "NBICU05 Tx and Run State";
CM_ SG_ 2562785029 NBICU05_Address "Address
从机地址";
CM_ SG_ 2562785029 NBICU05_CellVNum "CellVNum
配置电压采集串数";
CM_ SG_ 2562785029 NBICU05_TempNum "TempNum
配置温度采集个数";
CM_ SG_ 2562785029 NBICU05_ErrFlag "ErrFlag
故障标志(预留)";
CM_ SG_ 2562785029 NBICU05_AddrInput_State "Addr Input_State
检测地址状态";
CM_ SG_ 2562785029 NBICU05_AddrOutput_State "Addr Output_State
输出地址状态";
CM_ SG_ 2562785029 NBICU05_HSD01Sta "HSD01
高边1控制状态(预留)";
CM_ SG_ 2562785029 NBICU05_SoftVer "SoftVer
软件版本";
CM_ SG_ 2562785029 NBICU05_HardVer "HardVer
硬件版本";
CM_ SG_ 2562785029 NBICU05_RunAlivCoun "AliveCounter
心跳指数";
CM_ BO_ 2562850565 "NBICU05 Tx and VoltExtremeInfo";
CM_ SG_ 2562850565 NBICU05_CellVoltMax "最高单体电压";
CM_ SG_ 2562850565 NBICU05_CellVoltMin "最低单体电压";
CM_ SG_ 2562850565 NBICU05_CellVoltMaxCode "最高单体电压序号";
CM_ SG_ 2562850565 NBICU05_CellVoltMinCode "最低单体电压序号";
CM_ SG_ 2562850565 NBICU05_CellSumVolt "电池包累计总压";
CM_ BO_ 2562916101 "NBICU05 Tx and TempExtremeInfo";
CM_ SG_ 2562916101 NBICU05_CellTempMax "最高温度";
CM_ SG_ 2562916101 NBICU05_CellTempMin "最低温度";
CM_ SG_ 2562916101 NBICU05_CellTempAvg "平均温度";
CM_ SG_ 2562916101 NBICU05_CellTempMaxCode "最高温度序号";
CM_ SG_ 2562916101 NBICU05_CellTempMinCode "最低温度序号";
CM_ SG_ 2562916101 NBICU05_SupplyVolt "供电电压";
CM_ SG_ 2562916101 NBICU05_PCB_Temp "板载温度";
CM_ BO_ 2562981637 "NBICU05 Tx and Balance State";
CM_ SG_ 2562981637 NBICU05_Cell0108BalaSta "Cell0108BalaSta
单体1至8通道均衡状态";
CM_ SG_ 2562981637 NBICU05_Cell0916BalaSta "Cell0916BalaSta
单体9至16通道均衡标志";
CM_ SG_ 2562981637 NBICU05_Cell1724BalaSta "Cell1724BalaSta
单体17至24通道均衡状态";
CM_ SG_ 2562981637 NBICU05_Cell2532BalaSta "Cell2532BalaSta
单体25至32通道均衡状态";
CM_ SG_ 2562981637 NBICU05_Cell3336BalaSta "Cell3336BalaSta
单体33至36通道均衡状态";
CM_ SG_ 2562981637 NBICU05_SysSOH "Sys SOH
电池包SOH";
CM_ SG_ 2562981637 NBICU05_CycleTime "CycleTime
循环次数";
CM_ BO_ 2563899141 "NBICU05 Tx and Cell Voltage01";
CM_ SG_ 2563899141 NBICU05_Cell01Volt "Cell01Volt单体01电压值";
CM_ SG_ 2563899141 NBICU05_Cell02Volt "Cell02Volt单体02电压值";
CM_ SG_ 2563899141 NBICU05_Cell03Volt "Cell03Volt单体03电压值";
CM_ SG_ 2563899141 NBICU05_Cell04Volt "Cell04Volt单体04电压值";
CM_ BO_ 2563964677 "NBICU05 Tx and Cell Voltage02";
CM_ SG_ 2563964677 NBICU05_Cell05Volt "Cell05Volt单体05电压值";
CM_ SG_ 2563964677 NBICU05_Cell06Volt "Cell06Volt单体06电压值";
CM_ SG_ 2563964677 NBICU05_Cell07Volt "Cell07Volt单体07电压值";
CM_ SG_ 2563964677 NBICU05_Cell08Volt "Cell08Volt单体08电压值";
CM_ BO_ 2564030213 "NBICU05 Tx and Cell Voltage03";
CM_ SG_ 2564030213 NBICU05_Cell09Volt "Cell09Volt单体09电压值";
CM_ SG_ 2564030213 NBICU05_Cell10Volt "Cell10Volt单体10电压值";
CM_ SG_ 2564030213 NBICU05_Cell11Volt "Cell11Volt单体11电压值";
CM_ SG_ 2564030213 NBICU05_Cell12Volt "Cell12Volt单体12电压值";
CM_ BO_ 2564095749 "NBICU05 Tx and Cell Voltage04";
CM_ SG_ 2564095749 NBICU05_Cell13Volt "Cell13Volt单体13电压值";
CM_ SG_ 2564095749 NBICU05_Cell14Volt "Cell14Volt单体14电压值";
CM_ SG_ 2564095749 NBICU05_Cell15Volt "Cell15Volt单体15电压值";
CM_ SG_ 2564095749 NBICU05_Cell16Volt "Cell16Volt单体16电压值";
CM_ BO_ 2564161285 "NBICU05 Tx and Cell Voltage05";
CM_ SG_ 2564161285 NBICU05_Cell17Volt "Cell17Volt单体17电压值";
CM_ SG_ 2564161285 NBICU05_Cell18Volt "Cell18Volt单体18电压值";
CM_ SG_ 2564161285 NBICU05_Cell19Volt "Cell19Volt单体19电压值";
CM_ SG_ 2564161285 NBICU05_Cell20Volt "Cell20Volt单体20电压值";
CM_ BO_ 2564226821 "NBICU05 Tx and Cell Voltage06";
CM_ SG_ 2564226821 NBICU05_Cell21Volt "Cell21Volt单体21电压值";
CM_ SG_ 2564226821 NBICU05_Cell22Volt "Cell22Volt单体22电压值";
CM_ SG_ 2564226821 NBICU05_Cell23Volt "Cell23Volt单体23电压值";
CM_ SG_ 2564226821 NBICU05_Cell24Volt "Cell24Volt单体24电压值";
CM_ BO_ 2564292357 "NBICU05 Tx and Cell Voltage07";
CM_ SG_ 2564292357 NBICU05_Cell25Volt "Cell25Volt单体25电压值";
CM_ SG_ 2564292357 NBICU05_Cell26Volt "Cell26Volt单体26电压值";
CM_ SG_ 2564292357 NBICU05_Cell27Volt "Cell27Volt单体27电压值";
CM_ SG_ 2564292357 NBICU05_Cell28Volt "Cell28Volt单体28电压值";
CM_ BO_ 2564357893 "NBICU05 Tx and Cell Voltage08";
CM_ SG_ 2564357893 NBICU05_Cell29Volt "Cell29Volt单体29电压值";
CM_ SG_ 2564357893 NBICU05_Cell30Volt "Cell30Volt单体30电压值";
CM_ SG_ 2564357893 NBICU05_Cell31Volt "Cell31Volt单体31电压值";
CM_ SG_ 2564357893 NBICU05_Cell32Volt "Cell32Volt单体32电压值";
CM_ BO_ 2564423429 "NBICU05 Tx and Cell Voltage09";
CM_ SG_ 2564423429 NBICU05_Cell33Volt "Cell33Volt单体33电压值";
CM_ SG_ 2564423429 NBICU05_Cell34Volt "Cell34Volt单体34电压值";
CM_ SG_ 2564423429 NBICU05_Cell35Volt "Cell35Volt单体35电压值";
CM_ SG_ 2564423429 NBICU05_Cell36Volt "Cell36Volt单体36电压值";
CM_ BO_ 2564488965 "NBICU05 Tx and Cell Temp01";
CM_ SG_ 2564488965 NBICU05_Temp01 "NTC01-温度值";
CM_ SG_ 2564488965 NBICU05_Temp02 "NTC02-温度值";
CM_ SG_ 2564488965 NBICU05_Temp03 "NTC03-温度值";
CM_ SG_ 2564488965 NBICU05_Temp04 "NTC04-温度值";
CM_ SG_ 2564488965 NBICU05_Temp05 "NTC05-温度值";
CM_ SG_ 2564488965 NBICU05_Temp06 "NTC06-温度值";
CM_ SG_ 2564488965 NBICU05_Temp07 "NTC07-温度值";
CM_ SG_ 2564488965 NBICU05_Temp08 "NTC08-温度值";
CM_ BO_ 2564554501 "NBICU05 Tx and Cell Temp02";
CM_ SG_ 2564554501 NBICU05_Temp09 "NTC09-温度值";
CM_ SG_ 2564554501 NBICU05_Temp10 "NTC10-温度值";
CM_ SG_ 2564554501 NBICU05_Temp11 "NTC11-温度值";
CM_ SG_ 2564554501 NBICU05_Temp12 "NTC12-温度值";
CM_ SG_ 2564554501 NBICU05_Temp13 "NTC13-温度值";
CM_ SG_ 2564554501 NBICU05_Temp14 "NTC14-温度值";
CM_ SG_ 2564554501 NBICU05_Temp15 "NTC15-温度值";
CM_ SG_ 2564554501 NBICU05_Temp16 "NTC16-温度值";
CM_ BO_ 2564620037 "NBICU05 Tx and Cell Temp03";
CM_ SG_ 2564620037 NBICU05_Temp17 "NTC17-温度值";
CM_ SG_ 2564620037 NBICU05_Temp18 "NTC18-温度值";
CM_ SG_ 2564620037 NBICU05_Temp19 "NTC19-温度值";
CM_ SG_ 2564620037 NBICU05_Temp20 "NTC20-温度值";
CM_ SG_ 2564620037 NBICU05_Temp21 "NTC21-温度值";
CM_ SG_ 2564620037 NBICU05_Temp22 "NTC22-温度值";
CM_ SG_ 2564620037 NBICU05_Temp23 "NTC23-温度值";
CM_ SG_ 2564620037 NBICU05_Temp24 "NTC24-温度值";
CM_ BO_ 2564685573 "NBICU05 Tx and Cell Temp04";
CM_ SG_ 2564685573 NBICU05_Temp25 "NTC25-温度值";
CM_ SG_ 2564685573 NBICU05_Temp26 "NTC26-温度值";
CM_ SG_ 2564685573 NBICU05_Temp27 "NTC27-温度值";
CM_ SG_ 2564685573 NBICU05_Temp28 "NTC28-温度值";
CM_ SG_ 2564685573 NBICU05_Temp29 "NTC29-温度值";
CM_ SG_ 2564685573 NBICU05_Temp30 "NTC30-温度值";
CM_ SG_ 2564685573 NBICU05_Temp31 "NTC31-温度值";
CM_ SG_ 2564685573 NBICU05_Temp32 "NTC32-温度值";
CM_ BO_ 2564751109 "NBICU05 Tx and Cell Temp05";
CM_ SG_ 2564751109 NBICU05_Temp33 "NTC33-温度值";
CM_ SG_ 2564751109 NBICU05_Temp34 "NTC34-温度值";
CM_ SG_ 2564751109 NBICU05_Temp35 "NTC35-温度值";
CM_ SG_ 2564751109 NBICU05_Temp36 "NTC36-温度值";
CM_ BO_ 2564947717 "NBICU05 Tx and Software";
CM_ SG_ 2564947717 NBICU05_NBCMU_Addr_SW "NBICU05 NBCMU Address
NBICU05接收NBCMU地址";
CM_ SG_ 2564947717 NBICU05_SW01 "NBICU05 Software Byte 01
NBICU05软件版本第01字节";
CM_ SG_ 2564947717 NBICU05_SW02 "NBICU05 Software Byte 02
NBICU05软件版本第02字节";
CM_ SG_ 2564947717 NBICU05_SW03 "NBICU05 Software Byte 03
NBICU05软件版本第03字节";
CM_ SG_ 2564947717 NBICU05_SW04 "NBICU05 Software Byte 04
NBICU05软件版本第04字节";
CM_ SG_ 2564947717 NBICU05_SW05 "NBICU05 Software Byte 05
NBICU05软件版本第05字节";
CM_ SG_ 2564947717 NBICU05_SW06 "NBICU05 Software Byte 06
NBICU05软件版本第06字节";
CM_ SG_ 2564947717 NBICU05_SW07 "NBICU05 Software Byte 07
NBICU05软件版本第07字节";
CM_ BO_ 2565013253 "NBICU05 Tx and Hardware";
CM_ SG_ 2565013253 NBICU05_NBCMU_Addr_HW "NBICU05 NBCMU Address
NBICU05接收NBCMU地址";
CM_ SG_ 2565013253 NBICU05_HW01 "NBICU05 Hardware Byte 01
NBICU05硬件版本第01字节";
CM_ SG_ 2565013253 NBICU05_HW02 "NBICU05 Hardware Byte 02
NBICU05硬件版本第02字节";
CM_ SG_ 2565013253 NBICU05_HW03 "NBICU05 Hardware Byte 03
NBICU05硬件版本第03字节";
CM_ SG_ 2565013253 NBICU05_HW04 "NBICU05 Hardware Byte 04
NBICU05硬件版本第04字节";
CM_ SG_ 2565013253 NBICU05_HW05 "NBICU05 Hardware Byte 05
NBICU05硬件版本第05字节";
CM_ SG_ 2565013253 NBICU05_HW06 "NBICU05 Hardware Byte 06
NBICU05硬件版本第06字节";
CM_ SG_ 2565013253 NBICU05_HW07 "NBICU05 Hardware Byte 07
NBICU05硬件版本第07字节";
CM_ BO_ 2564677381 "NBICU05 Tx and DiaResponse";
CM_ BO_ 2562785030 "NBICU06 Tx and Run State";
CM_ SG_ 2562785030 NBICU06_Address "Address
从机地址";
CM_ SG_ 2562785030 NBICU06_CellVNum "CellVNum
配置电压采集串数";
CM_ SG_ 2562785030 NBICU06_TempNum "TempNum
配置温度采集个数";
CM_ SG_ 2562785030 NBICU06_ErrFlag "ErrFlag
故障标志(预留)";
CM_ SG_ 2562785030 NBICU06_AddrInput_State "Addr Input_State
检测地址状态";
CM_ SG_ 2562785030 NBICU06_AddrOutput_State "Addr Output_State
输出地址状态";
CM_ SG_ 2562785030 NBICU06_HSD01Sta "HSD01
高边1控制状态(预留)";
CM_ SG_ 2562785030 NBICU06_SoftVer "SoftVer
软件版本";
CM_ SG_ 2562785030 NBICU06_HardVer "HardVer
硬件版本";
CM_ SG_ 2562785030 NBICU06_RunAlivCoun "AliveCounter
心跳指数";
CM_ BO_ 2562850566 "NBICU06 Tx and VoltExtremeInfo";
CM_ SG_ 2562850566 NBICU06_CellVoltMax "最高单体电压";
CM_ SG_ 2562850566 NBICU06_CellVoltMin "最低单体电压";
CM_ SG_ 2562850566 NBICU06_CellVoltMaxCode "最高单体电压序号";
CM_ SG_ 2562850566 NBICU06_CellVoltMinCode "最低单体电压序号";
CM_ SG_ 2562850566 NBICU06_CellSumVolt "电池包累计总压";
CM_ BO_ 2562916102 "NBICU06 Tx and TempExtremeInfo";
CM_ SG_ 2562916102 NBICU06_CellTempMax "最高温度";
CM_ SG_ 2562916102 NBICU06_CellTempMin "最低温度";
CM_ SG_ 2562916102 NBICU06_CellTempAvg "平均温度";
CM_ SG_ 2562916102 NBICU06_CellTempMaxCode "最高温度序号";
CM_ SG_ 2562916102 NBICU06_CellTempMinCode "最低温度序号";
CM_ SG_ 2562916102 NBICU06_SupplyVolt "供电电压";
CM_ SG_ 2562916102 NBICU06_PCB_Temp "板载温度";
CM_ BO_ 2562981638 "NBICU06 Tx and Balance State";
CM_ SG_ 2562981638 NBICU06_Cell0108BalaSta "Cell0108BalaSta
单体1至8通道均衡状态";
CM_ SG_ 2562981638 NBICU06_Cell0916BalaSta "Cell0916BalaSta
单体9至16通道均衡标志";
CM_ SG_ 2562981638 NBICU06_Cell1724BalaSta "Cell1724BalaSta
单体17至24通道均衡状态";
CM_ SG_ 2562981638 NBICU06_Cell2532BalaSta "Cell2532BalaSta
单体25至32通道均衡状态";
CM_ SG_ 2562981638 NBICU06_Cell3336BalaSta "Cell3336BalaSta
单体33至36通道均衡状态";
CM_ SG_ 2562981638 NBICU06_SysSOH "Sys SOH
电池包SOH";
CM_ SG_ 2562981638 NBICU06_CycleTime "CycleTime
循环次数";
CM_ BO_ 2563899142 "NBICU06 Tx and Cell Voltage01";
CM_ SG_ 2563899142 NBICU06_Cell01Volt "Cell01Volt单体01电压值";
CM_ SG_ 2563899142 NBICU06_Cell02Volt "Cell02Volt单体02电压值";
CM_ SG_ 2563899142 NBICU06_Cell03Volt "Cell03Volt单体03电压值";
CM_ SG_ 2563899142 NBICU06_Cell04Volt "Cell04Volt单体04电压值";
CM_ BO_ 2563964678 "NBICU06 Tx and Cell Voltage02";
CM_ SG_ 2563964678 NBICU06_Cell05Volt "Cell05Volt单体05电压值";
CM_ SG_ 2563964678 NBICU06_Cell06Volt "Cell06Volt单体06电压值";
CM_ SG_ 2563964678 NBICU06_Cell07Volt "Cell07Volt单体07电压值";
CM_ SG_ 2563964678 NBICU06_Cell08Volt "Cell08Volt单体08电压值";
CM_ BO_ 2564030214 "NBICU06 Tx and Cell Voltage03";
CM_ SG_ 2564030214 NBICU06_Cell09Volt "Cell09Volt单体09电压值";
CM_ SG_ 2564030214 NBICU06_Cell10Volt "Cell10Volt单体10电压值";
CM_ SG_ 2564030214 NBICU06_Cell11Volt "Cell11Volt单体11电压值";
CM_ SG_ 2564030214 NBICU06_Cell12Volt "Cell12Volt单体12电压值";
CM_ BO_ 2564095750 "NBICU06 Tx and Cell Voltage04";
CM_ SG_ 2564095750 NBICU06_Cell13Volt "Cell13Volt单体13电压值";
CM_ SG_ 2564095750 NBICU06_Cell14Volt "Cell14Volt单体14电压值";
CM_ SG_ 2564095750 NBICU06_Cell15Volt "Cell15Volt单体15电压值";
CM_ SG_ 2564095750 NBICU06_Cell16Volt "Cell16Volt单体16电压值";
CM_ BO_ 2564161286 "NBICU06 Tx and Cell Voltage05";
CM_ SG_ 2564161286 NBICU06_Cell17Volt "Cell17Volt单体17电压值";
CM_ SG_ 2564161286 NBICU06_Cell18Volt "Cell18Volt单体18电压值";
CM_ SG_ 2564161286 NBICU06_Cell19Volt "Cell19Volt单体19电压值";
CM_ SG_ 2564161286 NBICU06_Cell20Volt "Cell20Volt单体20电压值";
CM_ BO_ 2564226822 "NBICU06 Tx and Cell Voltage06";
CM_ SG_ 2564226822 NBICU06_Cell21Volt "Cell21Volt单体21电压值";
CM_ SG_ 2564226822 NBICU06_Cell22Volt "Cell22Volt单体22电压值";
CM_ SG_ 2564226822 NBICU06_Cell23Volt "Cell23Volt单体23电压值";
CM_ SG_ 2564226822 NBICU06_Cell24Volt "Cell24Volt单体24电压值";
CM_ BO_ 2564292358 "NBICU06 Tx and Cell Voltage07";
CM_ SG_ 2564292358 NBICU06_Cell25Volt "Cell25Volt单体25电压值";
CM_ SG_ 2564292358 NBICU06_Cell26Volt "Cell26Volt单体26电压值";
CM_ SG_ 2564292358 NBICU06_Cell27Volt "Cell27Volt单体27电压值";
CM_ SG_ 2564292358 NBICU06_Cell28Volt "Cell28Volt单体28电压值";
CM_ BO_ 2564357894 "NBICU06 Tx and Cell Voltage08";
CM_ SG_ 2564357894 NBICU06_Cell29Volt "Cell29Volt单体29电压值";
CM_ SG_ 2564357894 NBICU06_Cell30Volt "Cell30Volt单体30电压值";
CM_ SG_ 2564357894 NBICU06_Cell31Volt "Cell31Volt单体31电压值";
CM_ SG_ 2564357894 NBICU06_Cell32Volt "Cell32Volt单体32电压值";
CM_ BO_ 2564423430 "NBICU06 Tx and Cell Voltage09";
CM_ SG_ 2564423430 NBICU06_Cell33Volt "Cell33Volt单体33电压值";
CM_ SG_ 2564423430 NBICU06_Cell34Volt "Cell34Volt单体34电压值";
CM_ SG_ 2564423430 NBICU06_Cell35Volt "Cell35Volt单体35电压值";
CM_ SG_ 2564423430 NBICU06_Cell36Volt "Cell36Volt单体36电压值";
CM_ BO_ 2564488966 "NBICU06 Tx and Cell Temp01";
CM_ SG_ 2564488966 NBICU06_Temp01 "NTC01-温度值";
CM_ SG_ 2564488966 NBICU06_Temp02 "NTC02-温度值";
CM_ SG_ 2564488966 NBICU06_Temp03 "NTC03-温度值";
CM_ SG_ 2564488966 NBICU06_Temp04 "NTC04-温度值";
CM_ SG_ 2564488966 NBICU06_Temp05 "NTC05-温度值";
CM_ SG_ 2564488966 NBICU06_Temp06 "NTC06-温度值";
CM_ SG_ 2564488966 NBICU06_Temp07 "NTC07-温度值";
CM_ SG_ 2564488966 NBICU06_Temp08 "NTC08-温度值";
CM_ BO_ 2564554502 "NBICU06 Tx and Cell Temp02";
CM_ SG_ 2564554502 NBICU06_Temp09 "NTC09-温度值";
CM_ SG_ 2564554502 NBICU06_Temp10 "NTC10-温度值";
CM_ SG_ 2564554502 NBICU06_Temp11 "NTC11-温度值";
CM_ SG_ 2564554502 NBICU06_Temp12 "NTC12-温度值";
CM_ SG_ 2564554502 NBICU06_Temp13 "NTC13-温度值";
CM_ SG_ 2564554502 NBICU06_Temp14 "NTC14-温度值";
CM_ SG_ 2564554502 NBICU06_Temp15 "NTC15-温度值";
CM_ SG_ 2564554502 NBICU06_Temp16 "NTC16-温度值";
CM_ BO_ 2564620038 "NBICU06 Tx and Cell Temp03";
CM_ SG_ 2564620038 NBICU06_Temp17 "NTC17-温度值";
CM_ SG_ 2564620038 NBICU06_Temp18 "NTC18-温度值";
CM_ SG_ 2564620038 NBICU06_Temp19 "NTC19-温度值";
CM_ SG_ 2564620038 NBICU06_Temp20 "NTC20-温度值";
CM_ SG_ 2564620038 NBICU06_Temp21 "NTC21-温度值";
CM_ SG_ 2564620038 NBICU06_Temp22 "NTC22-温度值";
CM_ SG_ 2564620038 NBICU06_Temp23 "NTC23-温度值";
CM_ SG_ 2564620038 NBICU06_Temp24 "NTC24-温度值";
CM_ BO_ 2564685574 "NBICU06 Tx and Cell Temp04";
CM_ SG_ 2564685574 NBICU06_Temp25 "NTC25-温度值";
CM_ SG_ 2564685574 NBICU06_Temp26 "NTC26-温度值";
CM_ SG_ 2564685574 NBICU06_Temp27 "NTC27-温度值";
CM_ SG_ 2564685574 NBICU06_Temp28 "NTC28-温度值";
CM_ SG_ 2564685574 NBICU06_Temp29 "NTC29-温度值";
CM_ SG_ 2564685574 NBICU06_Temp30 "NTC30-温度值";
CM_ SG_ 2564685574 NBICU06_Temp31 "NTC31-温度值";
CM_ SG_ 2564685574 NBICU06_Temp32 "NTC32-温度值";
CM_ BO_ 2564751110 "NBICU06 Tx and Cell Temp05";
CM_ SG_ 2564751110 NBICU06_Temp33 "NTC33-温度值";
CM_ SG_ 2564751110 NBICU06_Temp34 "NTC34-温度值";
CM_ SG_ 2564751110 NBICU06_Temp35 "NTC35-温度值";
CM_ SG_ 2564751110 NBICU06_Temp36 "NTC36-温度值";
CM_ BO_ 2564947718 "NBICU06 Tx and Software";
CM_ SG_ 2564947718 NBICU06_NBCMU_Addr_SW "NBICU06 NBCMU Address
NBICU06接收NBCMU地址";
CM_ SG_ 2564947718 NBICU06_SW01 "NBICU06 Software Byte 01
NBICU06软件版本第01字节";
CM_ SG_ 2564947718 NBICU06_SW02 "NBICU06 Software Byte 02
NBICU06软件版本第02字节";
CM_ SG_ 2564947718 NBICU06_SW03 "NBICU06 Software Byte 03
NBICU06软件版本第03字节";
CM_ SG_ 2564947718 NBICU06_SW04 "NBICU06 Software Byte 04
NBICU06软件版本第04字节";
CM_ SG_ 2564947718 NBICU06_SW05 "NBICU06 Software Byte 05
NBICU06软件版本第05字节";
CM_ SG_ 2564947718 NBICU06_SW06 "NBICU06 Software Byte 06
NBICU06软件版本第06字节";
CM_ SG_ 2564947718 NBICU06_SW07 "NBICU06 Software Byte 07
NBICU06软件版本第07字节";
CM_ BO_ 2565013254 "NBICU06 Tx and Hardware";
CM_ SG_ 2565013254 NBICU06_NBCMU_Addr_HW "NBICU06 NBCMU Address
NBICU06接收NBCMU地址";
CM_ SG_ 2565013254 NBICU06_HW01 "NBICU06 Hardware Byte 01
NBICU06硬件版本第01字节";
CM_ SG_ 2565013254 NBICU06_HW02 "NBICU06 Hardware Byte 02
NBICU06硬件版本第02字节";
CM_ SG_ 2565013254 NBICU06_HW03 "NBICU06 Hardware Byte 03
NBICU06硬件版本第03字节";
CM_ SG_ 2565013254 NBICU06_HW04 "NBICU06 Hardware Byte 04
NBICU06硬件版本第04字节";
CM_ SG_ 2565013254 NBICU06_HW05 "NBICU06 Hardware Byte 05
NBICU06硬件版本第05字节";
CM_ SG_ 2565013254 NBICU06_HW06 "NBICU06 Hardware Byte 06
NBICU06硬件版本第06字节";
CM_ SG_ 2565013254 NBICU06_HW07 "NBICU06 Hardware Byte 07
NBICU06硬件版本第07字节";
CM_ BO_ 2564677382 "NBICU06 Tx and DiaResponse";
CM_ BO_ 2562785031 "NBICU07 Tx and Run State";
CM_ SG_ 2562785031 NBICU07_Address "Address
从机地址";
CM_ SG_ 2562785031 NBICU07_CellVNum "CellVNum
配置电压采集串数";
CM_ SG_ 2562785031 NBICU07_TempNum "TempNum
配置温度采集个数";
CM_ SG_ 2562785031 NBICU07_ErrFlag "ErrFlag
故障标志(预留)";
CM_ SG_ 2562785031 NBICU07_AddrInput_State "Addr Input_State
检测地址状态";
CM_ SG_ 2562785031 NBICU07_AddrOutput_State "Addr Output_State
输出地址状态";
CM_ SG_ 2562785031 NBICU07_HSD01Sta "HSD01
高边1控制状态(预留)";
CM_ SG_ 2562785031 NBICU07_SoftVer "SoftVer
软件版本";
CM_ SG_ 2562785031 NBICU07_HardVer "HardVer
硬件版本";
CM_ SG_ 2562785031 NBICU07_RunAlivCoun "AliveCounter
心跳指数";
CM_ BO_ 2562850567 "NBICU07 Tx and VoltExtremeInfo";
CM_ SG_ 2562850567 NBICU07_CellVoltMax "最高单体电压";
CM_ SG_ 2562850567 NBICU07_CellVoltMin "最低单体电压";
CM_ SG_ 2562850567 NBICU07_CellVoltMaxCode "最高单体电压序号";
CM_ SG_ 2562850567 NBICU07_CellVoltMinCode "最低单体电压序号";
CM_ SG_ 2562850567 NBICU07_CellSumVolt "电池包累计总压";
CM_ BO_ 2562916103 "NBICU07 Tx and TempExtremeInfo";
CM_ SG_ 2562916103 NBICU07_CellTempMax "最高温度";
CM_ SG_ 2562916103 NBICU07_CellTempMin "最低温度";
CM_ SG_ 2562916103 NBICU07_CellTempAvg "平均温度";
CM_ SG_ 2562916103 NBICU07_CellTempMaxCode "最高温度序号";
CM_ SG_ 2562916103 NBICU07_CellTempMinCode "最低温度序号";
CM_ SG_ 2562916103 NBICU07_SupplyVolt "供电电压";
CM_ SG_ 2562916103 NBICU07_PCB_Temp "板载温度";
CM_ BO_ 2562981639 "NBICU07 Tx and Balance State";
CM_ SG_ 2562981639 NBICU07_Cell0108BalaSta "Cell0108BalaSta
单体1至8通道均衡状态";
CM_ SG_ 2562981639 NBICU07_Cell0916BalaSta "Cell0916BalaSta
单体9至16通道均衡标志";
CM_ SG_ 2562981639 NBICU07_Cell1724BalaSta "Cell1724BalaSta
单体17至24通道均衡状态";
CM_ SG_ 2562981639 NBICU07_Cell2532BalaSta "Cell2532BalaSta
单体25至32通道均衡状态";
CM_ SG_ 2562981639 NBICU07_Cell3336BalaSta "Cell3336BalaSta
单体33至36通道均衡状态";
CM_ SG_ 2562981639 NBICU07_SysSOH "Sys SOH
电池包SOH";
CM_ SG_ 2562981639 NBICU07_CycleTime "CycleTime
循环次数";
CM_ BO_ 2563899143 "NBICU07 Tx and Cell Voltage01";
CM_ SG_ 2563899143 NBICU07_Cell01Volt "Cell01Volt单体01电压值";
CM_ SG_ 2563899143 NBICU07_Cell02Volt "Cell02Volt单体02电压值";
CM_ SG_ 2563899143 NBICU07_Cell03Volt "Cell03Volt单体03电压值";
CM_ SG_ 2563899143 NBICU07_Cell04Volt "Cell04Volt单体04电压值";
CM_ BO_ 2563964679 "NBICU07 Tx and Cell Voltage02";
CM_ SG_ 2563964679 NBICU07_Cell05Volt "Cell05Volt单体05电压值";
CM_ SG_ 2563964679 NBICU07_Cell06Volt "Cell06Volt单体06电压值";
CM_ SG_ 2563964679 NBICU07_Cell07Volt "Cell07Volt单体07电压值";
CM_ SG_ 2563964679 NBICU07_Cell08Volt "Cell08Volt单体08电压值";
CM_ BO_ 2564030215 "NBICU07 Tx and Cell Voltage03";
CM_ SG_ 2564030215 NBICU07_Cell09Volt "Cell09Volt单体09电压值";
CM_ SG_ 2564030215 NBICU07_Cell10Volt "Cell10Volt单体10电压值";
CM_ SG_ 2564030215 NBICU07_Cell11Volt "Cell11Volt单体11电压值";
CM_ SG_ 2564030215 NBICU07_Cell12Volt "Cell12Volt单体12电压值";
CM_ BO_ 2564095751 "NBICU07 Tx and Cell Voltage04";
CM_ SG_ 2564095751 NBICU07_Cell13Volt "Cell13Volt单体13电压值";
CM_ SG_ 2564095751 NBICU07_Cell14Volt "Cell14Volt单体14电压值";
CM_ SG_ 2564095751 NBICU07_Cell15Volt "Cell15Volt单体15电压值";
CM_ SG_ 2564095751 NBICU07_Cell16Volt "Cell16Volt单体16电压值";
CM_ BO_ 2564161287 "NBICU07 Tx and Cell Voltage05";
CM_ SG_ 2564161287 NBICU07_Cell17Volt "Cell17Volt单体17电压值";
CM_ SG_ 2564161287 NBICU07_Cell18Volt "Cell18Volt单体18电压值";
CM_ SG_ 2564161287 NBICU07_Cell19Volt "Cell19Volt单体19电压值";
CM_ SG_ 2564161287 NBICU07_Cell20Volt "Cell20Volt单体20电压值";
CM_ BO_ 2564226823 "NBICU07 Tx and Cell Voltage06";
CM_ SG_ 2564226823 NBICU07_Cell21Volt "Cell21Volt单体21电压值";
CM_ SG_ 2564226823 NBICU07_Cell22Volt "Cell22Volt单体22电压值";
CM_ SG_ 2564226823 NBICU07_Cell23Volt "Cell23Volt单体23电压值";
CM_ SG_ 2564226823 NBICU07_Cell24Volt "Cell24Volt单体24电压值";
CM_ BO_ 2564292359 "NBICU07 Tx and Cell Voltage07";
CM_ SG_ 2564292359 NBICU07_Cell25Volt "Cell25Volt单体25电压值";
CM_ SG_ 2564292359 NBICU07_Cell26Volt "Cell26Volt单体26电压值";
CM_ SG_ 2564292359 NBICU07_Cell27Volt "Cell27Volt单体27电压值";
CM_ SG_ 2564292359 NBICU07_Cell28Volt "Cell28Volt单体28电压值";
CM_ BO_ 2564357895 "NBICU07 Tx and Cell Voltage08";
CM_ SG_ 2564357895 NBICU07_Cell29Volt "Cell29Volt单体29电压值";
CM_ SG_ 2564357895 NBICU07_Cell30Volt "Cell30Volt单体30电压值";
CM_ SG_ 2564357895 NBICU07_Cell31Volt "Cell31Volt单体31电压值";
CM_ SG_ 2564357895 NBICU07_Cell32Volt "Cell32Volt单体32电压值";
CM_ BO_ 2564423431 "NBICU07 Tx and Cell Voltage09";
CM_ SG_ 2564423431 NBICU07_Cell33Volt "Cell33Volt单体33电压值";
CM_ SG_ 2564423431 NBICU07_Cell34Volt "Cell34Volt单体34电压值";
CM_ SG_ 2564423431 NBICU07_Cell35Volt "Cell35Volt单体35电压值";
CM_ SG_ 2564423431 NBICU07_Cell36Volt "Cell36Volt单体36电压值";
CM_ BO_ 2564488967 "NBICU07 Tx and Cell Temp01";
CM_ SG_ 2564488967 NBICU07_Temp01 "NTC01-温度值";
CM_ SG_ 2564488967 NBICU07_Temp02 "NTC02-温度值";
CM_ SG_ 2564488967 NBICU07_Temp03 "NTC03-温度值";
CM_ SG_ 2564488967 NBICU07_Temp04 "NTC04-温度值";
CM_ SG_ 2564488967 NBICU07_Temp05 "NTC05-温度值";
CM_ SG_ 2564488967 NBICU07_Temp06 "NTC06-温度值";
CM_ SG_ 2564488967 NBICU07_Temp07 "NTC07-温度值";
CM_ SG_ 2564488967 NBICU07_Temp08 "NTC08-温度值";
CM_ BO_ 2564554503 "NBICU07 Tx and Cell Temp02";
CM_ SG_ 2564554503 NBICU07_Temp09 "NTC09-温度值";
CM_ SG_ 2564554503 NBICU07_Temp10 "NTC10-温度值";
CM_ SG_ 2564554503 NBICU07_Temp11 "NTC11-温度值";
CM_ SG_ 2564554503 NBICU07_Temp12 "NTC12-温度值";
CM_ SG_ 2564554503 NBICU07_Temp13 "NTC13-温度值";
CM_ SG_ 2564554503 NBICU07_Temp14 "NTC14-温度值";
CM_ SG_ 2564554503 NBICU07_Temp15 "NTC15-温度值";
CM_ SG_ 2564554503 NBICU07_Temp16 "NTC16-温度值";
CM_ BO_ 2564620039 "NBICU07 Tx and Cell Temp03";
CM_ SG_ 2564620039 NBICU07_Temp17 "NTC17-温度值";
CM_ SG_ 2564620039 NBICU07_Temp18 "NTC18-温度值";
CM_ SG_ 2564620039 NBICU07_Temp19 "NTC19-温度值";
CM_ SG_ 2564620039 NBICU07_Temp20 "NTC20-温度值";
CM_ SG_ 2564620039 NBICU07_Temp21 "NTC21-温度值";
CM_ SG_ 2564620039 NBICU07_Temp22 "NTC22-温度值";
CM_ SG_ 2564620039 NBICU07_Temp23 "NTC23-温度值";
CM_ SG_ 2564620039 NBICU07_Temp24 "NTC24-温度值";
CM_ BO_ 2564685575 "NBICU07 Tx and Cell Temp04";
CM_ SG_ 2564685575 NBICU07_Temp25 "NTC25-温度值";
CM_ SG_ 2564685575 NBICU07_Temp26 "NTC26-温度值";
CM_ SG_ 2564685575 NBICU07_Temp27 "NTC27-温度值";
CM_ SG_ 2564685575 NBICU07_Temp28 "NTC28-温度值";
CM_ SG_ 2564685575 NBICU07_Temp29 "NTC29-温度值";
CM_ SG_ 2564685575 NBICU07_Temp30 "NTC30-温度值";
CM_ SG_ 2564685575 NBICU07_Temp31 "NTC31-温度值";
CM_ SG_ 2564685575 NBICU07_Temp32 "NTC32-温度值";
CM_ BO_ 2564751111 "NBICU07 Tx and Cell Temp05";
CM_ SG_ 2564751111 NBICU07_Temp33 "NTC33-温度值";
CM_ SG_ 2564751111 NBICU07_Temp34 "NTC34-温度值";
CM_ SG_ 2564751111 NBICU07_Temp35 "NTC35-温度值";
CM_ SG_ 2564751111 NBICU07_Temp36 "NTC36-温度值";
CM_ BO_ 2564947719 "NBICU07 Tx and Software";
CM_ SG_ 2564947719 NBICU07_NBCMU_Addr_SW "NBICU07 NBCMU Address
NBICU07接收NBCMU地址";
CM_ SG_ 2564947719 NBICU07_SW01 "NBICU07 Software Byte 01
NBICU07软件版本第01字节";
CM_ SG_ 2564947719 NBICU07_SW02 "NBICU07 Software Byte 02
NBICU07软件版本第02字节";
CM_ SG_ 2564947719 NBICU07_SW03 "NBICU07 Software Byte 03
NBICU07软件版本第03字节";
CM_ SG_ 2564947719 NBICU07_SW04 "NBICU07 Software Byte 04
NBICU07软件版本第04字节";
CM_ SG_ 2564947719 NBICU07_SW05 "NBICU07 Software Byte 05
NBICU07软件版本第05字节";
CM_ SG_ 2564947719 NBICU07_SW06 "NBICU07 Software Byte 06
NBICU07软件版本第06字节";
CM_ SG_ 2564947719 NBICU07_SW07 "NBICU07 Software Byte 07
NBICU07软件版本第07字节";
CM_ BO_ 2565013255 "NBICU07 Tx and Hardware";
CM_ SG_ 2565013255 NBICU07_NBCMU_Addr_HW "NBICU07 NBCMU Address
NBICU07接收NBCMU地址";
CM_ SG_ 2565013255 NBICU07_HW01 "NBICU07 Hardware Byte 01
NBICU07硬件版本第01字节";
CM_ SG_ 2565013255 NBICU07_HW02 "NBICU07 Hardware Byte 02
NBICU07硬件版本第02字节";
CM_ SG_ 2565013255 NBICU07_HW03 "NBICU07 Hardware Byte 03
NBICU07硬件版本第03字节";
CM_ SG_ 2565013255 NBICU07_HW04 "NBICU07 Hardware Byte 04
NBICU07硬件版本第04字节";
CM_ SG_ 2565013255 NBICU07_HW05 "NBICU07 Hardware Byte 05
NBICU07硬件版本第05字节";
CM_ SG_ 2565013255 NBICU07_HW06 "NBICU07 Hardware Byte 06
NBICU07硬件版本第06字节";
CM_ SG_ 2565013255 NBICU07_HW07 "NBICU07 Hardware Byte 07
NBICU07硬件版本第07字节";
CM_ BO_ 2564677383 "NBICU07 Tx and DiaResponse";
CM_ BO_ 2562785032 "NBICU08 Tx and Run State";
CM_ SG_ 2562785032 NBICU08_Address "Address
从机地址";
CM_ SG_ 2562785032 NBICU08_CellVNum "CellVNum
配置电压采集串数";
CM_ SG_ 2562785032 NBICU08_TempNum "TempNum
配置温度采集个数";
CM_ SG_ 2562785032 NBICU08_ErrFlag "ErrFlag
故障标志(预留)";
CM_ SG_ 2562785032 NBICU08_AddrInput_State "Addr Input_State
检测地址状态";
CM_ SG_ 2562785032 NBICU08_AddrOutput_State "Addr Output_State
输出地址状态";
CM_ SG_ 2562785032 NBICU08_HSD01Sta "HSD01
高边1控制状态(预留)";
CM_ SG_ 2562785032 NBICU08_SoftVer "SoftVer
软件版本";
CM_ SG_ 2562785032 NBICU08_HardVer "HardVer
硬件版本";
CM_ SG_ 2562785032 NBICU08_RunAlivCoun "AliveCounter
心跳指数";
CM_ BO_ 2562850568 "NBICU08 Tx and VoltExtremeInfo";
CM_ SG_ 2562850568 NBICU08_CellVoltMax "最高单体电压";
CM_ SG_ 2562850568 NBICU08_CellVoltMin "最低单体电压";
CM_ SG_ 2562850568 NBICU08_CellVoltMaxCode "最高单体电压序号";
CM_ SG_ 2562850568 NBICU08_CellVoltMinCode "最低单体电压序号";
CM_ SG_ 2562850568 NBICU08_CellSumVolt "电池包累计总压";
CM_ BO_ 2562916104 "NBICU08 Tx and TempExtremeInfo";
CM_ SG_ 2562916104 NBICU08_CellTempMax "最高温度";
CM_ SG_ 2562916104 NBICU08_CellTempMin "最低温度";
CM_ SG_ 2562916104 NBICU08_CellTempAvg "平均温度";
CM_ SG_ 2562916104 NBICU08_CellTempMaxCode "最高温度序号";
CM_ SG_ 2562916104 NBICU08_CellTempMinCode "最低温度序号";
CM_ SG_ 2562916104 NBICU08_SupplyVolt "供电电压";
CM_ SG_ 2562916104 NBICU08_PCB_Temp "板载温度";
CM_ BO_ 2562981640 "NBICU08 Tx and Balance State";
CM_ SG_ 2562981640 NBICU08_Cell0108BalaSta "Cell0108BalaSta
单体1至8通道均衡状态";
CM_ SG_ 2562981640 NBICU08_Cell0916BalaSta "Cell0916BalaSta
单体9至16通道均衡标志";
CM_ SG_ 2562981640 NBICU08_Cell1724BalaSta "Cell1724BalaSta
单体17至24通道均衡状态";
CM_ SG_ 2562981640 NBICU08_Cell2532BalaSta "Cell2532BalaSta
单体25至32通道均衡状态";
CM_ SG_ 2562981640 NBICU08_Cell3336BalaSta "Cell3336BalaSta
单体33至36通道均衡状态";
CM_ SG_ 2562981640 NBICU08_SysSOH "Sys SOH
电池包SOH";
CM_ SG_ 2562981640 NBICU08_CycleTime "CycleTime
循环次数";
CM_ BO_ 2563899144 "NBICU08 Tx and Cell Voltage01";
CM_ SG_ 2563899144 NBICU08_Cell01Volt "Cell01Volt单体01电压值";
CM_ SG_ 2563899144 NBICU08_Cell02Volt "Cell02Volt单体02电压值";
CM_ SG_ 2563899144 NBICU08_Cell03Volt "Cell03Volt单体03电压值";
CM_ SG_ 2563899144 NBICU08_Cell04Volt "Cell04Volt单体04电压值";
CM_ BO_ 2563964680 "NBICU08 Tx and Cell Voltage02";
CM_ SG_ 2563964680 NBICU08_Cell05Volt "Cell05Volt单体05电压值";
CM_ SG_ 2563964680 NBICU08_Cell06Volt "Cell06Volt单体06电压值";
CM_ SG_ 2563964680 NBICU08_Cell07Volt "Cell07Volt单体07电压值";
CM_ SG_ 2563964680 NBICU08_Cell08Volt "Cell08Volt单体08电压值";
CM_ BO_ 2564030216 "NBICU08 Tx and Cell Voltage03";
CM_ SG_ 2564030216 NBICU08_Cell09Volt "Cell09Volt单体09电压值";
CM_ SG_ 2564030216 NBICU08_Cell10Volt "Cell10Volt单体10电压值";
CM_ SG_ 2564030216 NBICU08_Cell11Volt "Cell11Volt单体11电压值";
CM_ SG_ 2564030216 NBICU08_Cell12Volt "Cell12Volt单体12电压值";
CM_ BO_ 2564095752 "NBICU08 Tx and Cell Voltage04";
CM_ SG_ 2564095752 NBICU08_Cell13Volt "Cell13Volt单体13电压值";
CM_ SG_ 2564095752 NBICU08_Cell14Volt "Cell14Volt单体14电压值";
CM_ SG_ 2564095752 NBICU08_Cell15Volt "Cell15Volt单体15电压值";
CM_ SG_ 2564095752 NBICU08_Cell16Volt "Cell16Volt单体16电压值";
CM_ BO_ 2564161288 "NBICU08 Tx and Cell Voltage05";
CM_ SG_ 2564161288 NBICU08_Cell17Volt "Cell17Volt单体17电压值";
CM_ SG_ 2564161288 NBICU08_Cell18Volt "Cell18Volt单体18电压值";
CM_ SG_ 2564161288 NBICU08_Cell19Volt "Cell19Volt单体19电压值";
CM_ SG_ 2564161288 NBICU08_Cell20Volt "Cell20Volt单体20电压值";
CM_ BO_ 2564226824 "NBICU08 Tx and Cell Voltage06";
CM_ SG_ 2564226824 NBICU08_Cell21Volt "Cell21Volt单体21电压值";
CM_ SG_ 2564226824 NBICU08_Cell22Volt "Cell22Volt单体22电压值";
CM_ SG_ 2564226824 NBICU08_Cell23Volt "Cell23Volt单体23电压值";
CM_ SG_ 2564226824 NBICU08_Cell24Volt "Cell24Volt单体24电压值";
CM_ BO_ 2564292360 "NBICU08 Tx and Cell Voltage07";
CM_ SG_ 2564292360 NBICU08_Cell25Volt "Cell25Volt单体25电压值";
CM_ SG_ 2564292360 NBICU08_Cell26Volt "Cell26Volt单体26电压值";
CM_ SG_ 2564292360 NBICU08_Cell27Volt "Cell27Volt单体27电压值";
CM_ SG_ 2564292360 NBICU08_Cell28Volt "Cell28Volt单体28电压值";
CM_ BO_ 2564357896 "NBICU08 Tx and Cell Voltage08";
CM_ SG_ 2564357896 NBICU08_Cell29Volt "Cell29Volt单体29电压值";
CM_ SG_ 2564357896 NBICU08_Cell30Volt "Cell30Volt单体30电压值";
CM_ SG_ 2564357896 NBICU08_Cell31Volt "Cell31Volt单体31电压值";
CM_ SG_ 2564357896 NBICU08_Cell32Volt "Cell32Volt单体32电压值";
CM_ BO_ 2564423432 "NBICU08 Tx and Cell Voltage09";
CM_ SG_ 2564423432 NBICU08_Cell33Volt "Cell33Volt单体33电压值";
CM_ SG_ 2564423432 NBICU08_Cell34Volt "Cell34Volt单体34电压值";
CM_ SG_ 2564423432 NBICU08_Cell35Volt "Cell35Volt单体35电压值";
CM_ SG_ 2564423432 NBICU08_Cell36Volt "Cell36Volt单体36电压值";
CM_ BO_ 2564488968 "NBICU08 Tx and Cell Temp01";
CM_ SG_ 2564488968 NBICU08_Temp01 "NTC01-温度值";
CM_ SG_ 2564488968 NBICU08_Temp02 "NTC02-温度值";
CM_ SG_ 2564488968 NBICU08_Temp03 "NTC03-温度值";
CM_ SG_ 2564488968 NBICU08_Temp04 "NTC04-温度值";
CM_ SG_ 2564488968 NBICU08_Temp05 "NTC05-温度值";
CM_ SG_ 2564488968 NBICU08_Temp06 "NTC06-温度值";
CM_ SG_ 2564488968 NBICU08_Temp07 "NTC07-温度值";
CM_ SG_ 2564488968 NBICU08_Temp08 "NTC08-温度值";
CM_ BO_ 2564554504 "NBICU08 Tx and Cell Temp02";
CM_ SG_ 2564554504 NBICU08_Temp09 "NTC09-温度值";
CM_ SG_ 2564554504 NBICU08_Temp10 "NTC10-温度值";
CM_ SG_ 2564554504 NBICU08_Temp11 "NTC11-温度值";
CM_ SG_ 2564554504 NBICU08_Temp12 "NTC12-温度值";
CM_ SG_ 2564554504 NBICU08_Temp13 "NTC13-温度值";
CM_ SG_ 2564554504 NBICU08_Temp14 "NTC14-温度值";
CM_ SG_ 2564554504 NBICU08_Temp15 "NTC15-温度值";
CM_ SG_ 2564554504 NBICU08_Temp16 "NTC16-温度值";
CM_ BO_ 2564620040 "NBICU08 Tx and Cell Temp03";
CM_ SG_ 2564620040 NBICU08_Temp17 "NTC17-温度值";
CM_ SG_ 2564620040 NBICU08_Temp18 "NTC18-温度值";
CM_ SG_ 2564620040 NBICU08_Temp19 "NTC19-温度值";
CM_ SG_ 2564620040 NBICU08_Temp20 "NTC20-温度值";
CM_ SG_ 2564620040 NBICU08_Temp21 "NTC21-温度值";
CM_ SG_ 2564620040 NBICU08_Temp22 "NTC22-温度值";
CM_ SG_ 2564620040 NBICU08_Temp23 "NTC23-温度值";
CM_ SG_ 2564620040 NBICU08_Temp24 "NTC24-温度值";
CM_ BO_ 2564685576 "NBICU08 Tx and Cell Temp04";
CM_ SG_ 2564685576 NBICU08_Temp25 "NTC25-温度值";
CM_ SG_ 2564685576 NBICU08_Temp26 "NTC26-温度值";
CM_ SG_ 2564685576 NBICU08_Temp27 "NTC27-温度值";
CM_ SG_ 2564685576 NBICU08_Temp28 "NTC28-温度值";
CM_ SG_ 2564685576 NBICU08_Temp29 "NTC29-温度值";
CM_ SG_ 2564685576 NBICU08_Temp30 "NTC30-温度值";
CM_ SG_ 2564685576 NBICU08_Temp31 "NTC31-温度值";
CM_ SG_ 2564685576 NBICU08_Temp32 "NTC32-温度值";
CM_ BO_ 2564751112 "NBICU08 Tx and Cell Temp05";
CM_ SG_ 2564751112 NBICU08_Temp33 "NTC33-温度值";
CM_ SG_ 2564751112 NBICU08_Temp34 "NTC34-温度值";
CM_ SG_ 2564751112 NBICU08_Temp35 "NTC35-温度值";
CM_ SG_ 2564751112 NBICU08_Temp36 "NTC36-温度值";
CM_ BO_ 2564947720 "NBICU08 Tx and Software";
CM_ SG_ 2564947720 NBICU08_NBCMU_Addr_SW "NBICU08 NBCMU Address
NBICU08接收NBCMU地址";
CM_ SG_ 2564947720 NBICU08_SW01 "NBICU08 Software Byte 01
NBICU08软件版本第01字节";
CM_ SG_ 2564947720 NBICU08_SW02 "NBICU08 Software Byte 02
NBICU08软件版本第02字节";
CM_ SG_ 2564947720 NBICU08_SW03 "NBICU08 Software Byte 03
NBICU08软件版本第03字节";
CM_ SG_ 2564947720 NBICU08_SW04 "NBICU08 Software Byte 04
NBICU08软件版本第04字节";
CM_ SG_ 2564947720 NBICU08_SW05 "NBICU08 Software Byte 05
NBICU08软件版本第05字节";
CM_ SG_ 2564947720 NBICU08_SW06 "NBICU08 Software Byte 06
NBICU08软件版本第06字节";
CM_ SG_ 2564947720 NBICU08_SW07 "NBICU08 Software Byte 07
NBICU08软件版本第07字节";
CM_ BO_ 2565013256 "NBICU08 Tx and Hardware";
CM_ SG_ 2565013256 NBICU08_NBCMU_Addr_HW "NBICU08 NBCMU Address
NBICU08接收NBCMU地址";
CM_ SG_ 2565013256 NBICU08_HW01 "NBICU08 Hardware Byte 01
NBICU08硬件版本第01字节";
CM_ SG_ 2565013256 NBICU08_HW02 "NBICU08 Hardware Byte 02
NBICU08硬件版本第02字节";
CM_ SG_ 2565013256 NBICU08_HW03 "NBICU08 Hardware Byte 03
NBICU08硬件版本第03字节";
CM_ SG_ 2565013256 NBICU08_HW04 "NBICU08 Hardware Byte 04
NBICU08硬件版本第04字节";
CM_ SG_ 2565013256 NBICU08_HW05 "NBICU08 Hardware Byte 05
NBICU08硬件版本第05字节";
CM_ SG_ 2565013256 NBICU08_HW06 "NBICU08 Hardware Byte 06
NBICU08硬件版本第06字节";
CM_ SG_ 2565013256 NBICU08_HW07 "NBICU08 Hardware Byte 07
NBICU08硬件版本第07字节";
CM_ BO_ 2564677384 "NBICU08 Tx and DiaResponse";
CM_ BO_ 2562785033 "NBICU09 Tx and Run State";
CM_ SG_ 2562785033 NBICU09_Address "Address
从机地址";
CM_ SG_ 2562785033 NBICU09_CellVNum "CellVNum
配置电压采集串数";
CM_ SG_ 2562785033 NBICU09_TempNum "TempNum
配置温度采集个数";
CM_ SG_ 2562785033 NBICU09_ErrFlag "ErrFlag
故障标志(预留)";
CM_ SG_ 2562785033 NBICU09_AddrInput_State "Addr Input_State
检测地址状态";
CM_ SG_ 2562785033 NBICU09_AddrOutput_State "Addr Output_State
输出地址状态";
CM_ SG_ 2562785033 NBICU09_HSD01Sta "HSD01
高边1控制状态(预留)";
CM_ SG_ 2562785033 NBICU09_SoftVer "SoftVer
软件版本";
CM_ SG_ 2562785033 NBICU09_HardVer "HardVer
硬件版本";
CM_ SG_ 2562785033 NBICU09_RunAlivCoun "AliveCounter
心跳指数";
CM_ BO_ 2562850569 "NBICU09 Tx and VoltExtremeInfo";
CM_ SG_ 2562850569 NBICU09_CellVoltMax "最高单体电压";
CM_ SG_ 2562850569 NBICU09_CellVoltMin "最低单体电压";
CM_ SG_ 2562850569 NBICU09_CellVoltMaxCode "最高单体电压序号";
CM_ SG_ 2562850569 NBICU09_CellVoltMinCode "最低单体电压序号";
CM_ SG_ 2562850569 NBICU09_CellSumVolt "电池包累计总压";
CM_ BO_ 2562916105 "NBICU09 Tx and TempExtremeInfo";
CM_ SG_ 2562916105 NBICU09_CellTempMax "最高温度";
CM_ SG_ 2562916105 NBICU09_CellTempMin "最低温度";
CM_ SG_ 2562916105 NBICU09_CellTempAvg "平均温度";
CM_ SG_ 2562916105 NBICU09_CellTempMaxCode "最高温度序号";
CM_ SG_ 2562916105 NBICU09_CellTempMinCode "最低温度序号";
CM_ SG_ 2562916105 NBICU09_SupplyVolt "供电电压";
CM_ SG_ 2562916105 NBICU09_PCB_Temp "板载温度";
CM_ BO_ 2562981641 "NBICU09 Tx and Balance State";
CM_ SG_ 2562981641 NBICU09_Cell0108BalaSta "Cell0108BalaSta
单体1至8通道均衡状态";
CM_ SG_ 2562981641 NBICU09_Cell0916BalaSta "Cell0916BalaSta
单体9至16通道均衡标志";
CM_ SG_ 2562981641 NBICU09_Cell1724BalaSta "Cell1724BalaSta
单体17至24通道均衡状态";
CM_ SG_ 2562981641 NBICU09_Cell2532BalaSta "Cell2532BalaSta
单体25至32通道均衡状态";
CM_ SG_ 2562981641 NBICU09_Cell3336BalaSta "Cell3336BalaSta
单体33至36通道均衡状态";
CM_ SG_ 2562981641 NBICU09_SysSOH "Sys SOH
电池包SOH";
CM_ SG_ 2562981641 NBICU09_CycleTime "CycleTime
循环次数";
CM_ BO_ 2563899145 "NBICU09 Tx and Cell Voltage01";
CM_ SG_ 2563899145 NBICU09_Cell01Volt "Cell01Volt单体01电压值";
CM_ SG_ 2563899145 NBICU09_Cell02Volt "Cell02Volt单体02电压值";
CM_ SG_ 2563899145 NBICU09_Cell03Volt "Cell03Volt单体03电压值";
CM_ SG_ 2563899145 NBICU09_Cell04Volt "Cell04Volt单体04电压值";
CM_ BO_ 2563964681 "NBICU09 Tx and Cell Voltage02";
CM_ SG_ 2563964681 NBICU09_Cell05Volt "Cell05Volt单体05电压值";
CM_ SG_ 2563964681 NBICU09_Cell06Volt "Cell06Volt单体06电压值";
CM_ SG_ 2563964681 NBICU09_Cell07Volt "Cell07Volt单体07电压值";
CM_ SG_ 2563964681 NBICU09_Cell08Volt "Cell08Volt单体08电压值";
CM_ BO_ 2564030217 "NBICU09 Tx and Cell Voltage03";
CM_ SG_ 2564030217 NBICU09_Cell09Volt "Cell09Volt单体09电压值";
CM_ SG_ 2564030217 NBICU09_Cell10Volt "Cell10Volt单体10电压值";
CM_ SG_ 2564030217 NBICU09_Cell11Volt "Cell11Volt单体11电压值";
CM_ SG_ 2564030217 NBICU09_Cell12Volt "Cell12Volt单体12电压值";
CM_ BO_ 2564095753 "NBICU09 Tx and Cell Voltage04";
CM_ SG_ 2564095753 NBICU09_Cell13Volt "Cell13Volt单体13电压值";
CM_ SG_ 2564095753 NBICU09_Cell14Volt "Cell14Volt单体14电压值";
CM_ SG_ 2564095753 NBICU09_Cell15Volt "Cell15Volt单体15电压值";
CM_ SG_ 2564095753 NBICU09_Cell16Volt "Cell16Volt单体16电压值";
CM_ BO_ 2564161289 "NBICU09 Tx and Cell Voltage05";
CM_ SG_ 2564161289 NBICU09_Cell17Volt "Cell17Volt单体17电压值";
CM_ SG_ 2564161289 NBICU09_Cell18Volt "Cell18Volt单体18电压值";
CM_ SG_ 2564161289 NBICU09_Cell19Volt "Cell19Volt单体19电压值";
CM_ SG_ 2564161289 NBICU09_Cell20Volt "Cell20Volt单体20电压值";
CM_ BO_ 2564226825 "NBICU09 Tx and Cell Voltage06";
CM_ SG_ 2564226825 NBICU09_Cell21Volt "Cell21Volt单体21电压值";
CM_ SG_ 2564226825 NBICU09_Cell22Volt "Cell22Volt单体22电压值";
CM_ SG_ 2564226825 NBICU09_Cell23Volt "Cell23Volt单体23电压值";
CM_ SG_ 2564226825 NBICU09_Cell24Volt "Cell24Volt单体24电压值";
CM_ BO_ 2564292361 "NBICU09 Tx and Cell Voltage07";
CM_ SG_ 2564292361 NBICU09_Cell25Volt "Cell25Volt单体25电压值";
CM_ SG_ 2564292361 NBICU09_Cell26Volt "Cell26Volt单体26电压值";
CM_ SG_ 2564292361 NBICU09_Cell27Volt "Cell27Volt单体27电压值";
CM_ SG_ 2564292361 NBICU09_Cell28Volt "Cell28Volt单体28电压值";
CM_ BO_ 2564357897 "NBICU09 Tx and Cell Voltage08";
CM_ SG_ 2564357897 NBICU09_Cell29Volt "Cell29Volt单体29电压值";
CM_ SG_ 2564357897 NBICU09_Cell30Volt "Cell30Volt单体30电压值";
CM_ SG_ 2564357897 NBICU09_Cell31Volt "Cell31Volt单体31电压值";
CM_ SG_ 2564357897 NBICU09_Cell32Volt "Cell32Volt单体32电压值";
CM_ BO_ 2564423433 "NBICU09 Tx and Cell Voltage09";
CM_ SG_ 2564423433 NBICU09_Cell33Volt "Cell33Volt单体33电压值";
CM_ SG_ 2564423433 NBICU09_Cell34Volt "Cell34Volt单体34电压值";
CM_ SG_ 2564423433 NBICU09_Cell35Volt "Cell35Volt单体35电压值";
CM_ SG_ 2564423433 NBICU09_Cell36Volt "Cell36Volt单体36电压值";
CM_ BO_ 2564488969 "NBICU09 Tx and Cell Temp01";
CM_ SG_ 2564488969 NBICU09_Temp01 "NTC01-温度值";
CM_ SG_ 2564488969 NBICU09_Temp02 "NTC02-温度值";
CM_ SG_ 2564488969 NBICU09_Temp03 "NTC03-温度值";
CM_ SG_ 2564488969 NBICU09_Temp04 "NTC04-温度值";
CM_ SG_ 2564488969 NBICU09_Temp05 "NTC05-温度值";
CM_ SG_ 2564488969 NBICU09_Temp06 "NTC06-温度值";
CM_ SG_ 2564488969 NBICU09_Temp07 "NTC07-温度值";
CM_ SG_ 2564488969 NBICU09_Temp08 "NTC08-温度值";
CM_ BO_ 2564554505 "NBICU09 Tx and Cell Temp02";
CM_ SG_ 2564554505 NBICU09_Temp09 "NTC09-温度值";
CM_ SG_ 2564554505 NBICU09_Temp10 "NTC10-温度值";
CM_ SG_ 2564554505 NBICU09_Temp11 "NTC11-温度值";
CM_ SG_ 2564554505 NBICU09_Temp12 "NTC12-温度值";
CM_ SG_ 2564554505 NBICU09_Temp13 "NTC13-温度值";
CM_ SG_ 2564554505 NBICU09_Temp14 "NTC14-温度值";
CM_ SG_ 2564554505 NBICU09_Temp15 "NTC15-温度值";
CM_ SG_ 2564554505 NBICU09_Temp16 "NTC16-温度值";
CM_ BO_ 2564620041 "NBICU09 Tx and Cell Temp03";
CM_ SG_ 2564620041 NBICU09_Temp17 "NTC17-温度值";
CM_ SG_ 2564620041 NBICU09_Temp18 "NTC18-温度值";
CM_ SG_ 2564620041 NBICU09_Temp19 "NTC19-温度值";
CM_ SG_ 2564620041 NBICU09_Temp20 "NTC20-温度值";
CM_ SG_ 2564620041 NBICU09_Temp21 "NTC21-温度值";
CM_ SG_ 2564620041 NBICU09_Temp22 "NTC22-温度值";
CM_ SG_ 2564620041 NBICU09_Temp23 "NTC23-温度值";
CM_ SG_ 2564620041 NBICU09_Temp24 "NTC24-温度值";
CM_ BO_ 2564685577 "NBICU09 Tx and Cell Temp04";
CM_ SG_ 2564685577 NBICU09_Temp25 "NTC25-温度值";
CM_ SG_ 2564685577 NBICU09_Temp26 "NTC26-温度值";
CM_ SG_ 2564685577 NBICU09_Temp27 "NTC27-温度值";
CM_ SG_ 2564685577 NBICU09_Temp28 "NTC28-温度值";
CM_ SG_ 2564685577 NBICU09_Temp29 "NTC29-温度值";
CM_ SG_ 2564685577 NBICU09_Temp30 "NTC30-温度值";
CM_ SG_ 2564685577 NBICU09_Temp31 "NTC31-温度值";
CM_ SG_ 2564685577 NBICU09_Temp32 "NTC32-温度值";
CM_ BO_ 2564751113 "NBICU09 Tx and Cell Temp05";
CM_ SG_ 2564751113 NBICU09_Temp33 "NTC33-温度值";
CM_ SG_ 2564751113 NBICU09_Temp34 "NTC34-温度值";
CM_ SG_ 2564751113 NBICU09_Temp35 "NTC35-温度值";
CM_ SG_ 2564751113 NBICU09_Temp36 "NTC36-温度值";
CM_ BO_ 2564947721 "NBICU09 Tx and Software";
CM_ SG_ 2564947721 NBICU09_NBCMU_Addr_SW "NBICU09 NBCMU Address
NBICU09接收NBCMU地址";
CM_ SG_ 2564947721 NBICU09_SW01 "NBICU09 Software Byte 01
NBICU09软件版本第01字节";
CM_ SG_ 2564947721 NBICU09_SW02 "NBICU09 Software Byte 02
NBICU09软件版本第02字节";
CM_ SG_ 2564947721 NBICU09_SW03 "NBICU09 Software Byte 03
NBICU09软件版本第03字节";
CM_ SG_ 2564947721 NBICU09_SW04 "NBICU09 Software Byte 04
NBICU09软件版本第04字节";
CM_ SG_ 2564947721 NBICU09_SW05 "NBICU09 Software Byte 05
NBICU09软件版本第05字节";
CM_ SG_ 2564947721 NBICU09_SW06 "NBICU09 Software Byte 06
NBICU09软件版本第06字节";
CM_ SG_ 2564947721 NBICU09_SW07 "NBICU09 Software Byte 07
NBICU09软件版本第07字节";
CM_ BO_ 2565013257 "NBICU09 Tx and Hardware";
CM_ SG_ 2565013257 NBICU09_NBCMU_Addr_HW "NBICU09 NBCMU Address
NBICU09接收NBCMU地址";
CM_ SG_ 2565013257 NBICU09_HW01 "NBICU09 Hardware Byte 01
NBICU09硬件版本第01字节";
CM_ SG_ 2565013257 NBICU09_HW02 "NBICU09 Hardware Byte 02
NBICU09硬件版本第02字节";
CM_ SG_ 2565013257 NBICU09_HW03 "NBICU09 Hardware Byte 03
NBICU09硬件版本第03字节";
CM_ SG_ 2565013257 NBICU09_HW04 "NBICU09 Hardware Byte 04
NBICU09硬件版本第04字节";
CM_ SG_ 2565013257 NBICU09_HW05 "NBICU09 Hardware Byte 05
NBICU09硬件版本第05字节";
CM_ SG_ 2565013257 NBICU09_HW06 "NBICU09 Hardware Byte 06
NBICU09硬件版本第06字节";
CM_ SG_ 2565013257 NBICU09_HW07 "NBICU09 Hardware Byte 07
NBICU09硬件版本第07字节";
CM_ BO_ 2564677385 "NBICU09 Tx and DiaResponse";
CM_ BO_ 2562785034 "NBICU10 Tx and Run State";
CM_ SG_ 2562785034 NBICU10_Address "Address
从机地址";
CM_ SG_ 2562785034 NBICU10_CellVNum "CellVNum
配置电压采集串数";
CM_ SG_ 2562785034 NBICU10_TempNum "TempNum
配置温度采集个数";
CM_ SG_ 2562785034 NBICU10_ErrFlag "ErrFlag
故障标志(预留)";
CM_ SG_ 2562785034 NBICU10_AddrInput_State "Addr Input_State
检测地址状态";
CM_ SG_ 2562785034 NBICU10_AddrOutput_State "Addr Output_State
输出地址状态";
CM_ SG_ 2562785034 NBICU10_HSD01Sta "HSD01
高边1控制状态(预留)";
CM_ SG_ 2562785034 NBICU10_SoftVer "SoftVer
软件版本";
CM_ SG_ 2562785034 NBICU10_HardVer "HardVer
硬件版本";
CM_ SG_ 2562785034 NBICU10_RunAlivCoun "AliveCounter
心跳指数";
CM_ BO_ 2562850570 "NBICU10 Tx and VoltExtremeInfo";
CM_ SG_ 2562850570 NBICU10_CellVoltMax "最高单体电压";
CM_ SG_ 2562850570 NBICU10_CellVoltMin "最低单体电压";
CM_ SG_ 2562850570 NBICU10_CellVoltMaxCode "最高单体电压序号";
CM_ SG_ 2562850570 NBICU10_CellVoltMinCode "最低单体电压序号";
CM_ SG_ 2562850570 NBICU10_CellSumVolt "电池包累计总压";
CM_ BO_ 2562916106 "NBICU10 Tx and TempExtremeInfo";
CM_ SG_ 2562916106 NBICU10_CellTempMax "最高温度";
CM_ SG_ 2562916106 NBICU10_CellTempMin "最低温度";
CM_ SG_ 2562916106 NBICU10_CellTempAvg "平均温度";
CM_ SG_ 2562916106 NBICU10_CellTempMaxCode "最高温度序号";
CM_ SG_ 2562916106 NBICU10_CellTempMinCode "最低温度序号";
CM_ SG_ 2562916106 NBICU10_SupplyVolt "供电电压";
CM_ SG_ 2562916106 NBICU10_PCB_Temp "板载温度";
CM_ BO_ 2562981642 "NBICU10 Tx and Balance State";
CM_ SG_ 2562981642 NBICU10_Cell0108BalaSta "Cell0108BalaSta
单体1至8通道均衡状态";
CM_ SG_ 2562981642 NBICU10_Cell0916BalaSta "Cell0916BalaSta
单体9至16通道均衡标志";
CM_ SG_ 2562981642 NBICU10_Cell1724BalaSta "Cell1724BalaSta
单体17至24通道均衡状态";
CM_ SG_ 2562981642 NBICU10_Cell2532BalaSta "Cell2532BalaSta
单体25至32通道均衡状态";
CM_ SG_ 2562981642 NBICU10_Cell3336BalaSta "Cell3336BalaSta
单体33至36通道均衡状态";
CM_ SG_ 2562981642 NBICU10_SysSOH "Sys SOH
电池包SOH";
CM_ SG_ 2562981642 NBICU10_CycleTime "CycleTime
循环次数";
CM_ BO_ 2563899146 "NBICU10 Tx and Cell Voltage01";
CM_ SG_ 2563899146 NBICU10_Cell01Volt "Cell01Volt单体01电压值";
CM_ SG_ 2563899146 NBICU10_Cell02Volt "Cell02Volt单体02电压值";
CM_ SG_ 2563899146 NBICU10_Cell03Volt "Cell03Volt单体03电压值";
CM_ SG_ 2563899146 NBICU10_Cell04Volt "Cell04Volt单体04电压值";
CM_ BO_ 2563964682 "NBICU10 Tx and Cell Voltage02";
CM_ SG_ 2563964682 NBICU10_Cell05Volt "Cell05Volt单体05电压值";
CM_ SG_ 2563964682 NBICU10_Cell06Volt "Cell06Volt单体06电压值";
CM_ SG_ 2563964682 NBICU10_Cell07Volt "Cell07Volt单体07电压值";
CM_ SG_ 2563964682 NBICU10_Cell08Volt "Cell08Volt单体08电压值";
CM_ BO_ 2564030218 "NBICU10 Tx and Cell Voltage03";
CM_ SG_ 2564030218 NBICU10_Cell09Volt "Cell09Volt单体09电压值";
CM_ SG_ 2564030218 NBICU10_Cell10Volt "Cell10Volt单体10电压值";
CM_ SG_ 2564030218 NBICU10_Cell11Volt "Cell11Volt单体11电压值";
CM_ SG_ 2564030218 NBICU10_Cell12Volt "Cell12Volt单体12电压值";
CM_ BO_ 2564095754 "NBICU10 Tx and Cell Voltage04";
CM_ SG_ 2564095754 NBICU10_Cell13Volt "Cell13Volt单体13电压值";
CM_ SG_ 2564095754 NBICU10_Cell14Volt "Cell14Volt单体14电压值";
CM_ SG_ 2564095754 NBICU10_Cell15Volt "Cell15Volt单体15电压值";
CM_ SG_ 2564095754 NBICU10_Cell16Volt "Cell16Volt单体16电压值";
CM_ BO_ 2564161290 "NBICU10 Tx and Cell Voltage05";
CM_ SG_ 2564161290 NBICU10_Cell17Volt "Cell17Volt单体17电压值";
CM_ SG_ 2564161290 NBICU10_Cell18Volt "Cell18Volt单体18电压值";
CM_ SG_ 2564161290 NBICU10_Cell19Volt "Cell19Volt单体19电压值";
CM_ SG_ 2564161290 NBICU10_Cell20Volt "Cell20Volt单体20电压值";
CM_ BO_ 2564226826 "NBICU10 Tx and Cell Voltage06";
CM_ SG_ 2564226826 NBICU10_Cell21Volt "Cell21Volt单体21电压值";
CM_ SG_ 2564226826 NBICU10_Cell22Volt "Cell22Volt单体22电压值";
CM_ SG_ 2564226826 NBICU10_Cell23Volt "Cell23Volt单体23电压值";
CM_ SG_ 2564226826 NBICU10_Cell24Volt "Cell24Volt单体24电压值";
CM_ BO_ 2564292362 "NBICU10 Tx and Cell Voltage07";
CM_ SG_ 2564292362 NBICU10_Cell25Volt "Cell25Volt单体25电压值";
CM_ SG_ 2564292362 NBICU10_Cell26Volt "Cell26Volt单体26电压值";
CM_ SG_ 2564292362 NBICU10_Cell27Volt "Cell27Volt单体27电压值";
CM_ SG_ 2564292362 NBICU10_Cell28Volt "Cell28Volt单体28电压值";
BA_DEF_ SG_  "GenSigSendType" ENUM  "Cycle","OnChangeWithRepetition","OnChange","OnWriteWithRepetition","OnWrite","IfActiveWithRepetition","IfActive";
BA_DEF_ BO_  "GenMsgSendType" ENUM  "Cycle","Event","CycleEvent","IfActive";
BA_DEF_ BO_  "GenMsgCycleTime" INT 0 65536;
BA_DEF_  "BusType" STRING ;
BA_DEF_ SG_  "SystemSignalLongSymbol" STRING ;
BA_DEF_DEF_  "GenSigSendType" "Cycle";
BA_DEF_DEF_  "GenMsgSendType" "Cycle";
BA_DEF_DEF_  "GenMsgCycleTime" 0;
BA_DEF_DEF_  "BusType" "CAN";
BA_DEF_DEF_  "SystemSignalLongSymbol" "";
BA_ "GenMsgCycleTime" BO_ 2562785025 100;
BA_ "GenMsgCycleTime" BO_ 2562850561 50;
BA_ "GenMsgCycleTime" BO_ 2562916097 500;
BA_ "GenMsgCycleTime" BO_ 2562981633 100;
BA_ "GenMsgCycleTime" BO_ 2563899137 200;
BA_ "GenMsgCycleTime" BO_ 2563964673 200;
BA_ "GenMsgCycleTime" BO_ 2564030209 200;
BA_ "GenMsgCycleTime" BO_ 2564095745 200;
BA_ "GenMsgCycleTime" BO_ 2564161281 200;
BA_ "GenMsgCycleTime" BO_ 2564226817 200;
BA_ "GenMsgCycleTime" BO_ 2564292353 200;
BA_ "GenMsgCycleTime" BO_ 2564357889 200;
BA_ "GenMsgCycleTime" BO_ 2564423425 200;
BA_ "GenMsgCycleTime" BO_ 2564488961 1000;
BA_ "GenMsgCycleTime" BO_ 2564554497 1000;
BA_ "GenMsgCycleTime" BO_ 2564620033 1000;
BA_ "GenMsgCycleTime" BO_ 2564685569 1000;
BA_ "GenMsgCycleTime" BO_ 2564751105 1000;
BA_ "GenMsgCycleTime" BO_ 2564947713 5000;
BA_ "GenMsgCycleTime" BO_ 2565013249 5000;
BA_ "GenMsgSendType" BO_ 2564677377 1;
BA_ "GenMsgCycleTime" BO_ 2562785026 100;
BA_ "GenMsgCycleTime" BO_ 2562850562 50;
BA_ "GenMsgCycleTime" BO_ 2562916098 500;
BA_ "GenMsgCycleTime" BO_ 2562981634 100;
BA_ "GenMsgCycleTime" BO_ 2563899138 200;
BA_ "GenMsgCycleTime" BO_ 2563964674 200;
BA_ "GenMsgCycleTime" BO_ 2564030210 200;
BA_ "GenMsgCycleTime" BO_ 2564095746 200;
BA_ "GenMsgCycleTime" BO_ 2564161282 200;
BA_ "GenMsgCycleTime" BO_ 2564226818 200;
BA_ "GenMsgCycleTime" BO_ 2564292354 200;
BA_ "GenMsgCycleTime" BO_ 2564357890 200;
BA_ "GenMsgCycleTime" BO_ 2564423426 200;
BA_ "GenMsgCycleTime" BO_ 2564488962 1000;
BA_ "GenMsgCycleTime" BO_ 2564554498 1000;
BA_ "GenMsgCycleTime" BO_ 2564620034 1000;
BA_ "GenMsgCycleTime" BO_ 2564685570 1000;
BA_ "GenMsgCycleTime" BO_ 2564751106 1000;
BA_ "GenMsgCycleTime" BO_ 2564947714 5000;
BA_ "GenMsgCycleTime" BO_ 2565013250 5000;
BA_ "GenMsgSendType" BO_ 2564677378 1;
BA_ "GenMsgCycleTime" BO_ 2562785027 100;
BA_ "GenMsgCycleTime" BO_ 2562850563 50;
BA_ "GenMsgCycleTime" BO_ 2562916099 500;
BA_ "GenMsgCycleTime" BO_ 2562981635 100;
BA_ "GenMsgCycleTime" BO_ 2563899139 200;
BA_ "GenMsgCycleTime" BO_ 2563964675 200;
BA_ "GenMsgCycleTime" BO_ 2564030211 200;
BA_ "GenMsgCycleTime" BO_ 2564095747 200;
BA_ "GenMsgCycleTime" BO_ 2564161283 200;
BA_ "GenMsgCycleTime" BO_ 2564226819 200;
BA_ "GenMsgCycleTime" BO_ 2564292355 200;
BA_ "GenMsgCycleTime" BO_ 2564357891 200;
BA_ "GenMsgCycleTime" BO_ 2564423427 200;
BA_ "GenMsgCycleTime" BO_ 2564488963 1000;
BA_ "GenMsgCycleTime" BO_ 2564554499 1000;
BA_ "GenMsgCycleTime" BO_ 2564620035 1000;
BA_ "GenMsgCycleTime" BO_ 2564685571 1000;
BA_ "GenMsgCycleTime" BO_ 2564751107 1000;
BA_ "GenMsgCycleTime" BO_ 2564947715 5000;
BA_ "GenMsgCycleTime" BO_ 2565013251 5000;
BA_ "GenMsgSendType" BO_ 2564677379 1;
BA_ "GenMsgCycleTime" BO_ 2562785028 100;
BA_ "GenMsgCycleTime" BO_ 2562850564 50;
BA_ "GenMsgCycleTime" BO_ 2562916100 500;
BA_ "GenMsgCycleTime" BO_ 2562981636 100;
BA_ "GenMsgCycleTime" BO_ 2563899140 200;
BA_ "GenMsgCycleTime" BO_ 2563964676 200;
BA_ "GenMsgCycleTime" BO_ 2564030212 200;
BA_ "GenMsgCycleTime" BO_ 2564095748 200;
BA_ "GenMsgCycleTime" BO_ 2564161284 200;
BA_ "GenMsgCycleTime" BO_ 2564226820 200;
BA_ "GenMsgCycleTime" BO_ 2564292356 200;
BA_ "GenMsgCycleTime" BO_ 2564357892 200;
BA_ "GenMsgCycleTime" BO_ 2564423428 200;
BA_ "GenMsgCycleTime" BO_ 2564488964 1000;
BA_ "GenMsgCycleTime" BO_ 2564554500 1000;
BA_ "GenMsgCycleTime" BO_ 2564620036 1000;
BA_ "GenMsgCycleTime" BO_ 2564685572 1000;
BA_ "GenMsgCycleTime" BO_ 2564751108 1000;
BA_ "GenMsgCycleTime" BO_ 2564947716 5000;
BA_ "GenMsgCycleTime" BO_ 2565013252 5000;
BA_ "GenMsgSendType" BO_ 2564677380 1;
BA_ "GenMsgCycleTime" BO_ 2562785029 100;
BA_ "GenMsgCycleTime" BO_ 2562850565 50;
BA_ "GenMsgCycleTime" BO_ 2562916101 500;
BA_ "GenMsgCycleTime" BO_ 2562981637 100;
BA_ "GenMsgCycleTime" BO_ 2563899141 200;
BA_ "GenMsgCycleTime" BO_ 2563964677 200;
BA_ "GenMsgCycleTime" BO_ 2564030213 200;
BA_ "GenMsgCycleTime" BO_ 2564095749 200;
BA_ "GenMsgCycleTime" BO_ 2564161285 200;
BA_ "GenMsgCycleTime" BO_ 2564226821 200;
BA_ "GenMsgCycleTime" BO_ 2564292357 200;
BA_ "GenMsgCycleTime" BO_ 2564357893 200;
BA_ "GenMsgCycleTime" BO_ 2564423429 200;
BA_ "GenMsgCycleTime" BO_ 2564488965 1000;
BA_ "GenMsgCycleTime" BO_ 2564554501 1000;
BA_ "GenMsgCycleTime" BO_ 2564620037 1000;
BA_ "GenMsgCycleTime" BO_ 2564685573 1000;
BA_ "GenMsgCycleTime" BO_ 2564751109 1000;
BA_ "GenMsgCycleTime" BO_ 2564947717 5000;
BA_ "GenMsgCycleTime" BO_ 2565013253 5000;
BA_ "GenMsgSendType" BO_ 2564677381 1;
BA_ "GenMsgCycleTime" BO_ 2562785030 100;
BA_ "GenMsgCycleTime" BO_ 2562850566 50;
BA_ "GenMsgCycleTime" BO_ 2562916102 500;
BA_ "GenMsgCycleTime" BO_ 2562981638 100;
BA_ "GenMsgCycleTime" BO_ 2563899142 200;
BA_ "GenMsgCycleTime" BO_ 2563964678 200;
BA_ "GenMsgCycleTime" BO_ 2564030214 200;
BA_ "GenMsgCycleTime" BO_ 2564095750 200;
BA_ "GenMsgCycleTime" BO_ 2564161286 200;
BA_ "GenMsgCycleTime" BO_ 2564226822 200;
BA_ "GenMsgCycleTime" BO_ 2564292358 200;
BA_ "GenMsgCycleTime" BO_ 2564357894 200;
BA_ "GenMsgCycleTime" BO_ 2564423430 200;
BA_ "GenMsgCycleTime" BO_ 2564488966 1000;
BA_ "GenMsgCycleTime" BO_ 2564554502 1000;
BA_ "GenMsgCycleTime" BO_ 2564620038 1000;
BA_ "GenMsgCycleTime" BO_ 2564685574 1000;
BA_ "GenMsgCycleTime" BO_ 2564751110 1000;
BA_ "GenMsgCycleTime" BO_ 2564947718 5000;
BA_ "GenMsgCycleTime" BO_ 2565013254 5000;
BA_ "GenMsgSendType" BO_ 2564677382 1;
BA_ "GenMsgCycleTime" BO_ 2562785031 100;
BA_ "GenMsgCycleTime" BO_ 2562850567 50;
BA_ "GenMsgCycleTime" BO_ 2562916103 500;
BA_ "GenMsgCycleTime" BO_ 2562981639 100;
BA_ "GenMsgCycleTime" BO_ 2563899143 200;
BA_ "GenMsgCycleTime" BO_ 2563964679 200;
BA_ "GenMsgCycleTime" BO_ 2564030215 200;
BA_ "GenMsgCycleTime" BO_ 2564095751 200;
BA_ "GenMsgCycleTime" BO_ 2564161287 200;
BA_ "GenMsgCycleTime" BO_ 2564226823 200;
BA_ "GenMsgCycleTime" BO_ 2564292359 200;
BA_ "GenMsgCycleTime" BO_ 2564357895 200;
BA_ "GenMsgCycleTime" BO_ 2564423431 200;
BA_ "GenMsgCycleTime" BO_ 2564488967 1000;
BA_ "GenMsgCycleTime" BO_ 2564554503 1000;
BA_ "GenMsgCycleTime" BO_ 2564620039 1000;
BA_ "GenMsgCycleTime" BO_ 2564685575 1000;
BA_ "GenMsgCycleTime" BO_ 2564751111 1000;
BA_ "GenMsgCycleTime" BO_ 2564947719 5000;
BA_ "GenMsgCycleTime" BO_ 2565013255 5000;
BA_ "GenMsgSendType" BO_ 2564677383 1;
BA_ "GenMsgCycleTime" BO_ 2562785032 100;
BA_ "GenMsgCycleTime" BO_ 2562850568 50;
BA_ "GenMsgCycleTime" BO_ 2562916104 500;
BA_ "GenMsgCycleTime" BO_ 2562981640 100;
BA_ "GenMsgCycleTime" BO_ 2563899144 200;
BA_ "GenMsgCycleTime" BO_ 2563964680 200;
BA_ "GenMsgCycleTime" BO_ 2564030216 200;
BA_ "GenMsgCycleTime" BO_ 2564095752 200;
BA_ "GenMsgCycleTime" BO_ 2564161288 200;
BA_ "GenMsgCycleTime" BO_ 2564226824 200;
BA_ "GenMsgCycleTime" BO_ 2564292360 200;
BA_ "GenMsgCycleTime" BO_ 2564357896 200;
BA_ "GenMsgCycleTime" BO_ 2564423432 200;
BA_ "GenMsgCycleTime" BO_ 2564488968 1000;
BA_ "GenMsgCycleTime" BO_ 2564554504 1000;
BA_ "GenMsgCycleTime" BO_ 2564620040 1000;
BA_ "GenMsgCycleTime" BO_ 2564685576 1000;
BA_ "GenMsgCycleTime" BO_ 2564751112 1000;
BA_ "GenMsgCycleTime" BO_ 2564947720 5000;
BA_ "GenMsgCycleTime" BO_ 2565013256 5000;
BA_ "GenMsgSendType" BO_ 2564677384 1;
BA_ "GenMsgCycleTime" BO_ 2562785033 100;
BA_ "GenMsgCycleTime" BO_ 2562850569 50;
BA_ "GenMsgCycleTime" BO_ 2562916105 500;
BA_ "GenMsgCycleTime" BO_ 2562981641 100;
BA_ "GenMsgCycleTime" BO_ 2563899145 200;
BA_ "GenMsgCycleTime" BO_ 2563964681 200;
BA_ "GenMsgCycleTime" BO_ 2564030217 200;
BA_ "GenMsgCycleTime" BO_ 2564095753 200;
BA_ "GenMsgCycleTime" BO_ 2564161289 200;
BA_ "GenMsgCycleTime" BO_ 2564226825 200;
BA_ "GenMsgCycleTime" BO_ 2564292361 200;
BA_ "GenMsgCycleTime" BO_ 2564357897 200;
BA_ "GenMsgCycleTime" BO_ 2564423433 200;
BA_ "GenMsgCycleTime" BO_ 2564488969 1000;
BA_ "GenMsgCycleTime" BO_ 2564554505 1000;
BA_ "GenMsgCycleTime" BO_ 2564620041 1000;
BA_ "GenMsgCycleTime" BO_ 2564685577 1000;
BA_ "GenMsgCycleTime" BO_ 2564751113 1000;
BA_ "GenMsgCycleTime" BO_ 2564947721 5000;
BA_ "GenMsgCycleTime" BO_ 2565013257 5000;
BA_ "GenMsgSendType" BO_ 2564677385 1;
BA_ "GenMsgCycleTime" BO_ 2562785034 100;
BA_ "GenMsgCycleTime" BO_ 2562850570 50;
BA_ "GenMsgCycleTime" BO_ 2562916106 500;
BA_ "GenMsgCycleTime" BO_ 2562981642 100;
BA_ "GenMsgCycleTime" BO_ 2563899146 200;
BA_ "GenMsgCycleTime" BO_ 2563964682 200;
BA_ "GenMsgCycleTime" BO_ 2564030218 200;
BA_ "GenMsgCycleTime" BO_ 2564095754 200;
BA_ "GenMsgCycleTime" BO_ 2564161290 200;
BA_ "GenMsgCycleTime" BO_ 2564226826 200;
BA_ "GenMsgCycleTime" BO_ 2564292362 200;
VAL_ 2562785025 NBICU01_AddrInput_State 0 " Disable " 1 " Enable " ;
VAL_ 2562785025 NBICU01_AddrOutput_State 0 " Disable " 1 " Enable " ;
VAL_ 2562785026 NBICU02_AddrInput_State 0 " Disable " 1 " Enable " ;
VAL_ 2562785026 NBICU02_AddrOutput_State 0 " Disable " 1 " Enable " ;
VAL_ 2562785027 NBICU03_AddrInput_State 0 " Disable " 1 " Enable " ;
VAL_ 2562785027 NBICU03_AddrOutput_State 0 " Disable " 1 " Enable " ;
VAL_ 2562785028 NBICU04_AddrInput_State 0 " Disable " 1 " Enable " ;
VAL_ 2562785028 NBICU04_AddrOutput_State 0 " Disable " 1 " Enable " ;
VAL_ 2562785029 NBICU05_AddrInput_State 0 " Disable " 1 " Enable " ;
VAL_ 2562785029 NBICU05_AddrOutput_State 0 " Disable " 1 " Enable " ;
VAL_ 2562785030 NBICU06_AddrInput_State 0 " Disable " 1 " Enable " ;
VAL_ 2562785030 NBICU06_AddrOutput_State 0 " Disable " 1 " Enable " ;
VAL_ 2562785031 NBICU07_AddrInput_State 0 " Disable " 1 " Enable " ;
VAL_ 2562785031 NBICU07_AddrOutput_State 0 " Disable " 1 " Enable " ;
VAL_ 2562785032 NBICU08_AddrInput_State 0 " Disable " 1 " Enable " ;
VAL_ 2562785032 NBICU08_AddrOutput_State 0 " Disable " 1 " Enable " ;
VAL_ 2562785033 NBICU09_AddrInput_State 0 " Disable " 1 " Enable " ;
VAL_ 2562785033 NBICU09_AddrOutput_State 0 " Disable " 1 " Enable " ;
VAL_ 2562785034 NBICU10_AddrInput_State 0 " Disable " 1 " Enable " ;
VAL_ 2562785034 NBICU10_AddrOutput_State 0 " Disable " 1 " Enable " ;
